VERSION ""

NS_ :

BS_:

BU_: ALARMS_RELAY RUR RUF LOGBOX HVAC CP6 CP10 RUC BC BMS1_SDB BMS2_SDB BMS0_SDB _TESTER NC_SENSOR IVS

BO_ 2558533943 CP10_2_BC_1: 8 CP10
 SG_ Btn_FuelPumpCP10 : 9|1@1+ (1,0) [0|0] "-"  LOGBOX,BC
 SG_ Btn_EngineHeater_CP10 : 10|1@1+ (1,0) [0|1] "-"  LOGBOX,BC
 SG_ Btn_ParkingBrake_CP10 : 38|1@1+ (1,0) [0|1] "-"  LOGBOX,BC
 SG_ Btn_Dust_Fan_CP10 : 8|1@1+ (1,0) [0|1] "-"  LOGBOX,BC
 SG_ Btn_Warlight_B2_CP10 : 6|1@1+ (1,0) [0|1] "-"  LOGBOX,BC
 SG_ Btn_Warlight_B1_CP10 : 5|1@1+ (1,0) [0|1] "-"  LOGBOX,BC
 SG_ Btn_TripReset_CP10 : 14|1@1+ (1,0) [0|1] "-"  LOGBOX,BC
 SG_ Btn_Retarder_Up_CP10 : 33|1@1+ (1,0) [0|1] "-"  LOGBOX,BC
 SG_ Btn_Retarder_Off_CP10 : 32|1@1+ (1,0) [0|1] "-"  LOGBOX,BC
 SG_ Btn_Retarder_Down_CP10 : 34|1@1+ (1,0) [0|1] "-"  LOGBOX,BC
 SG_ Btn_Marker_Light_CP10 : 2|1@1+ (1,0) [0|1] "-"  LOGBOX,BC
 SG_ Btn_Low_Beam_Light_CP10 : 3|1@1+ (1,0) [0|1] "-"  LOGBOX,BC
 SG_ Btn_Lock_Front_Diff_CP10 : 25|1@1+ (1,0) [0|1] "-"  LOGBOX,BC
 SG_ Btn_Ford_Mode_CP10 : 11|1@1+ (1,0) [0|1] "-"  LOGBOX,BC
 SG_ Btn_Emergency_Blinker_CP10 : 0|1@1+ (1,0) [0|1] "-"  LOGBOX,BC
 SG_ Btn_CTIS_Track_CP10 : 42|1@1+ (1,0) [0|1] "-"  LOGBOX,BC
 SG_ Btn_CTIS_Sand_CP10 : 43|1@1+ (1,0) [0|1] "-"  LOGBOX,BC
 SG_ Btn_CTIS_Road_CP10 : 41|1@1+ (1,0) [0|1] "-"  LOGBOX,BC
 SG_ Btn_CTIS_ON_CP10 : 40|1@1+ (1,0) [0|1] "-"  LOGBOX,BC
 SG_ Btn_CTIS_Load_CP10 : 45|1@1+ (1,0) [0|1] "-"  LOGBOX,BC
 SG_ Btn_CTIS_Emergency_CP10 : 44|1@1+ (1,0) [0|1] "-"  LOGBOX,BC
 SG_ Btn_CTIS_Check_CP10 : 46|1@1+ (1,0) [0|1] "-"  LOGBOX,BC
 SG_ Btn_Bilge_Pump_EngineBay_CP10 : 12|1@1+ (1,0) [0|1] "-"  LOGBOX,BC
 SG_ Btn_All_Wheel_Drive_CP10 : 24|1@1+ (1,0) [0|1] "-"  LOGBOX,BC
 SG_ Btn_4th_Steering_Axle_CP10 : 26|1@1+ (1,0) [0|1] "-"  LOGBOX,BC
 SG_ _nu_Btn_2_01_CP10 : 1|1@1+ (1,0) [0|1] "-"  LOGBOX
 SG_ _nu_Btn_2_04_CP10 : 4|1@1+ (1,0) [0|1] "-"  LOGBOX
 SG_ _nu_Btn_2_07_CP10 : 7|1@1+ (1,0) [0|1] "-"  LOGBOX
 SG_ Btn_Change_h_km_CP10 : 13|1@1+ (1,0) [0|1] "-"  LOGBOX,BC
 SG_ _nu_Btn_2_15_CP10 : 15|1@1+ (1,0) [0|1] "-"  LOGBOX
 SG_ _nu_Btn_2_16_CP10 : 16|1@1+ (1,0) [0|1] "-"  LOGBOX
 SG_ _nu_Btn_2_17_CP10 : 17|1@1+ (1,0) [0|1] "-"  LOGBOX
 SG_ _nu_Btn_2_18_CP10 : 18|1@1+ (1,0) [0|1] "-"  LOGBOX
 SG_ _nu_Btn_2_19_CP10 : 19|1@1+ (1,0) [0|1] "-"  LOGBOX
 SG_ _nu_Btn_2_20_CP10 : 20|1@1+ (1,0) [0|1] "-"  LOGBOX
 SG_ _nu_Btn_2_21_CP10 : 21|1@1+ (1,0) [0|1] "-"  LOGBOX
 SG_ _nu_Btn_2_22_CP10 : 22|1@1+ (1,0) [0|1] "-"  LOGBOX
 SG_ _nu_Btn_2_23_CP10 : 23|1@1+ (1,0) [0|1] "-"  LOGBOX
 SG_ _nu_Btn_2_27_CP10 : 27|1@1+ (1,0) [0|1] "-"  LOGBOX
 SG_ _nu_Btn_2_28_CP10 : 28|1@1+ (1,0) [0|1] "-"  LOGBOX
 SG_ _nu_Btn_2_29_CP10 : 29|1@1+ (1,0) [0|1] "-"  LOGBOX
 SG_ _nu_Btn_2_30_CP10 : 30|1@1+ (1,0) [0|1] "-"  LOGBOX
 SG_ _nu_Btn_2_31_CP10 : 31|1@1+ (1,0) [0|1] "-"  LOGBOX
 SG_ _nu_Btn_2_35_CP10 : 35|1@1+ (1,0) [0|1] "-"  LOGBOX
 SG_ _nu_Btn_2_36_CP10 : 36|1@1+ (1,0) [0|1] "-"  LOGBOX
 SG_ _nu_Btn_2_37_CP10 : 37|1@1+ (1,0) [0|1] "-"  LOGBOX
 SG_ _nu_Btn_2_39_CP10 : 39|1@1+ (1,0) [0|1] "-"  LOGBOX
 SG_ _nu_Btn_2_47_CP10 : 47|1@1+ (1,0) [0|1] "-"  LOGBOX
 SG_ _nu_Btn_2_48_CP10 : 48|1@1+ (1,0) [0|1] "-"  LOGBOX
 SG_ _nu_Btn_2_49_CP10 : 49|1@1+ (1,0) [0|1] "-"  LOGBOX
 SG_ _nu_Btn_2_50_CP10 : 50|1@1+ (1,0) [0|1] "-"  LOGBOX
 SG_ _nu_Btn_2_51_CP10 : 51|1@1+ (1,0) [0|1] "-"  LOGBOX
 SG_ _nu_Btn_2_52_CP10 : 52|1@1+ (1,0) [0|1] "-"  LOGBOX
 SG_ _nu_Btn_2_53_CP10 : 53|1@1+ (1,0) [0|1] "-"  LOGBOX
 SG_ _nu_Btn_2_54_CP10 : 54|1@1+ (1,0) [0|1] "-"  LOGBOX
 SG_ _nu_Btn_2_55_CP10 : 55|1@1+ (1,0) [0|1] "-"  LOGBOX
 SG_ _nu_Btn_2_56_CP10 : 56|1@1+ (1,0) [0|1] "-"  LOGBOX
 SG_ _nu_Btn_2_57_CP10 : 57|1@1+ (1,0) [0|1] "-"  LOGBOX
 SG_ _nu_Btn_2_58_CP10 : 58|1@1+ (1,0) [0|1] "-"  LOGBOX
 SG_ _nu_Btn_2_59_CP10 : 59|1@1+ (1,0) [0|1] "-"  LOGBOX
 SG_ _nu_Btn_2_60_CP10 : 60|1@1+ (1,0) [0|1] "-"  LOGBOX
 SG_ _nu_Btn_2_61_CP10 : 61|1@1+ (1,0) [0|1] "-"  LOGBOX
 SG_ _nu_Btn_2_62_CP10 : 62|1@1+ (1,0) [0|1] "-"  LOGBOX
 SG_ _nu_Btn_2_63_CP10 : 63|1@1+ (1,0) [0|1] "-"  LOGBOX

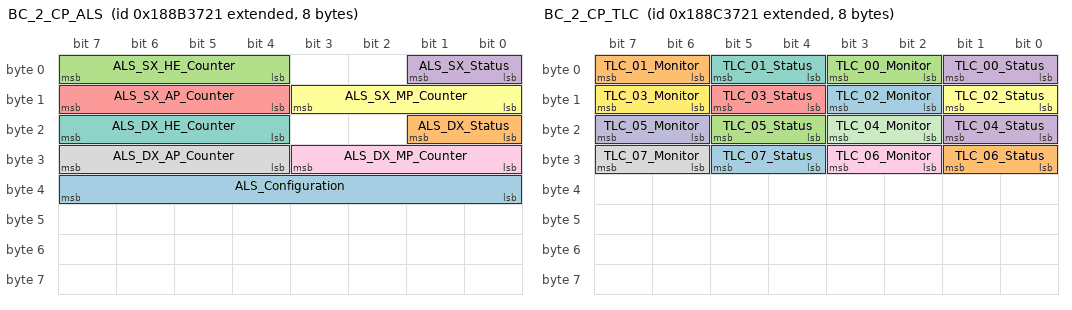
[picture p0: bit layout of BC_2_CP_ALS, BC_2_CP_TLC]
BO_ 2559260449 BC_2_CP_ALS: 8 BC
 SG_ ALS_Configuration : 32|8@1+ (1,0) [0|3] "-"  IVS
 SG_ ALS_DX_Status : 16|2@1+ (1,0) [0|3] "-"  IVS,CP6,CP10,LOGBOX
 SG_ ALS_SX_HE_Counter : 4|4@1+ (1,0) [0|15] "-"  IVS,CP6,CP10,LOGBOX
 SG_ ALS_SX_Status : 0|2@1+ (1,0) [0|3] "-"  IVS,CP6,CP10,LOGBOX
 SG_ ALS_SX_AP_Counter : 12|4@1+ (1,0) [0|15] "-"  IVS,CP6,CP10,LOGBOX
 SG_ ALS_SX_MP_Counter : 8|4@1+ (1,0) [0|15] "-"  IVS,CP6,CP10,LOGBOX
 SG_ ALS_DX_HE_Counter : 20|4@1+ (1,0) [0|15] "-"  IVS,CP6,CP10,LOGBOX
 SG_ ALS_DX_AP_Counter : 28|4@1+ (1,0) [0|15] "-"  IVS,CP6,CP10,LOGBOX
 SG_ ALS_DX_MP_Counter : 24|4@1+ (1,0) [0|15] "-"  IVS,CP6,CP10,LOGBOX

BO_ 2559325985 BC_2_CP_TLC: 8 BC
 SG_ TLC_07_Status : 28|2@1+ (1,0) [0|3] "-"  CP6,CP10,LOGBOX
 SG_ TLC_06_Status : 24|2@1+ (1,0) [0|3] "-"  CP6,CP10,LOGBOX
 SG_ TLC_05_Status : 20|2@1+ (1,0) [0|3] "-"  CP6,CP10,LOGBOX
 SG_ TLC_04_Status : 16|2@1+ (1,0) [0|3] "-"  CP6,CP10,LOGBOX
 SG_ TLC_03_Status : 12|2@1+ (1,0) [0|3] "-"  CP6,CP10,LOGBOX
 SG_ TLC_02_Status : 8|2@1+ (1,0) [0|3] "-"  CP6,CP10,LOGBOX
 SG_ TLC_01_Status : 4|2@1+ (1,0) [0|3] "-"  CP6,CP10,LOGBOX
 SG_ TLC_07_Monitor : 30|2@1+ (1,0) [0|3] "-"  CP6,CP10,LOGBOX
 SG_ TLC_06_Monitor : 26|2@1+ (1,0) [0|3] "-"  CP6,CP10,LOGBOX
 SG_ TLC_05_Monitor : 22|2@1+ (1,0) [0|3] "-"  CP6,CP10,LOGBOX
 SG_ TLC_04_Monitor : 18|2@1+ (1,0) [0|3] "-"  CP6,CP10,LOGBOX
 SG_ TLC_03_Monitor : 14|2@1+ (1,0) [0|3] "-"  CP6,CP10,LOGBOX
 SG_ TLC_02_Monitor : 10|2@1+ (1,0) [0|3] "-"  CP6,CP10,LOGBOX
 SG_ TLC_01_Monitor : 6|2@1+ (1,0) [0|3] "-"  CP6,CP10,LOGBOX
 SG_ TLC_00_Monitor : 2|2@1+ (1,0) [0|3] "-"  CP6,CP10,LOGBOX
 SG_ TLC_00_Status : 0|2@1+ (1,0) [0|3] "-"  CP6,CP10,LOGBOX

BO_ 2558590913 NC_Sensor_Status: 8 NC_SENSOR
 SG_ C_Sensor_Status : 0|4@1+ (1,0) [0|15] "-"  BC,LOGBOX
 SG_ Class5_Value : 44|4@1+ (1,0) [0|8] "bars"  BC,LOGBOX
 SG_ Class5_Type : 40|4@1+ (1,0) [0|4] "-"  BC,LOGBOX
 SG_ Class4_Value : 36|4@1+ (1,0) [0|8] "bars"  BC,LOGBOX
 SG_ Class4_Type : 32|4@1+ (1,0) [0|4] "-"  BC,LOGBOX
 SG_ Class3_Value : 28|4@1+ (1,0) [0|8] "bars"  BC,LOGBOX
 SG_ Class3_Type : 24|4@1+ (1,0) [0|4] "-"  BC,LOGBOX
 SG_ Class2_Value : 20|4@1+ (1,0) [0|8] "bars"  BC,LOGBOX
 SG_ Class2_Type : 16|4@1+ (1,0) [0|4] "-"  BC,LOGBOX
 SG_ Class1_Value : 12|4@1+ (1,0) [0|8] "bars"  BC,LOGBOX
 SG_ Class1_Type : 8|4@1+ (1,0) [0|4] "-"  BC,LOGBOX
 SG_ C_Alarm_Status : 4|4@1+ (1,0) [0|15] "-"  BC,LOGBOX
 SG_ N_Sensor_Alarm : 48|1@1+ (1,0) [0|1] "-"  BC,LOGBOX
 SG_ N_DoseRateAlarm : 49|1@1+ (1,0) [0|1] "-"  BC,LOGBOX
 SG_ N_DoseAlarm : 50|1@1+ (1,0) [0|1] "-"  BC,LOGBOX
 SG_ N_Current_Unit : 51|1@1+ (1,0) [0|1] "-"  BC,LOGBOX
 SG_ N_GPS_detected : 52|1@1+ (1,0) [0|1] "-"  BC,LOGBOX
 SG_ Reserved_01 : 53|1@1+ (1,0) [0|0] "-"  BC,LOGBOX
 SG_ Reserved_02 : 54|1@1+ (1,0) [0|0] "-"  BC,LOGBOX
 SG_ Reserved_03 : 55|1@1+ (1,0) [0|0] "-"  BC,LOGBOX
 SG_ N_Sensor_Error : 60|1@1+ (1,0) [0|1] "-"  BC,LOGBOX
 SG_ N_GDR_Module_Error : 61|1@1+ (1,0) [0|1] "-"  BC,LOGBOX
 SG_ N_Voltage_Module_Error : 62|1@1+ (1,0) [0|1] "-"  BC,LOGBOX
 SG_ Reserved_04 : 56|1@1+ (1,0) [0|0] "-"  BC,LOGBOX
 SG_ Reserved_05 : 57|1@1+ (1,0) [0|0] "-"  BC,LOGBOX
 SG_ Reserved_06 : 58|1@1+ (1,0) [0|0] "-"  BC,LOGBOX
 SG_ Reserved_07 : 59|1@1+ (1,0) [0|0] "-"  BC,LOGBOX
 SG_ Reserved_08 : 63|1@1+ (1,0) [0|0] "-"  BC,LOGBOX

BO_ 2558721985 N_Sensor_Counter: 8 NC_SENSOR
 SG_ Radiation : 32|32@1- (1,0) [-3.4E+038|3.4E+038] "cGy"  LOGBOX
 SG_ Radiation_Rate : 0|32@1- (1,0) [-3.4E+038|3.4E+038] "cGy/h"  LOGBOX

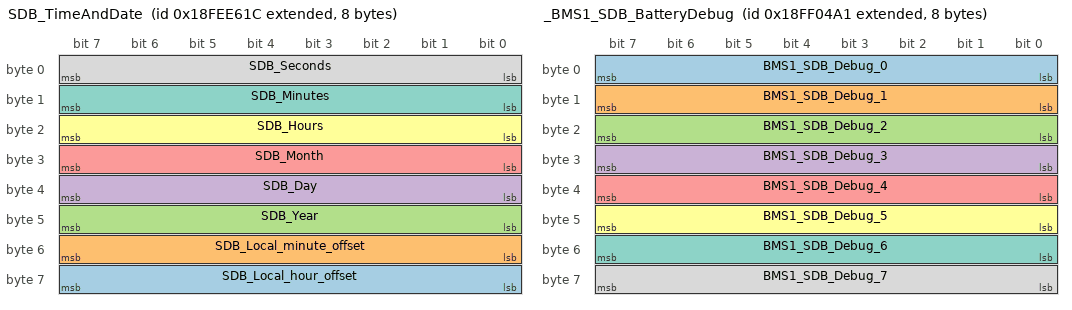
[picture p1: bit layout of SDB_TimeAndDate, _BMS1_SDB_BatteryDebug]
BO_ 2566841884 SDB_TimeAndDate: 8 LOGBOX
 SG_ SDB_Local_hour_offset : 56|8@1+ (1,-125) [-23|23] "hr"  LOGBOX
 SG_ SDB_Local_minute_offset : 48|8@1+ (1,-125) [-125|125] "min"  LOGBOX
 SG_ SDB_Year : 40|8@1+ (1,1985) [1985|2235] "-"  LOGBOX
 SG_ SDB_Day : 32|8@1+ (0.25,0.75) [0.25|31.75] "-"  LOGBOX
 SG_ SDB_Month : 24|8@1+ (1,0) [1|12] "-"  LOGBOX
 SG_ SDB_Hours : 16|8@1+ (1,0) [0|23] "hr"  LOGBOX
 SG_ SDB_Minutes : 8|8@1+ (1,0) [0|59] "min"  LOGBOX
 SG_ SDB_Seconds : 0|8@1+ (0.25,0) [0|59.75] "sec"  LOGBOX

BO_ 2566849953 BMS1_SDB_BatterySummaryStatus: 8 BMS1_SDB
 SG_ BMS1_SDB_BatSumS_serial_number : 0|24@1+ (1,0) [0|16777214] "-"  BC,LOGBOX
 SG_ BMS1_SDB_BatSumS_Reserved_01 : 24|8@1+ (1,0) [0|255] "-"  LOGBOX
 SG_ BMS1_SDB_BatSumS_State_of_Charge : 32|8@1+ (1,0) [0|100] "%"  LOGBOX,BC
 SG_ BMS1_SDB_BatSumS_State_of_Health : 40|8@1+ (1,0) [0|2] "-"  LOGBOX,BC
 SG_ BMS1_SDB_BatSumS_Temp_Alarm : 48|2@1+ (1,0) [0|3] "-"  LOGBOX,BC
 SG_ BMS1_SDB_BatSumS_DischargeDis : 50|1@1+ (1,0) [0|1] "-"  LOGBOX,BC
 SG_ BMS1_SDB_BatSumS_ChargingDisable : 51|1@1+ (1,0) [0|1] "-"  LOGBOX,BC
 SG_ BMS1_SDB_BatSumS_HeaterEnabled : 52|1@1+ (1,0) [0|1] "-"  LOGBOX,BC
 SG_ BMS1_SDB_BatSumS_BypassEnabled : 53|1@1+ (1,0) [0|1] "-"  LOGBOX,BC
 SG_ BMS1_SDB_BatSumS_Voltage_Alarm : 56|1@1+ (1,0) [0|1] "-"  LOGBOX,BC
 SG_ BMS1_SDB_BatSumS_Reserved_04 : 54|2@1+ (1,0) [0|3] "-"  LOGBOX
 SG_ BMS1_SDB_BatSumS_Reserved_05 : 57|1@1+ (1,0) [0|1] "-"  LOGBOX,BC
 SG_ BMS1_SDB_BatSumS_Reserved_06 : 58|1@1+ (1,0) [0|1] "-"  LOGBOX
 SG_ BMS1_SDB_BatSumS_Reserved_07 : 59|1@1+ (1,0) [0|1] "-"  LOGBOX
 SG_ BMS1_SDB_BatSumS_Reserved_08 : 60|1@1+ (1,0) [0|1] "-"  LOGBOX
 SG_ BMS1_SDB_BatSumS_Reserved_09 : 61|1@1+ (1,0) [0|1] "-"  LOGBOX
 SG_ BMS1_SDB_BatSumS_Reserved_10 : 62|1@1+ (1,0) [0|1] "-"  LOGBOX
 SG_ BMS1_SDB_BatSumS_Reserved_11 : 63|1@1+ (1,0) [0|1] "-"  LOGBOX

BO_ 2566849697 _BMS1_SDB_BatteryDebug: 8 BMS1_SDB
 SG_ BMS1_SDB_Debug_0 : 0|8@1+ (1,0) [0|255] "-"  LOGBOX
 SG_ BMS1_SDB_Debug_1 : 8|8@1+ (1,0) [0|255] "-"  LOGBOX
 SG_ BMS1_SDB_Debug_2 : 16|8@1+ (1,0) [0|255] "-"  LOGBOX
 SG_ BMS1_SDB_Debug_3 : 24|8@1+ (1,0) [0|255] "-"  LOGBOX
 SG_ BMS1_SDB_Debug_4 : 32|8@1+ (1,0) [0|255] "-"  LOGBOX
 SG_ BMS1_SDB_Debug_5 : 40|8@1+ (1,0) [0|255] "-"  LOGBOX
 SG_ BMS1_SDB_Debug_6 : 48|8@1+ (1,0) [0|255] "-"  LOGBOX
 SG_ BMS1_SDB_Debug_7 : 56|8@1+ (1,0) [0|255] "-"  LOGBOX

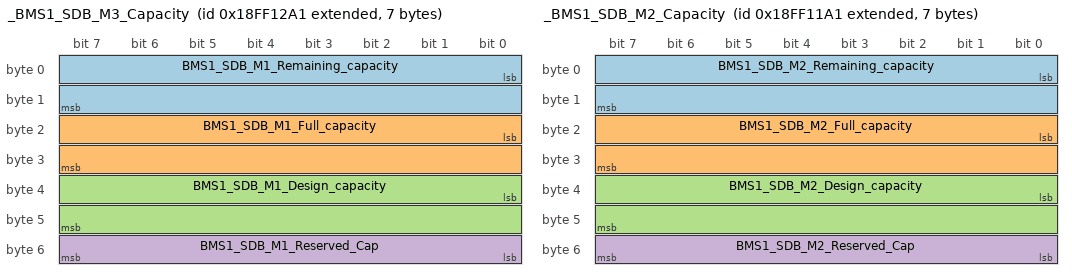
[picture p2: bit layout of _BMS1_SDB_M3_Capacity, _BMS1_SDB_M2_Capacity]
BO_ 2566853281 _BMS1_SDB_M3_Capacity: 7 BMS1_SDB
 SG_ BMS1_SDB_M1_Remaining_capacity : 0|16@1+ (0.01,0) [0|642.55] "Ah"  LOGBOX
 SG_ BMS1_SDB_M1_Full_capacity : 16|16@1+ (0.01,0) [0|642.55] "Ah"  LOGBOX
 SG_ BMS1_SDB_M1_Design_capacity : 32|16@1+ (0.01,0) [0|642.55] "Ah"  LOGBOX
 SG_ BMS1_SDB_M1_Reserved_Cap : 48|8@1+ (1,0) [255|255] "-"  LOGBOX

BO_ 2566853025 _BMS1_SDB_M2_Capacity: 7 BMS1_SDB
 SG_ BMS1_SDB_M2_Remaining_capacity : 0|16@1+ (0.01,0) [0|642.55] "Ah"  LOGBOX
 SG_ BMS1_SDB_M2_Full_capacity : 16|16@1+ (0.01,0) [0|642.55] "Ah"  LOGBOX
 SG_ BMS1_SDB_M2_Design_capacity : 32|16@1+ (0.01,0) [0|642.55] "Ah"  LOGBOX
 SG_ BMS1_SDB_M2_Reserved_Cap : 48|8@1+ (1,0) [255|255] "-"  LOGBOX

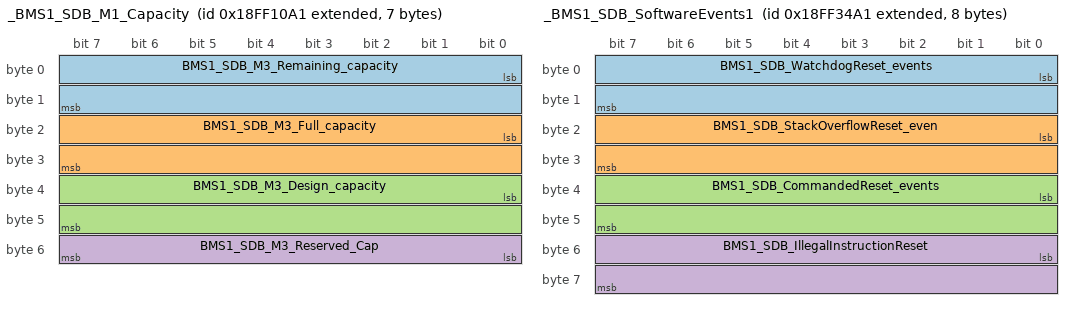
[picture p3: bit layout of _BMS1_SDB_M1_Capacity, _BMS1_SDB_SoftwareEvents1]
BO_ 2566852769 _BMS1_SDB_M1_Capacity: 7 BMS1_SDB
 SG_ BMS1_SDB_M3_Remaining_capacity : 0|16@1+ (0.01,0) [0|642.55] "Ah"  LOGBOX
 SG_ BMS1_SDB_M3_Full_capacity : 16|16@1+ (0.01,0) [0|642.55] "Ah"  LOGBOX
 SG_ BMS1_SDB_M3_Design_capacity : 32|16@1+ (0.01,0) [0|642.55] "Ah"  LOGBOX
 SG_ BMS1_SDB_M3_Reserved_Cap : 48|8@1+ (1,0) [255|255] "-"  LOGBOX

BO_ 2566861985 _BMS1_SDB_SoftwareEvents1: 8 BMS1_SDB
 SG_ BMS1_SDB_WatchdogReset_events : 0|16@1+ (1,0) [0|64255] "-"  LOGBOX
 SG_ BMS1_SDB_StackOverflowReset_even : 16|16@1+ (1,0) [0|64255] "-"  LOGBOX
 SG_ BMS1_SDB_CommandedReset_events : 32|16@1+ (1,0) [0|64255] "-"  LOGBOX
 SG_ BMS1_SDB_IllegalInstructionReset : 48|16@1+ (1,0) [0|64255] "-"  LOGBOX

BO_ 2566861729 _BMS1_SDB_VoltageEvents: 4 BMS1_SDB
 SG_ BMS1_SDB_OverVoltage_events : 0|16@1+ (1,0) [0|64255] "-"  LOGBOX
 SG_ BMS1_SDB_UnderVoltage_events : 16|16@1+ (1,0) [0|64255] "-"  LOGBOX

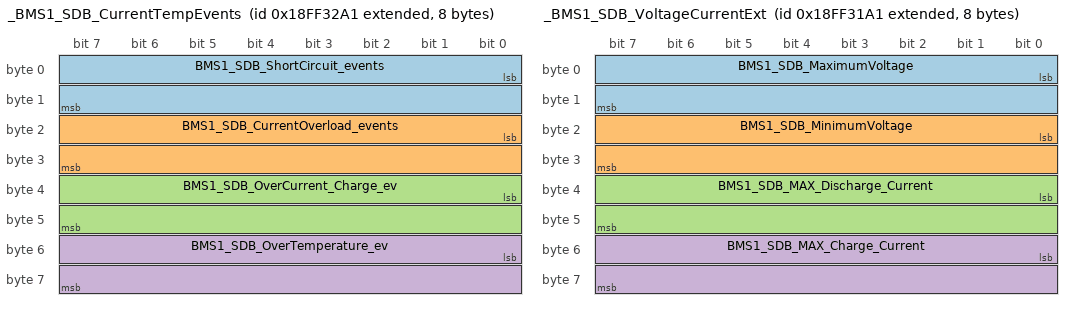
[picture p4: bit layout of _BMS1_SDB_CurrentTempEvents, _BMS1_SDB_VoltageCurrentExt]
BO_ 2566861473 _BMS1_SDB_CurrentTempEvents: 8 BMS1_SDB
 SG_ BMS1_SDB_ShortCircuit_events : 0|16@1+ (1,0) [0|64255] "-"  LOGBOX
 SG_ BMS1_SDB_CurrentOverload_events : 16|16@1+ (1,0) [0|64255] "-"  LOGBOX
 SG_ BMS1_SDB_OverCurrent_Charge_ev : 32|16@1+ (1,0) [0|64255] "-"  LOGBOX
 SG_ BMS1_SDB_OverTemperature_ev : 48|16@1+ (1,0) [0|64255] "-"  LOGBOX

BO_ 2566861217 _BMS1_SDB_VoltageCurrentExt: 8 BMS1_SDB
 SG_ BMS1_SDB_MaximumVoltage : 0|16@1+ (0.001,0) [0|64255] "V"  LOGBOX
 SG_ BMS1_SDB_MinimumVoltage : 16|16@1+ (0.001,0) [0|64255] "V"  LOGBOX
 SG_ BMS1_SDB_MAX_Discharge_Current : 32|16@1+ (0.1,0) [0|6425.5] "A"  LOGBOX
 SG_ BMS1_SDB_MAX_Charge_Current : 48|16@1+ (0.1,0) [0|6425.5] "A"  LOGBOX

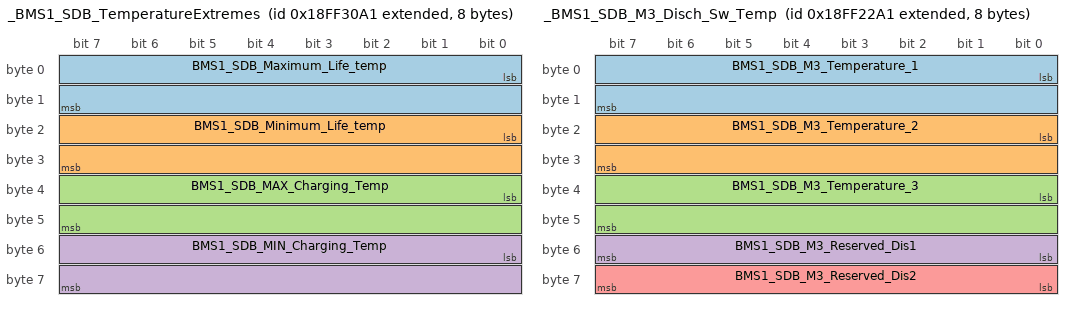
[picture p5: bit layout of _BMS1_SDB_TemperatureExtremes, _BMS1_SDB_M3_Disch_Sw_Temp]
BO_ 2566860961 _BMS1_SDB_TemperatureExtremes: 8 BMS1_SDB
 SG_ BMS1_SDB_Maximum_Life_temp : 0|16@1+ (0.1,-100) [-100|200] "°C"  LOGBOX
 SG_ BMS1_SDB_Minimum_Life_temp : 16|16@1+ (0.1,-100) [-100|200] "°C"  LOGBOX
 SG_ BMS1_SDB_MAX_Charging_Temp : 32|16@1+ (0.1,-100) [-100|200] "°C"  LOGBOX
 SG_ BMS1_SDB_MIN_Charging_Temp : 48|16@1+ (0.1,-100) [-100|200] "°C"  LOGBOX

BO_ 2566857377 _BMS1_SDB_M3_Disch_Sw_Temp: 8 BMS1_SDB
 SG_ BMS1_SDB_M3_Temperature_1 : 0|16@1+ (0.1,-100) [-100|200] "°C"  LOGBOX
 SG_ BMS1_SDB_M3_Temperature_2 : 16|16@1+ (0.1,-100) [-100|200] "°C"  LOGBOX
 SG_ BMS1_SDB_M3_Temperature_3 : 32|16@1+ (0.1,-100) [-100|200] "°C"  LOGBOX
 SG_ BMS1_SDB_M3_Reserved_Dis1 : 48|8@1+ (1,0) [255|255] "-"  LOGBOX
 SG_ BMS1_SDB_M3_Reserved_Dis2 : 56|8@1+ (1,0) [255|255] "-"  LOGBOX

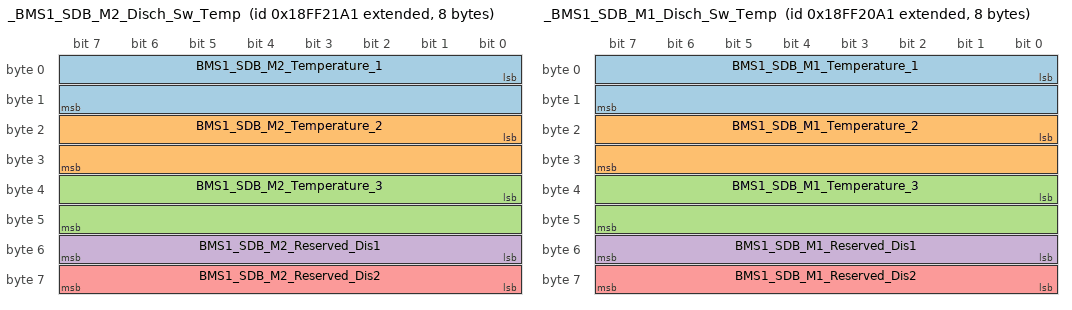
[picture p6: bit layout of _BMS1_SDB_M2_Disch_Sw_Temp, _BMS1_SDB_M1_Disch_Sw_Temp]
BO_ 2566857121 _BMS1_SDB_M2_Disch_Sw_Temp: 8 BMS1_SDB
 SG_ BMS1_SDB_M2_Temperature_1 : 0|16@1+ (0.1,-100) [-100|200] "°C"  LOGBOX
 SG_ BMS1_SDB_M2_Temperature_2 : 16|16@1+ (0.1,-100) [-100|200] "°C"  LOGBOX
 SG_ BMS1_SDB_M2_Temperature_3 : 32|16@1+ (0.1,-100) [-100|200] "°C"  LOGBOX
 SG_ BMS1_SDB_M2_Reserved_Dis1 : 48|8@1+ (1,0) [255|255] "-"  LOGBOX
 SG_ BMS1_SDB_M2_Reserved_Dis2 : 56|8@1+ (1,0) [255|255] "-"  LOGBOX

BO_ 2566856865 _BMS1_SDB_M1_Disch_Sw_Temp: 8 BMS1_SDB
 SG_ BMS1_SDB_M1_Temperature_1 : 0|16@1+ (0.1,-100) [-100|200] "°C"  LOGBOX
 SG_ BMS1_SDB_M1_Temperature_2 : 16|16@1+ (0.1,-100) [-100|200] "°C"  LOGBOX
 SG_ BMS1_SDB_M1_Temperature_3 : 32|16@1+ (0.1,-100) [-100|200] "°C"  LOGBOX
 SG_ BMS1_SDB_M1_Reserved_Dis1 : 48|8@1+ (1,0) [255|255] "-"  LOGBOX
 SG_ BMS1_SDB_M1_Reserved_Dis2 : 56|8@1+ (1,0) [255|255] "-"  LOGBOX

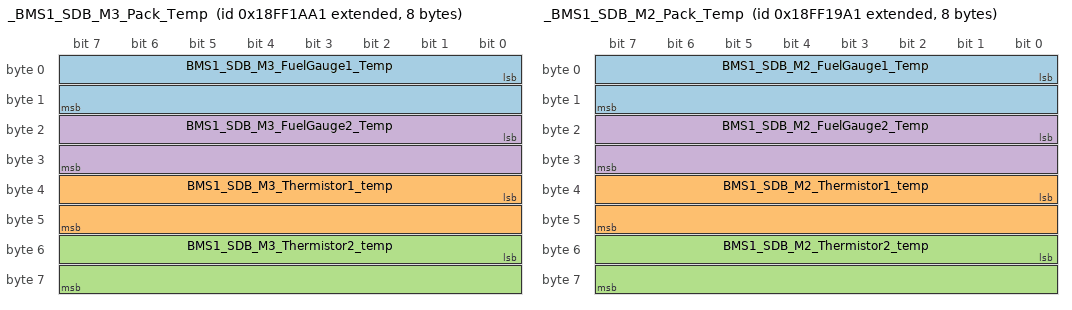
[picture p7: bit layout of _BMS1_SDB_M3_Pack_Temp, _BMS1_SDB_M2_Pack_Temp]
BO_ 2566855329 _BMS1_SDB_M3_Pack_Temp: 8 BMS1_SDB
 SG_ BMS1_SDB_M3_FuelGauge1_Temp : 0|16@1+ (0.1,-100) [-100|200] "°C"  LOGBOX
 SG_ BMS1_SDB_M3_Thermistor1_temp : 32|16@1+ (0.1,-100) [-100|200] "-"  LOGBOX
 SG_ BMS1_SDB_M3_Thermistor2_temp : 48|16@1+ (0.1,-100) [-100|200] "-"  LOGBOX
 SG_ BMS1_SDB_M3_FuelGauge2_Temp : 16|16@1+ (0.1,-100) [-100|200] "°C"  LOGBOX

BO_ 2566855073 _BMS1_SDB_M2_Pack_Temp: 8 BMS1_SDB
 SG_ BMS1_SDB_M2_FuelGauge1_Temp : 0|16@1+ (0.1,-100) [-100|200] "°C"  LOGBOX
 SG_ BMS1_SDB_M2_Thermistor1_temp : 32|16@1+ (0.1,-100) [-100|200] "-"  LOGBOX
 SG_ BMS1_SDB_M2_Thermistor2_temp : 48|16@1+ (0.1,-100) [-100|200] "-"  LOGBOX
 SG_ BMS1_SDB_M2_FuelGauge2_Temp : 16|16@1+ (0.1,-100) [-100|200] "°C"  LOGBOX

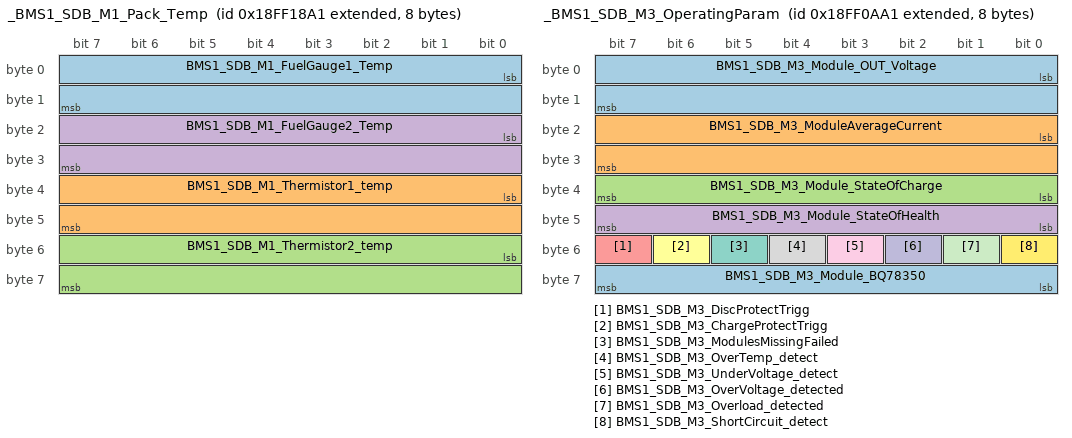
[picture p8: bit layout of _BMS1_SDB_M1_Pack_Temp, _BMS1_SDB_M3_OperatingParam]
BO_ 2566854817 _BMS1_SDB_M1_Pack_Temp: 8 BMS1_SDB
 SG_ BMS1_SDB_M1_FuelGauge1_Temp : 0|16@1+ (0.1,-100) [-100|200] "°C"  LOGBOX
 SG_ BMS1_SDB_M1_Thermistor1_temp : 32|16@1+ (0.1,-100) [-100|200] "-"  LOGBOX
 SG_ BMS1_SDB_M1_Thermistor2_temp : 48|16@1+ (0.1,-100) [-100|200] "-"  LOGBOX
 SG_ BMS1_SDB_M1_FuelGauge2_Temp : 16|16@1+ (0.1,-100) [-100|200] "°C"  LOGBOX

BO_ 2566851233 _BMS1_SDB_M3_OperatingParam: 8 BMS1_SDB
 SG_ BMS1_SDB_M3_Module_OUT_Voltage : 0|16@1+ (0.001,0) [0|64255] "V"  LOGBOX
 SG_ BMS1_SDB_M3_ModuleAverageCurrent : 16|16@1+ (0.1,-5500) [-5500|925.5] "A"  LOGBOX
 SG_ BMS1_SDB_M3_Module_StateOfCharge : 32|8@1+ (1,0) [0|100] "%"  LOGBOX
 SG_ BMS1_SDB_M3_Module_StateOfHealth : 40|8@1+ (1,0) [0|2] "-"  LOGBOX
 SG_ BMS1_SDB_M3_DiscProtectTrigg : 55|1@1+ (1,0) [0|1] "-"  LOGBOX
 SG_ BMS1_SDB_M3_ChargeProtectTrigg : 54|1@1+ (1,0) [0|1] "-"  LOGBOX
 SG_ BMS1_SDB_M3_ModulesMissingFailed : 53|1@1+ (1,0) [0|1] "-"  LOGBOX
 SG_ BMS1_SDB_M3_OverTemp_detect : 52|1@1+ (1,0) [0|1] "-"  LOGBOX
 SG_ BMS1_SDB_M3_UnderVoltage_detect : 51|1@1+ (1,0) [0|1] "-"  LOGBOX
 SG_ BMS1_SDB_M3_OverVoltage_detected : 50|1@1+ (1,0) [0|1] "-"  LOGBOX
 SG_ BMS1_SDB_M3_Overload_detected : 49|1@1+ (1,0) [0|1] "-"  LOGBOX
 SG_ BMS1_SDB_M3_ShortCircuit_detect : 48|1@1+ (1,0) [0|1] "-"  LOGBOX
 SG_ BMS1_SDB_M3_Module_BQ78350 : 56|8@1+ (1,0) [0|2] "-"  LOGBOX

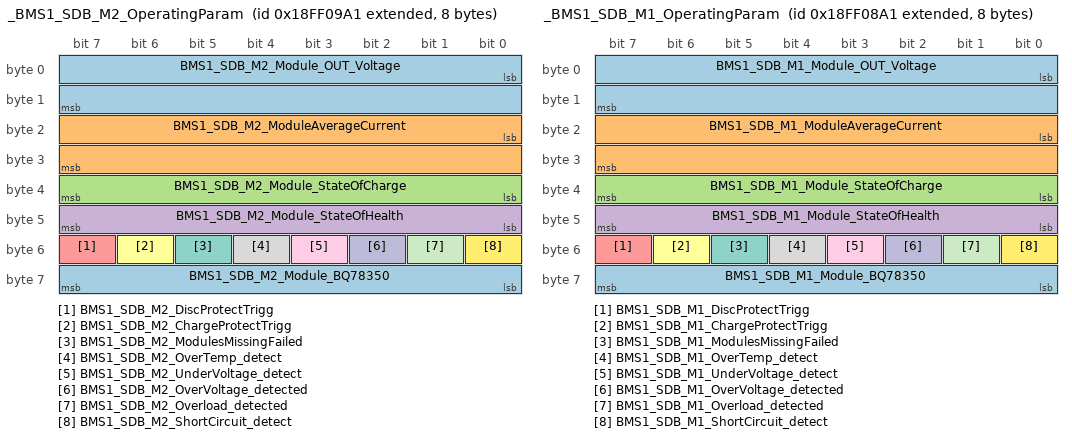
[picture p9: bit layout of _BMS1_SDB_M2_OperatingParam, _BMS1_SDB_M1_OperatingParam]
BO_ 2566850977 _BMS1_SDB_M2_OperatingParam: 8 BMS1_SDB
 SG_ BMS1_SDB_M2_Module_OUT_Voltage : 0|16@1+ (0.001,0) [0|64255] "V"  LOGBOX
 SG_ BMS1_SDB_M2_ModuleAverageCurrent : 16|16@1+ (0.1,-5500) [-5500|925.5] "A"  LOGBOX
 SG_ BMS1_SDB_M2_Module_StateOfCharge : 32|8@1+ (1,0) [0|100] "%"  LOGBOX
 SG_ BMS1_SDB_M2_Module_StateOfHealth : 40|8@1+ (1,0) [0|2] "-"  LOGBOX
 SG_ BMS1_SDB_M2_DiscProtectTrigg : 55|1@1+ (1,0) [0|1] "-"  LOGBOX
 SG_ BMS1_SDB_M2_ChargeProtectTrigg : 54|1@1+ (1,0) [0|1] "-"  LOGBOX
 SG_ BMS1_SDB_M2_ModulesMissingFailed : 53|1@1+ (1,0) [0|1] "-"  LOGBOX
 SG_ BMS1_SDB_M2_OverTemp_detect : 52|1@1+ (1,0) [0|1] "-"  LOGBOX
 SG_ BMS1_SDB_M2_UnderVoltage_detect : 51|1@1+ (1,0) [0|1] "-"  LOGBOX
 SG_ BMS1_SDB_M2_OverVoltage_detected : 50|1@1+ (1,0) [0|1] "-"  LOGBOX
 SG_ BMS1_SDB_M2_Overload_detected : 49|1@1+ (1,0) [0|1] "-"  LOGBOX
 SG_ BMS1_SDB_M2_ShortCircuit_detect : 48|1@1+ (1,0) [0|1] "-"  LOGBOX
 SG_ BMS1_SDB_M2_Module_BQ78350 : 56|8@1+ (1,0) [0|2] "-"  LOGBOX

BO_ 2566850721 _BMS1_SDB_M1_OperatingParam: 8 BMS1_SDB
 SG_ BMS1_SDB_M1_Module_OUT_Voltage : 0|16@1+ (0.001,0) [0|64255] "V"  LOGBOX
 SG_ BMS1_SDB_M1_ModuleAverageCurrent : 16|16@1+ (0.1,-5500) [-5500|925.5] "A"  LOGBOX
 SG_ BMS1_SDB_M1_Module_StateOfCharge : 32|8@1+ (1,0) [0|100] "%"  LOGBOX
 SG_ BMS1_SDB_M1_Module_StateOfHealth : 40|8@1+ (1,0) [0|2] "-"  LOGBOX
 SG_ BMS1_SDB_M1_DiscProtectTrigg : 55|1@1+ (1,0) [0|1] "-"  LOGBOX
 SG_ BMS1_SDB_M1_ChargeProtectTrigg : 54|1@1+ (1,0) [0|1] "-"  LOGBOX
 SG_ BMS1_SDB_M1_ModulesMissingFailed : 53|1@1+ (1,0) [0|1] "-"  LOGBOX
 SG_ BMS1_SDB_M1_OverTemp_detect : 52|1@1+ (1,0) [0|1] "-"  LOGBOX
 SG_ BMS1_SDB_M1_UnderVoltage_detect : 51|1@1+ (1,0) [0|1] "-"  LOGBOX
 SG_ BMS1_SDB_M1_OverVoltage_detected : 50|1@1+ (1,0) [0|1] "-"  LOGBOX
 SG_ BMS1_SDB_M1_Overload_detected : 49|1@1+ (1,0) [0|1] "-"  LOGBOX
 SG_ BMS1_SDB_M1_ShortCircuit_detect : 48|1@1+ (1,0) [0|1] "-"  LOGBOX
 SG_ BMS1_SDB_M1_Module_BQ78350 : 56|8@1+ (1,0) [0|2] "-"  LOGBOX

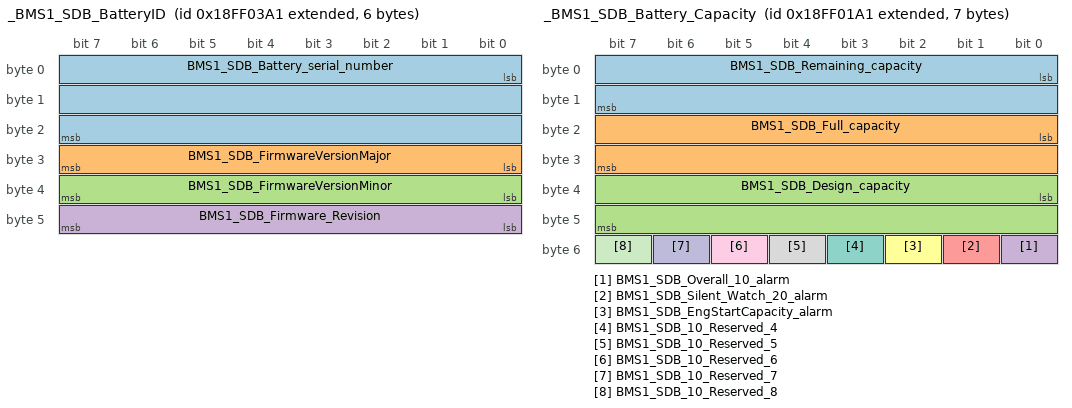
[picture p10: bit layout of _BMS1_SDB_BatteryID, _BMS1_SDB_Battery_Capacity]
BO_ 2566849441 _BMS1_SDB_BatteryID: 6 BMS1_SDB
 SG_ BMS1_SDB_Battery_serial_number : 0|24@1+ (1,0) [0|16777214] "-"  LOGBOX
 SG_ BMS1_SDB_FirmwareVersionMajor : 24|8@1+ (1,0) [0|255] "-"  LOGBOX
 SG_ BMS1_SDB_FirmwareVersionMinor : 32|8@1+ (1,0) [0|255] "-"  LOGBOX
 SG_ BMS1_SDB_Firmware_Revision : 40|8@1+ (1,0) [0|255] "-"  LOGBOX

BO_ 2566849185 _BMS1_SDB_BatteryTemperature: 6 BMS1_SDB
 SG_ BMS1_SDB_Maximum_Temperature : 0|16@1+ (0.1,-100) [-100|200] "°C"  LOGBOX
 SG_ BMS1_SDB_Minimum_Temperature : 16|16@1+ (0.1,-100) [-100|200] "°C"  LOGBOX
 SG_ BMS1_SDB_Average_Temperature : 32|16@1+ (0.1,-100) [-100|200] "°C"  LOGBOX

BO_ 2566848929 _BMS1_SDB_Battery_Capacity: 7 BMS1_SDB
 SG_ BMS1_SDB_Remaining_capacity : 0|16@1+ (0.01,0) [0|642.55] "Ah"  LOGBOX
 SG_ BMS1_SDB_Full_capacity : 16|16@1+ (0.01,0) [0|642.55] "Ah"  LOGBOX
 SG_ BMS1_SDB_Design_capacity : 32|16@1+ (0.01,0) [0|642.55] "Ah"  LOGBOX
 SG_ BMS1_SDB_Overall_10_alarm : 48|1@1+ (1,0) [0|1] "-"  LOGBOX
 SG_ BMS1_SDB_Silent_Watch_20_alarm : 49|1@1+ (1,0) [0|1] "-"  LOGBOX
 SG_ BMS1_SDB_EngStartCapacity_alarm : 50|1@1+ (1,0) [0|1] "-"  LOGBOX
 SG_ BMS1_SDB_10_Reserved_4 : 51|1@1+ (1,0) [0|0] "-"  LOGBOX
 SG_ BMS1_SDB_10_Reserved_5 : 52|1@1+ (1,0) [0|0] "-"  LOGBOX
 SG_ BMS1_SDB_10_Reserved_6 : 53|1@1+ (1,0) [0|0] "-"  LOGBOX
 SG_ BMS1_SDB_10_Reserved_7 : 54|1@1+ (1,0) [0|0] "-"  LOGBOX
 SG_ BMS1_SDB_10_Reserved_8 : 55|1@1+ (1,0) [0|0] "-"  LOGBOX

BO_ 2566848673 _BMS1_SDB_BatteryOperatingParam: 8 BMS1_SDB
 SG_ BMS1_SDB_Batt_OUT_Voltage : 0|16@1+ (0.001,0) [0|64255] "V"  LOGBOX
 SG_ BMS1_SDB_Batt_Average_Current : 16|16@1+ (0.1,-5500) [-5500|925.5] "A"  LOGBOX
 SG_ BMS1_SDB_Batt_StsOfCharge : 32|8@1+ (1,0) [0|100] "%"  LOGBOX
 SG_ BMS1_SDB_Batt_StsOfHealth : 40|8@1+ (1,0) [0|2] "-"  LOGBOX
 SG_ BMS1_SDB_Batt_PS8_discharge_prot : 55|1@1+ (1,0) [0|1] "-"  LOGBOX
 SG_ BMS1_SDB_Batt_PS7_charge_prot : 54|1@1+ (1,0) [0|1] "-"  LOGBOX
 SG_ BMS1_SDB_Batt_PS6_mod_failed : 53|1@1+ (1,0) [0|1] "-"  LOGBOX
 SG_ BMS1_SDB_Batt_PS5_over_temp : 52|1@1+ (1,0) [0|1] "-"  LOGBOX
 SG_ BMS1_SDB_Batt_PS4_under_voltage : 51|1@1+ (1,0) [0|1] "-"  LOGBOX
 SG_ BMS1_SDB_Batt_PS3_over_voltage : 50|1@1+ (1,0) [0|1] "-"  LOGBOX
 SG_ BMS1_SDB_Batt_PS2_overload : 49|1@1+ (1,0) [0|1] "-"  LOGBOX
 SG_ BMS1_SDB_Batt_PS1_short_circuit : 48|1@1+ (1,0) [0|1] "-"  LOGBOX
 SG_ BMS1_SDB_Batt_OS_8_sleep_mode : 63|1@1+ (1,0) [0|1] "-"  LOGBOX
 SG_ BMS1_SDB_Batt_OS_7_emerg_used : 62|1@1+ (1,0) [0|1] "-"  LOGBOX
 SG_ BMS1_SDB_Batt_OS_6_emergency : 61|1@1+ (1,0) [0|1] "-"  LOGBOX
 SG_ BMS1_SDB_Batt_OS_45_charge_level : 59|2@1+ (1,0) [0|3] "-"  LOGBOX
 SG_ BMS1_SDB_Batt_OS_3_charge_cont : 58|1@1+ (1,0) [0|1] "-"  LOGBOX
 SG_ BMS1_SDB_Batt_OS_2_heater_cont : 57|1@1+ (1,0) [0|1] "-"  LOGBOX
 SG_ BMS1_SDB_Batt_OS_1_master_prot : 56|1@1+ (1,0) [0|1] "-"  LOGBOX

BO_ 2566804129 _BMS1_SDB_VEP_3: 8 BMS1_SDB
 SG_ _nu_BMS1_SDB_AlternatorCurrent : 0|16@1+ (0.05,-1600) [-1600|1612.75] "A"  LOGBOX
 SG_ BMS1_SDB_NetBattery_Current : 16|16@1+ (0.05,-1600) [-1600|1612.75] "A"  LOGBOX

BO_ 2566803617 _BMS1_SDB_Battery_1_Temp: 8 BMS1_SDB
 SG_ BMS1_SDB_Battery1_Temperature : 0|8@1+ (1,-40) [-40|210] "°C"  LOGBOX
 SG_ _nu_BMS1_SDB_Battery2_Temp : 8|8@1+ (1,-40) [-40|210] "°C"  LOGBOX

BO_ 2566698657 _BMS1_SDB_VEP_5: 8 BMS1_SDB
 SG_ BMS1_SDB_SLI_BattPack_StOfCharge : 0|16@1+ (0.0025,0) [0|1606375] "%"  LOGBOX
 SG_ BMS1_SDB_SLI_BattPack_Capacity : 16|16@1+ (1,0) [0|64255] "Ah"  LOGBOX
 SG_ BMS1_SDB_SLI_BattPack_Health : 32|8@1+ (0.5,0) [0|100] "%"  LOGBOX

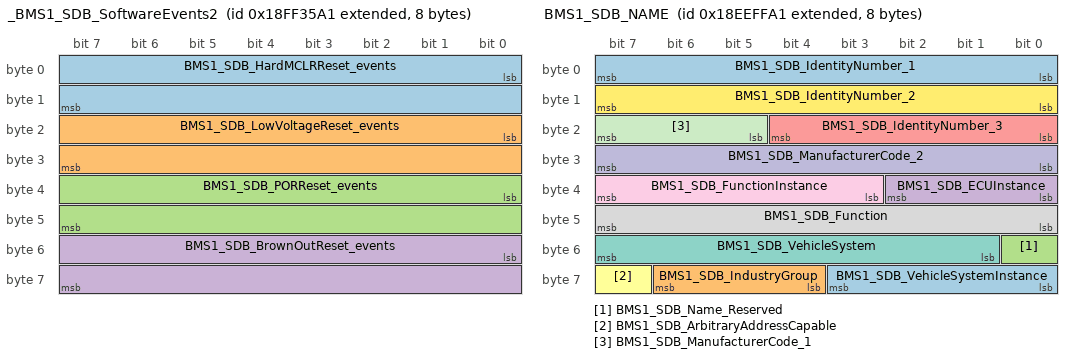
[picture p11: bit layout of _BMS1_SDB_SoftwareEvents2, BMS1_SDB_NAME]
BO_ 2566862241 _BMS1_SDB_SoftwareEvents2: 8 BMS1_SDB
 SG_ BMS1_SDB_HardMCLRReset_events : 0|16@1+ (1,0) [0|64255] "-"  LOGBOX
 SG_ BMS1_SDB_LowVoltageReset_events : 16|16@1+ (1,0) [0|64255] "-"  LOGBOX
 SG_ BMS1_SDB_PORReset_events : 32|16@1+ (1,0) [0|64255] "-"  LOGBOX
 SG_ BMS1_SDB_BrownOutReset_events : 48|16@1+ (1,0) [0|64255] "-"  LOGBOX

BO_ 2565799841 BMS1_SDB_NAME: 8 BMS1_SDB
 SG_ BMS1_SDB_VehicleSystemInstance : 56|4@1+ (1,0) [0|15] "-"  LOGBOX,BC
 SG_ BMS1_SDB_IndustryGroup : 60|3@1+ (1,0) [0|7] "-"  LOGBOX,BC
 SG_ BMS1_SDB_Name_Reserved : 48|1@1+ (1,0) [0|1] "-"  LOGBOX,BC
 SG_ BMS1_SDB_ECUInstance : 32|3@1+ (1,0) [0|7] "-"  LOGBOX,BC
 SG_ BMS1_SDB_IdentityNumber_3 : 16|5@1+ (1,0) [0|31] "-"  LOGBOX,BC
 SG_ BMS1_SDB_ArbitraryAddressCapable : 63|1@1+ (1,0) [0|1] "-"  LOGBOX,BC
 SG_ BMS1_SDB_VehicleSystem : 49|7@1+ (1,0) [0|127] "-"  LOGBOX,BC
 SG_ BMS1_SDB_Function : 40|8@1+ (1,0) [0|255] "-"  LOGBOX,BC
 SG_ BMS1_SDB_FunctionInstance : 35|5@1+ (1,0) [0|31] "-"  LOGBOX,BC
 SG_ BMS1_SDB_ManufacturerCode_2 : 24|8@1+ (1,0) [0|255] "-"  LOGBOX,BC
 SG_ BMS1_SDB_ManufacturerCode_1 : 21|3@1+ (1,0) [0|7] "-"  LOGBOX,BC
 SG_ BMS1_SDB_IdentityNumber_2 : 8|8@1+ (1,0) [0|255] "-"  LOGBOX,BC
 SG_ BMS1_SDB_IdentityNumber_1 : 0|8@1+ (1,0) [0|255] "-"  LOGBOX,BC

BO_ 2566849954 BMS2_SDB_BatterySummaryStatus: 8 BMS2_SDB
 SG_ BMS2_SDB_BatSumS_serial_number : 0|24@1+ (1,0) [0|16777214] "-"  BC,LOGBOX
 SG_ BMS2_SDB_BatSumS_Reserved_01 : 24|8@1+ (1,0) [0|255] "-"  LOGBOX
 SG_ BMS2_SDB_BatSumS_State_of_Charge : 32|8@1+ (1,0) [0|100] "%"  LOGBOX,BC
 SG_ BMS2_SDB_BatSumS_State_of_Health : 40|8@1+ (1,0) [0|2] "-"  LOGBOX,BC
 SG_ BMS2_SDB_BatSumS_Temp_Alarm : 48|2@1+ (1,0) [0|3] "-"  LOGBOX,BC
 SG_ BMS2_SDB_BatSumS_DischargeDis : 50|1@1+ (1,0) [0|1] "-"  LOGBOX,BC
 SG_ BMS2_SDB_BatSumS_ChargingDisable : 51|1@1+ (1,0) [0|1] "-"  LOGBOX,BC
 SG_ BMS2_SDB_BatSumS_HeaterEnabled : 52|1@1+ (1,0) [0|1] "-"  LOGBOX,BC
 SG_ BMS2_SDB_BatSumS_BypassEnabled : 53|1@1+ (1,0) [0|1] "-"  LOGBOX,BC
 SG_ BMS2_SDB_BatSumS_Voltage_Alarm : 56|1@1+ (1,0) [0|1] "-"  LOGBOX,BC
 SG_ BMS2_SDB_BatSumS_Reserved_04 : 54|2@1+ (1,0) [0|3] "-"  LOGBOX
 SG_ BMS2_SDB_BatSumS_Reserved_05 : 57|1@1+ (1,0) [0|1] "-"  LOGBOX,BC
 SG_ BMS2_SDB_BatSumS_Reserved_06 : 58|1@1+ (1,0) [0|1] "-"  LOGBOX
 SG_ BMS2_SDB_BatSumS_Reserved_07 : 59|1@1+ (1,0) [0|1] "-"  LOGBOX
 SG_ BMS2_SDB_BatSumS_Reserved_08 : 60|1@1+ (1,0) [0|1] "-"  LOGBOX
 SG_ BMS2_SDB_BatSumS_Reserved_09 : 61|1@1+ (1,0) [0|1] "-"  LOGBOX
 SG_ BMS2_SDB_BatSumS_Reserved_10 : 62|1@1+ (1,0) [0|1] "-"  LOGBOX
 SG_ BMS2_SDB_BatSumS_Reserved_11 : 63|1@1+ (1,0) [0|1] "-"  LOGBOX

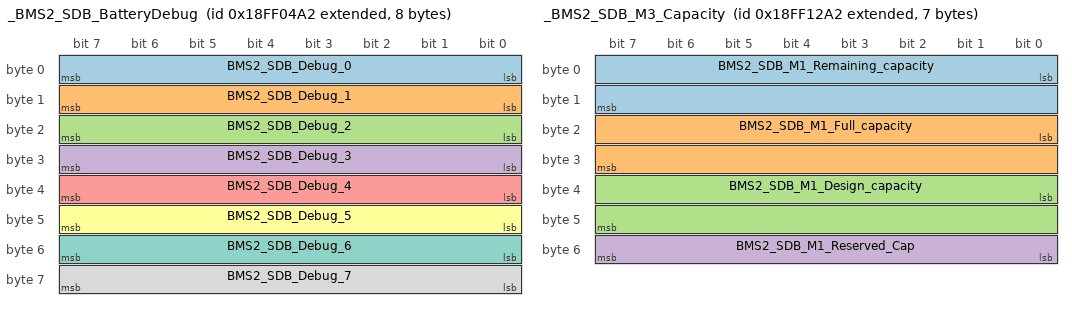
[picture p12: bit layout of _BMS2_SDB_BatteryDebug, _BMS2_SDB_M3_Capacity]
BO_ 2566849698 _BMS2_SDB_BatteryDebug: 8 BMS2_SDB
 SG_ BMS2_SDB_Debug_0 : 0|8@1+ (1,0) [0|255] "-"  LOGBOX
 SG_ BMS2_SDB_Debug_1 : 8|8@1+ (1,0) [0|255] "-"  LOGBOX
 SG_ BMS2_SDB_Debug_2 : 16|8@1+ (1,0) [0|255] "-"  LOGBOX
 SG_ BMS2_SDB_Debug_3 : 24|8@1+ (1,0) [0|255] "-"  LOGBOX
 SG_ BMS2_SDB_Debug_4 : 32|8@1+ (1,0) [0|255] "-"  LOGBOX
 SG_ BMS2_SDB_Debug_5 : 40|8@1+ (1,0) [0|255] "-"  LOGBOX
 SG_ BMS2_SDB_Debug_6 : 48|8@1+ (1,0) [0|255] "-"  LOGBOX
 SG_ BMS2_SDB_Debug_7 : 56|8@1+ (1,0) [0|255] "-"  LOGBOX

BO_ 2566853282 _BMS2_SDB_M3_Capacity: 7 BMS2_SDB
 SG_ BMS2_SDB_M1_Remaining_capacity : 0|16@1+ (0.01,0) [0|642.55] "Ah"  LOGBOX
 SG_ BMS2_SDB_M1_Full_capacity : 16|16@1+ (0.01,0) [0|642.55] "Ah"  LOGBOX
 SG_ BMS2_SDB_M1_Design_capacity : 32|16@1+ (0.01,0) [0|642.55] "Ah"  LOGBOX
 SG_ BMS2_SDB_M1_Reserved_Cap : 48|8@1+ (1,0) [255|255] "-"  LOGBOX

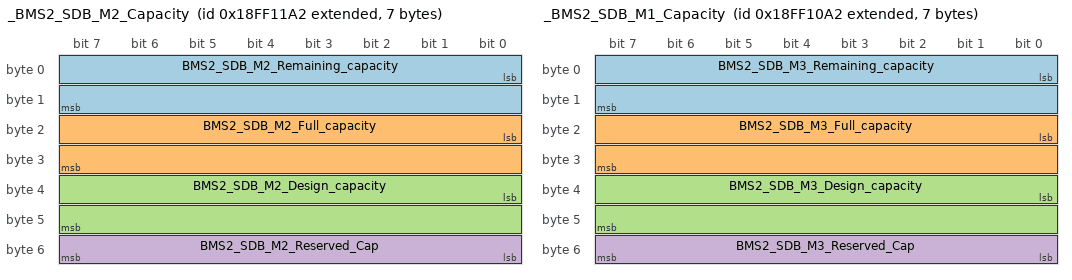
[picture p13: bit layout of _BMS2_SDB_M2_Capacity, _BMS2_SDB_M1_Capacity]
BO_ 2566853026 _BMS2_SDB_M2_Capacity: 7 BMS2_SDB
 SG_ BMS2_SDB_M2_Remaining_capacity : 0|16@1+ (0.01,0) [0|642.55] "Ah"  LOGBOX
 SG_ BMS2_SDB_M2_Full_capacity : 16|16@1+ (0.01,0) [0|642.55] "Ah"  LOGBOX
 SG_ BMS2_SDB_M2_Design_capacity : 32|16@1+ (0.01,0) [0|642.55] "Ah"  LOGBOX
 SG_ BMS2_SDB_M2_Reserved_Cap : 48|8@1+ (1,0) [255|255] "-"  LOGBOX

BO_ 2566852770 _BMS2_SDB_M1_Capacity: 7 BMS2_SDB
 SG_ BMS2_SDB_M3_Remaining_capacity : 0|16@1+ (0.01,0) [0|642.55] "Ah"  LOGBOX
 SG_ BMS2_SDB_M3_Full_capacity : 16|16@1+ (0.01,0) [0|642.55] "Ah"  LOGBOX
 SG_ BMS2_SDB_M3_Design_capacity : 32|16@1+ (0.01,0) [0|642.55] "Ah"  LOGBOX
 SG_ BMS2_SDB_M3_Reserved_Cap : 48|8@1+ (1,0) [255|255] "-"  LOGBOX

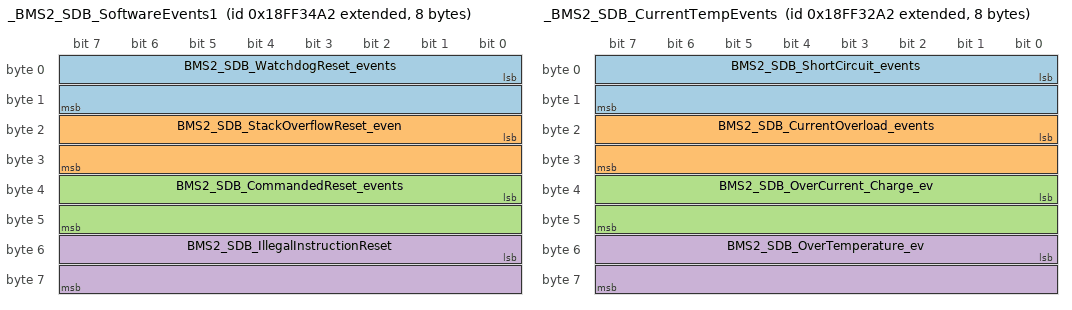
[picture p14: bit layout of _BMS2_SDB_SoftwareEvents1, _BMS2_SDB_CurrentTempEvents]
BO_ 2566861986 _BMS2_SDB_SoftwareEvents1: 8 BMS2_SDB
 SG_ BMS2_SDB_WatchdogReset_events : 0|16@1+ (1,0) [0|64255] "-"  LOGBOX
 SG_ BMS2_SDB_StackOverflowReset_even : 16|16@1+ (1,0) [0|64255] "-"  LOGBOX
 SG_ BMS2_SDB_CommandedReset_events : 32|16@1+ (1,0) [0|64255] "-"  LOGBOX
 SG_ BMS2_SDB_IllegalInstructionReset : 48|16@1+ (1,0) [0|64255] "-"  LOGBOX

BO_ 2566861730 _BMS2_SDB_VoltageEvents: 4 BMS2_SDB
 SG_ BMS2_SDB_OverVoltage_events : 0|16@1+ (1,0) [0|64255] "-"  LOGBOX
 SG_ BMS2_SDB_UnderVoltage_events : 16|16@1+ (1,0) [0|64255] "-"  LOGBOX

BO_ 2566861474 _BMS2_SDB_CurrentTempEvents: 8 BMS2_SDB
 SG_ BMS2_SDB_ShortCircuit_events : 0|16@1+ (1,0) [0|64255] "-"  LOGBOX
 SG_ BMS2_SDB_CurrentOverload_events : 16|16@1+ (1,0) [0|64255] "-"  LOGBOX
 SG_ BMS2_SDB_OverCurrent_Charge_ev : 32|16@1+ (1,0) [0|64255] "-"  LOGBOX
 SG_ BMS2_SDB_OverTemperature_ev : 48|16@1+ (1,0) [0|64255] "-"  LOGBOX

BO_ 2566861218 _BMS2_SDB_VoltageCurrentExt: 8 BMS2_SDB
 SG_ BMS2_SDB_MaximumVoltage : 0|16@1+ (0.001,0) [0|64255] "V"  LOGBOX
 SG_ BMS2_SDB_MinimumVoltage : 16|16@1+ (0.001,0) [0|64255] "V"  LOGBOX
 SG_ BMS2_SDB_MAX_Discharge_Current : 32|16@1+ (0.1,0) [0|6425.5] "A"  LOGBOX
 SG_ BMS2_SDB_MAX_Charge_Current : 48|16@1+ (0.1,0) [0|6425.5] "A"  LOGBOX

BO_ 2566860962 _BMS2_SDB_TemperatureExtremes: 8 BMS2_SDB
 SG_ BMS2_SDB_Maximum_Life_temp : 0|16@1+ (0.1,-100) [-100|200] "°C"  LOGBOX
 SG_ BMS2_SDB_Minimum_Life_temp : 16|16@1+ (0.1,-100) [-100|200] "°C"  LOGBOX
 SG_ BMS2_SDB_MAX_Charging_Temp : 32|16@1+ (0.1,-100) [-100|200] "°C"  LOGBOX
 SG_ BMS2_SDB_MIN_Charging_Temp : 48|16@1+ (0.1,-100) [-100|200] "°C"  LOGBOX

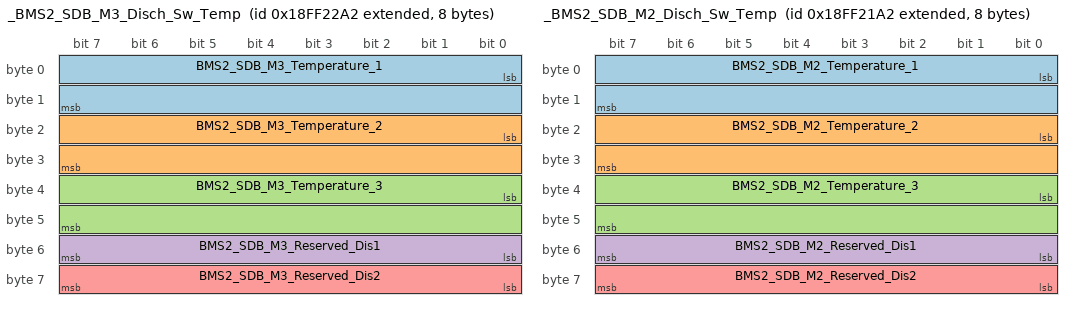
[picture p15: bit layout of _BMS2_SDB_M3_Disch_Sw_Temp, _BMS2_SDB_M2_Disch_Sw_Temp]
BO_ 2566857378 _BMS2_SDB_M3_Disch_Sw_Temp: 8 BMS2_SDB
 SG_ BMS2_SDB_M3_Temperature_1 : 0|16@1+ (0.1,-100) [-100|200] "°C"  LOGBOX
 SG_ BMS2_SDB_M3_Temperature_2 : 16|16@1+ (0.1,-100) [-100|200] "°C"  LOGBOX
 SG_ BMS2_SDB_M3_Temperature_3 : 32|16@1+ (0.1,-100) [-100|200] "°C"  LOGBOX
 SG_ BMS2_SDB_M3_Reserved_Dis1 : 48|8@1+ (1,0) [255|255] "-"  LOGBOX
 SG_ BMS2_SDB_M3_Reserved_Dis2 : 56|8@1+ (1,0) [255|255] "-"  LOGBOX

BO_ 2566857122 _BMS2_SDB_M2_Disch_Sw_Temp: 8 BMS2_SDB
 SG_ BMS2_SDB_M2_Temperature_1 : 0|16@1+ (0.1,-100) [-100|200] "°C"  LOGBOX
 SG_ BMS2_SDB_M2_Temperature_2 : 16|16@1+ (0.1,-100) [-100|200] "°C"  LOGBOX
 SG_ BMS2_SDB_M2_Temperature_3 : 32|16@1+ (0.1,-100) [-100|200] "°C"  LOGBOX
 SG_ BMS2_SDB_M2_Reserved_Dis1 : 48|8@1+ (1,0) [255|255] "-"  LOGBOX
 SG_ BMS2_SDB_M2_Reserved_Dis2 : 56|8@1+ (1,0) [255|255] "-"  LOGBOX

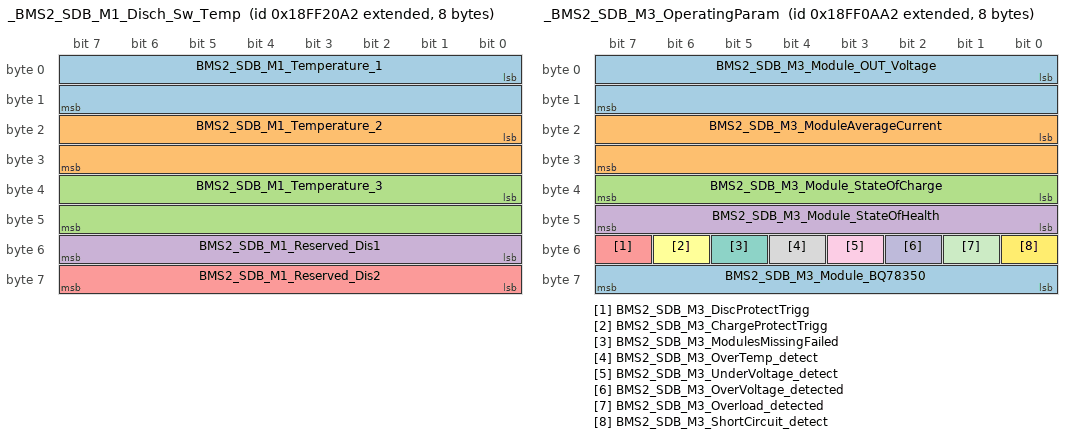
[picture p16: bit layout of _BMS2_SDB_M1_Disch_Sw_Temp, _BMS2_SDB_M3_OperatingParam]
BO_ 2566856866 _BMS2_SDB_M1_Disch_Sw_Temp: 8 BMS2_SDB
 SG_ BMS2_SDB_M1_Temperature_1 : 0|16@1+ (0.1,-100) [-100|200] "°C"  LOGBOX
 SG_ BMS2_SDB_M1_Temperature_2 : 16|16@1+ (0.1,-100) [-100|200] "°C"  LOGBOX
 SG_ BMS2_SDB_M1_Temperature_3 : 32|16@1+ (0.1,-100) [-100|200] "°C"  LOGBOX
 SG_ BMS2_SDB_M1_Reserved_Dis1 : 48|8@1+ (1,0) [255|255] "-"  LOGBOX
 SG_ BMS2_SDB_M1_Reserved_Dis2 : 56|8@1+ (1,0) [255|255] "-"  LOGBOX

BO_ 2566855330 _BMS2_SDB_M3_Pack_Temp: 8 BMS2_SDB
 SG_ BMS2_SDB_M3_FuelGauge1_Temp : 0|16@1+ (0.1,-100) [-100|200] "°C"  LOGBOX
 SG_ BMS2_SDB_M3_Thermistor1_temp : 32|16@1+ (0.1,-100) [-100|200] "-"  LOGBOX
 SG_ BMS2_SDB_M3_Thermistor2_temp : 48|16@1+ (0.1,-100) [-100|200] "-"  LOGBOX
 SG_ BMS2_SDB_M3_FuelGauge2_Temp : 16|16@1+ (0.1,-100) [-100|200] "°C"  LOGBOX

BO_ 2566855074 _BMS2_SDB_M2_Pack_Temp: 8 BMS2_SDB
 SG_ BMS2_SDB_M2_FuelGauge1_Temp : 0|16@1+ (0.1,-100) [-100|200] "°C"  LOGBOX
 SG_ BMS2_SDB_M2_Thermistor1_temp : 32|16@1+ (0.1,-100) [-100|200] "-"  LOGBOX
 SG_ BMS2_SDB_M2_Thermistor2_temp : 48|16@1+ (0.1,-100) [-100|200] "-"  LOGBOX
 SG_ BMS2_SDB_M2_FuelGauge2_Temp : 16|16@1+ (0.1,-100) [-100|200] "°C"  LOGBOX

BO_ 2566854818 _BMS2_SDB_M1_Pack_Temp: 8 BMS2_SDB
 SG_ BMS2_SDB_M1_FuelGauge1_Temp : 0|16@1+ (0.1,-100) [-100|200] "°C"  LOGBOX
 SG_ BMS2_SDB_M1_Thermistor1_temp : 32|16@1+ (0.1,-100) [-100|200] "-"  LOGBOX
 SG_ BMS2_SDB_M1_Thermistor2_temp : 48|16@1+ (0.1,-100) [-100|200] "-"  LOGBOX
 SG_ BMS2_SDB_M1_FuelGauge2_Temp : 16|16@1+ (0.1,-100) [-100|200] "°C"  LOGBOX

BO_ 2566851234 _BMS2_SDB_M3_OperatingParam: 8 BMS2_SDB
 SG_ BMS2_SDB_M3_Module_OUT_Voltage : 0|16@1+ (0.001,0) [0|64255] "V"  LOGBOX
 SG_ BMS2_SDB_M3_ModuleAverageCurrent : 16|16@1+ (0.1,-5500) [-5500|925.5] "A"  LOGBOX
 SG_ BMS2_SDB_M3_Module_StateOfCharge : 32|8@1+ (1,0) [0|100] "%"  LOGBOX
 SG_ BMS2_SDB_M3_Module_StateOfHealth : 40|8@1+ (1,0) [0|2] "-"  LOGBOX
 SG_ BMS2_SDB_M3_DiscProtectTrigg : 55|1@1+ (1,0) [0|1] "-"  LOGBOX
 SG_ BMS2_SDB_M3_ChargeProtectTrigg : 54|1@1+ (1,0) [0|1] "-"  LOGBOX
 SG_ BMS2_SDB_M3_ModulesMissingFailed : 53|1@1+ (1,0) [0|1] "-"  LOGBOX
 SG_ BMS2_SDB_M3_OverTemp_detect : 52|1@1+ (1,0) [0|1] "-"  LOGBOX
 SG_ BMS2_SDB_M3_UnderVoltage_detect : 51|1@1+ (1,0) [0|1] "-"  LOGBOX
 SG_ BMS2_SDB_M3_OverVoltage_detected : 50|1@1+ (1,0) [0|1] "-"  LOGBOX
 SG_ BMS2_SDB_M3_Overload_detected : 49|1@1+ (1,0) [0|1] "-"  LOGBOX
 SG_ BMS2_SDB_M3_ShortCircuit_detect : 48|1@1+ (1,0) [0|1] "-"  LOGBOX
 SG_ BMS2_SDB_M3_Module_BQ78350 : 56|8@1+ (1,0) [0|2] "-"  LOGBOX

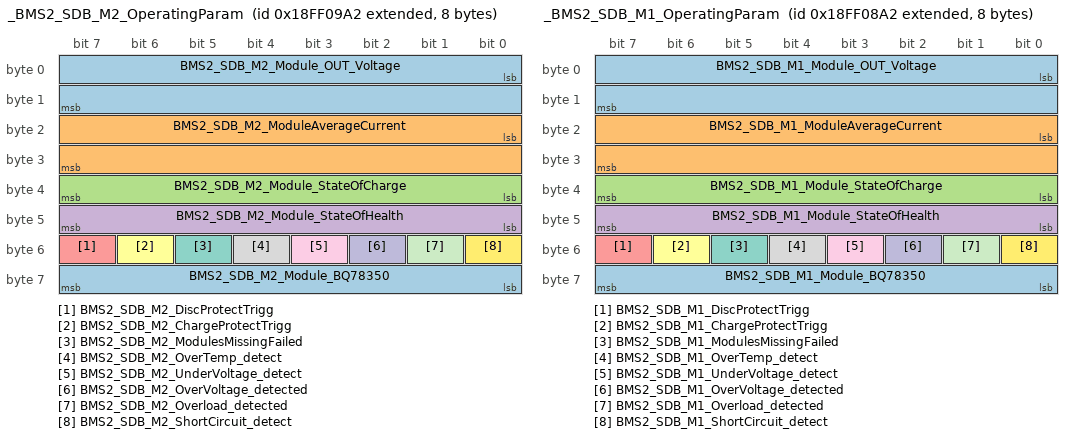
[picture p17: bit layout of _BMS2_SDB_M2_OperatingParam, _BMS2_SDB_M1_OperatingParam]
BO_ 2566850978 _BMS2_SDB_M2_OperatingParam: 8 BMS2_SDB
 SG_ BMS2_SDB_M2_Module_OUT_Voltage : 0|16@1+ (0.001,0) [0|64255] "V"  LOGBOX
 SG_ BMS2_SDB_M2_ModuleAverageCurrent : 16|16@1+ (0.1,-5500) [-5500|925.5] "A"  LOGBOX
 SG_ BMS2_SDB_M2_Module_StateOfCharge : 32|8@1+ (1,0) [0|100] "%"  LOGBOX
 SG_ BMS2_SDB_M2_Module_StateOfHealth : 40|8@1+ (1,0) [0|2] "-"  LOGBOX
 SG_ BMS2_SDB_M2_DiscProtectTrigg : 55|1@1+ (1,0) [0|1] "-"  LOGBOX
 SG_ BMS2_SDB_M2_ChargeProtectTrigg : 54|1@1+ (1,0) [0|1] "-"  LOGBOX
 SG_ BMS2_SDB_M2_ModulesMissingFailed : 53|1@1+ (1,0) [0|1] "-"  LOGBOX
 SG_ BMS2_SDB_M2_OverTemp_detect : 52|1@1+ (1,0) [0|1] "-"  LOGBOX
 SG_ BMS2_SDB_M2_UnderVoltage_detect : 51|1@1+ (1,0) [0|1] "-"  LOGBOX
 SG_ BMS2_SDB_M2_OverVoltage_detected : 50|1@1+ (1,0) [0|1] "-"  LOGBOX
 SG_ BMS2_SDB_M2_Overload_detected : 49|1@1+ (1,0) [0|1] "-"  LOGBOX
 SG_ BMS2_SDB_M2_ShortCircuit_detect : 48|1@1+ (1,0) [0|1] "-"  LOGBOX
 SG_ BMS2_SDB_M2_Module_BQ78350 : 56|8@1+ (1,0) [0|2] "-"  LOGBOX

BO_ 2566850722 _BMS2_SDB_M1_OperatingParam: 8 BMS2_SDB
 SG_ BMS2_SDB_M1_Module_OUT_Voltage : 0|16@1+ (0.001,0) [0|64255] "V"  LOGBOX
 SG_ BMS2_SDB_M1_ModuleAverageCurrent : 16|16@1+ (0.1,-5500) [-5500|925.5] "A"  LOGBOX
 SG_ BMS2_SDB_M1_Module_StateOfCharge : 32|8@1+ (1,0) [0|100] "%"  LOGBOX
 SG_ BMS2_SDB_M1_Module_StateOfHealth : 40|8@1+ (1,0) [0|2] "-"  LOGBOX
 SG_ BMS2_SDB_M1_DiscProtectTrigg : 55|1@1+ (1,0) [0|1] "-"  LOGBOX
 SG_ BMS2_SDB_M1_ChargeProtectTrigg : 54|1@1+ (1,0) [0|1] "-"  LOGBOX
 SG_ BMS2_SDB_M1_ModulesMissingFailed : 53|1@1+ (1,0) [0|1] "-"  LOGBOX
 SG_ BMS2_SDB_M1_OverTemp_detect : 52|1@1+ (1,0) [0|1] "-"  LOGBOX
 SG_ BMS2_SDB_M1_UnderVoltage_detect : 51|1@1+ (1,0) [0|1] "-"  LOGBOX
 SG_ BMS2_SDB_M1_OverVoltage_detected : 50|1@1+ (1,0) [0|1] "-"  LOGBOX
 SG_ BMS2_SDB_M1_Overload_detected : 49|1@1+ (1,0) [0|1] "-"  LOGBOX
 SG_ BMS2_SDB_M1_ShortCircuit_detect : 48|1@1+ (1,0) [0|1] "-"  LOGBOX
 SG_ BMS2_SDB_M1_Module_BQ78350 : 56|8@1+ (1,0) [0|2] "-"  LOGBOX

BO_ 2566849442 _BMS2_SDB_BatteryID: 6 BMS2_SDB
 SG_ BMS2_SDB_Battery_serial_number : 0|24@1+ (1,0) [0|16777214] "-"  LOGBOX
 SG_ BMS2_SDB_FirmwareVersionMajor : 24|8@1+ (1,0) [0|255] "-"  LOGBOX
 SG_ BMS2_SDB_FirmwareVersionMinor : 32|8@1+ (1,0) [0|255] "-"  LOGBOX
 SG_ BMS2_SDB_Firmware_Revision : 40|8@1+ (1,0) [0|255] "-"  LOGBOX

BO_ 2566849186 _BMS2_SDB_BatteryTemperature: 6 BMS2_SDB
 SG_ BMS2_SDB_Maximum_Temperature : 0|16@1+ (0.1,-100) [-100|200] "°C"  LOGBOX
 SG_ BMS2_SDB_Minimum_Temperature : 16|16@1+ (0.1,-100) [-100|200] "°C"  LOGBOX
 SG_ BMS2_SDB_Average_Temperature : 32|16@1+ (0.1,-100) [-100|200] "°C"  LOGBOX

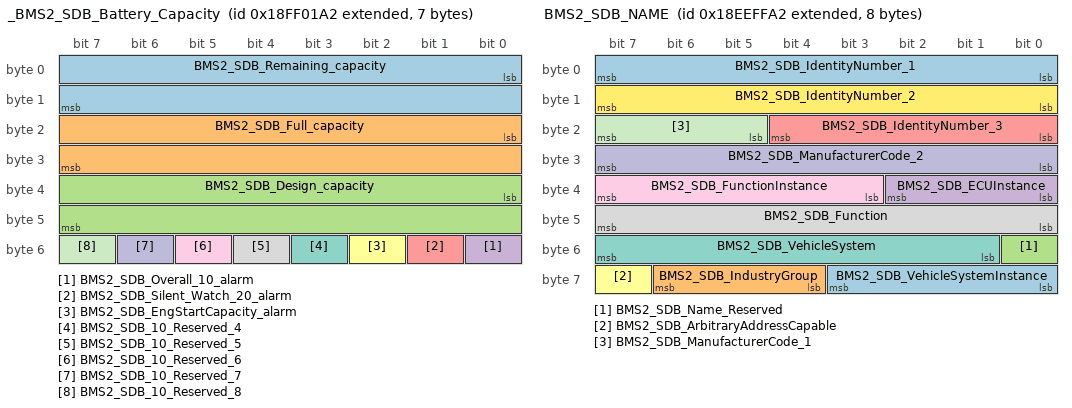
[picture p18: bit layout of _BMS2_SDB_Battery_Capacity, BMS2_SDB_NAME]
BO_ 2566848930 _BMS2_SDB_Battery_Capacity: 7 BMS2_SDB
 SG_ BMS2_SDB_Remaining_capacity : 0|16@1+ (0.01,0) [0|642.55] "Ah"  LOGBOX
 SG_ BMS2_SDB_Full_capacity : 16|16@1+ (0.01,0) [0|642.55] "Ah"  LOGBOX
 SG_ BMS2_SDB_Design_capacity : 32|16@1+ (0.01,0) [0|642.55] "Ah"  LOGBOX
 SG_ BMS2_SDB_Overall_10_alarm : 48|1@1+ (1,0) [0|1] "-"  LOGBOX
 SG_ BMS2_SDB_Silent_Watch_20_alarm : 49|1@1+ (1,0) [0|1] "-"  LOGBOX
 SG_ BMS2_SDB_EngStartCapacity_alarm : 50|1@1+ (1,0) [0|1] "-"  LOGBOX
 SG_ BMS2_SDB_10_Reserved_4 : 51|1@1+ (1,0) [0|0] "-"  LOGBOX
 SG_ BMS2_SDB_10_Reserved_5 : 52|1@1+ (1,0) [0|0] "-"  LOGBOX
 SG_ BMS2_SDB_10_Reserved_6 : 53|1@1+ (1,0) [0|0] "-"  LOGBOX
 SG_ BMS2_SDB_10_Reserved_7 : 54|1@1+ (1,0) [0|0] "-"  LOGBOX
 SG_ BMS2_SDB_10_Reserved_8 : 55|1@1+ (1,0) [0|0] "-"  LOGBOX

BO_ 2566848674 _BMS2_SDB_BatteryOperatingParam: 8 BMS2_SDB
 SG_ BMS2_SDB_Batt_OUT_Voltage : 0|16@1+ (0.001,0) [0|64255] "V"  LOGBOX
 SG_ BMS2_SDB_Batt_Average_Current : 16|16@1+ (0.1,-5500) [-5500|925.5] "A"  LOGBOX
 SG_ BMS2_SDB_Batt_StsOfCharge : 32|8@1+ (1,0) [0|100] "%"  LOGBOX
 SG_ BMS2_SDB_Batt_StsOfHealth : 40|8@1+ (1,0) [0|2] "-"  LOGBOX
 SG_ BMS2_SDB_Batt_PS8_discharge_prot : 55|1@1+ (1,0) [0|1] "-"  LOGBOX
 SG_ BMS2_SDB_Batt_PS7_charge_prot : 54|1@1+ (1,0) [0|1] "-"  LOGBOX
 SG_ BMS2_SDB_Batt_PS6_mod_failed : 53|1@1+ (1,0) [0|1] "-"  LOGBOX
 SG_ BMS2_SDB_Batt_PS5_over_temp : 52|1@1+ (1,0) [0|1] "-"  LOGBOX
 SG_ BMS2_SDB_Batt_PS4_under_voltage : 51|1@1+ (1,0) [0|1] "-"  LOGBOX
 SG_ BMS2_SDB_Batt_PS3_over_voltage : 50|1@1+ (1,0) [0|1] "-"  LOGBOX
 SG_ BMS2_SDB_Batt_PS2_overload : 49|1@1+ (1,0) [0|1] "-"  LOGBOX
 SG_ BMS2_SDB_Batt_PS1_short_circuit : 48|1@1+ (1,0) [0|1] "-"  LOGBOX
 SG_ BMS2_SDB_Batt_OS_8_sleep_mode : 63|1@1+ (1,0) [0|1] "-"  LOGBOX
 SG_ BMS2_SDB_Batt_OS_7_emerg_used : 62|1@1+ (1,0) [0|1] "-"  LOGBOX
 SG_ BMS2_SDB_Batt_OS_6_emergency : 61|1@1+ (1,0) [0|1] "-"  LOGBOX
 SG_ BMS2_SDB_Batt_OS_45_charge_level : 59|2@1+ (1,0) [0|3] "-"  LOGBOX
 SG_ BMS2_SDB_Batt_OS_3_charge_cont : 58|1@1+ (1,0) [0|1] "-"  LOGBOX
 SG_ BMS2_SDB_Batt_OS_2_heater_cont : 57|1@1+ (1,0) [0|1] "-"  LOGBOX
 SG_ BMS2_SDB_Batt_OS_1_master_prot : 56|1@1+ (1,0) [0|1] "-"  LOGBOX

BO_ 2566804130 _BMS2_SDB_VEP_3: 8 BMS2_SDB
 SG_ _nu_BMS2_SDB_AlternatorCurrent : 0|16@1+ (0.05,-1600) [-1600|1612.75] "A"  LOGBOX
 SG_ BMS2_SDB_NetBattery_Current : 16|16@1+ (0.05,-1600) [-1600|1612.75] "A"  LOGBOX

BO_ 2566803618 _BMS2_SDB_Battery_1_Temp: 8 BMS2_SDB
 SG_ BMS2_SDB_Battery1_Temperature : 0|8@1+ (1,-40) [-40|210] "°C"  LOGBOX
 SG_ _nu_BMS2_SDB_Battery2_Temp : 8|8@1+ (1,-40) [-40|210] "°C"  LOGBOX

BO_ 2566698658 _BMS2_SDB_VEP_5: 8 BMS2_SDB
 SG_ BMS2_SDB_SLI_BattPack_StOfCharge : 0|16@1+ (0.0025,0) [0|1606375] "%"  LOGBOX
 SG_ BMS2_SDB_SLI_BattPack_Capacity : 16|16@1+ (1,0) [0|64255] "Ah"  LOGBOX
 SG_ BMS2_SDB_SLI_BattPack_Health : 32|8@1+ (0.5,0) [0|100] "%"  LOGBOX

BO_ 2566862242 _BMS2_SDB_SoftwareEvents2: 8 BMS2_SDB
 SG_ BMS2_SDB_HardMCLRReset_events : 0|16@1+ (1,0) [0|64255] "-"  LOGBOX
 SG_ BMS2_SDB_LowVoltageReset_events : 16|16@1+ (1,0) [0|64255] "-"  LOGBOX
 SG_ BMS2_SDB_PORReset_events : 32|16@1+ (1,0) [0|64255] "-"  LOGBOX
 SG_ BMS2_SDB_BrownOutReset_events : 48|16@1+ (1,0) [0|64255] "-"  LOGBOX

BO_ 2565799842 BMS2_SDB_NAME: 8 BMS2_SDB
 SG_ BMS2_SDB_VehicleSystemInstance : 56|4@1+ (1,0) [0|15] "-"  LOGBOX,BC
 SG_ BMS2_SDB_IndustryGroup : 60|3@1+ (1,0) [0|7] "-"  LOGBOX,BC
 SG_ BMS2_SDB_Name_Reserved : 48|1@1+ (1,0) [0|1] "-"  LOGBOX,BC
 SG_ BMS2_SDB_ECUInstance : 32|3@1+ (1,0) [0|7] "-"  LOGBOX,BC
 SG_ BMS2_SDB_IdentityNumber_3 : 16|5@1+ (1,0) [0|31] "-"  LOGBOX,BC
 SG_ BMS2_SDB_ArbitraryAddressCapable : 63|1@1+ (1,0) [0|1] "-"  LOGBOX,BC
 SG_ BMS2_SDB_VehicleSystem : 49|7@1+ (1,0) [0|127] "-"  LOGBOX,BC
 SG_ BMS2_SDB_Function : 40|8@1+ (1,0) [0|255] "-"  LOGBOX,BC
 SG_ BMS2_SDB_FunctionInstance : 35|5@1+ (1,0) [0|31] "-"  LOGBOX,BC
 SG_ BMS2_SDB_ManufacturerCode_2 : 24|8@1+ (1,0) [0|255] "-"  LOGBOX,BC
 SG_ BMS2_SDB_ManufacturerCode_1 : 21|3@1+ (1,0) [0|7] "-"  LOGBOX,BC
 SG_ BMS2_SDB_IdentityNumber_2 : 8|8@1+ (1,0) [0|255] "-"  LOGBOX,BC
 SG_ BMS2_SDB_IdentityNumber_1 : 0|8@1+ (1,0) [0|255] "-"  LOGBOX,BC

BO_ 2566850046 BMS0_SDB_BatterySummaryStatus: 8 BMS0_SDB
 SG_ BMS0_SDB_BatSumS_serial_number : 0|24@1+ (1,0) [0|16777214] "-"  BC,LOGBOX
 SG_ BMS0_SDB_BatSumS_Reserved_01 : 24|8@1+ (1,0) [0|255] "-"  LOGBOX
 SG_ BMS0_SDB_BatSumS_State_of_Charge : 32|8@1+ (1,0) [0|100] "%"  LOGBOX,BC
 SG_ BMS0_SDB_BatSumS_State_of_Health : 40|8@1+ (1,0) [0|2] "-"  LOGBOX,BC
 SG_ BMS0_SDB_BatSumS_Temp_Alarm : 48|2@1+ (1,0) [0|3] "-"  LOGBOX,BC
 SG_ BMS0_SDB_BatSumS_DischargeDis : 50|1@1+ (1,0) [0|1] "-"  LOGBOX,BC
 SG_ BMS0_SDB_BatSumS_ChargingDisable : 51|1@1+ (1,0) [0|1] "-"  LOGBOX,BC
 SG_ BMS0_SDB_BatSumS_HeaterEnabled : 52|1@1+ (1,0) [0|1] "-"  LOGBOX,BC
 SG_ BMS0_SDB_BatSumS_BypassEnabled : 53|1@1+ (1,0) [0|1] "-"  LOGBOX,BC
 SG_ BMS0_SDB_BatSumS_Voltage_Alarm : 56|1@1+ (1,0) [0|1] "-"  LOGBOX,BC
 SG_ BMS0_SDB_BatSumS_Reserved_04 : 54|2@1+ (1,0) [0|3] "-"  LOGBOX
 SG_ BMS0_SDB_BatSumS_Reserved_05 : 57|1@1+ (1,0) [0|1] "-"  LOGBOX,BC
 SG_ BMS0_SDB_BatSumS_Reserved_06 : 58|1@1+ (1,0) [0|1] "-"  LOGBOX
 SG_ BMS0_SDB_BatSumS_Reserved_07 : 59|1@1+ (1,0) [0|1] "-"  LOGBOX
 SG_ BMS0_SDB_BatSumS_Reserved_08 : 60|1@1+ (1,0) [0|1] "-"  LOGBOX
 SG_ BMS0_SDB_BatSumS_Reserved_09 : 61|1@1+ (1,0) [0|1] "-"  LOGBOX
 SG_ BMS0_SDB_BatSumS_Reserved_10 : 62|1@1+ (1,0) [0|1] "-"  LOGBOX
 SG_ BMS0_SDB_BatSumS_Reserved_11 : 63|1@1+ (1,0) [0|1] "-"  LOGBOX

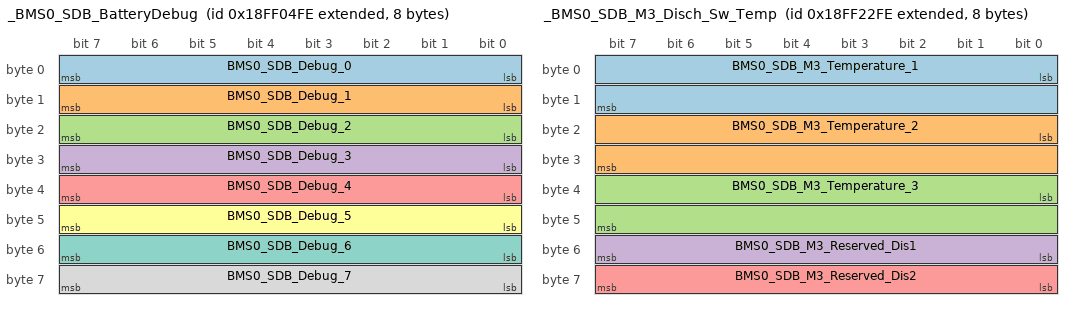
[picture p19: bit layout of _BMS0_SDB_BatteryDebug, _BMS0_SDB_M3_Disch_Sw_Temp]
BO_ 2566849790 _BMS0_SDB_BatteryDebug: 8 BMS0_SDB
 SG_ BMS0_SDB_Debug_0 : 0|8@1+ (1,0) [0|255] "-"  LOGBOX
 SG_ BMS0_SDB_Debug_1 : 8|8@1+ (1,0) [0|255] "-"  LOGBOX
 SG_ BMS0_SDB_Debug_2 : 16|8@1+ (1,0) [0|255] "-"  LOGBOX
 SG_ BMS0_SDB_Debug_3 : 24|8@1+ (1,0) [0|255] "-"  LOGBOX
 SG_ BMS0_SDB_Debug_4 : 32|8@1+ (1,0) [0|255] "-"  LOGBOX
 SG_ BMS0_SDB_Debug_5 : 40|8@1+ (1,0) [0|255] "-"  LOGBOX
 SG_ BMS0_SDB_Debug_6 : 48|8@1+ (1,0) [0|255] "-"  LOGBOX
 SG_ BMS0_SDB_Debug_7 : 56|8@1+ (1,0) [0|255] "-"  LOGBOX

BO_ 2566853374 _BMS0_SDB_M3_Capacity: 7 BMS0_SDB
 SG_ BMS0_SDB_M1_Remaining_capacity : 0|16@1+ (0.01,0) [0|642.55] "Ah"  LOGBOX
 SG_ BMS0_SDB_M1_Full_capacity : 16|16@1+ (0.01,0) [0|642.55] "Ah"  LOGBOX
 SG_ BMS0_SDB_M1_Design_capacity : 32|16@1+ (0.01,0) [0|642.55] "Ah"  LOGBOX
 SG_ BMS0_SDB_M1_Reserved_Cap : 48|8@1+ (1,0) [255|255] "-"  LOGBOX

BO_ 2566853118 _BMS0_SDB_M2_Capacity: 7 BMS0_SDB
 SG_ BMS0_SDB_M2_Remaining_capacity : 0|16@1+ (0.01,0) [0|642.55] "Ah"  LOGBOX
 SG_ BMS0_SDB_M2_Full_capacity : 16|16@1+ (0.01,0) [0|642.55] "Ah"  LOGBOX
 SG_ BMS0_SDB_M2_Design_capacity : 32|16@1+ (0.01,0) [0|642.55] "Ah"  LOGBOX
 SG_ BMS0_SDB_M2_Reserved_Cap : 48|8@1+ (1,0) [255|255] "-"  LOGBOX

BO_ 2566852862 _BMS0_SDB_M1_Capacity: 7 BMS0_SDB
 SG_ BMS0_SDB_M3_Remaining_capacity : 0|16@1+ (0.01,0) [0|642.55] "Ah"  LOGBOX
 SG_ BMS0_SDB_M3_Full_capacity : 16|16@1+ (0.01,0) [0|642.55] "Ah"  LOGBOX
 SG_ BMS0_SDB_M3_Design_capacity : 32|16@1+ (0.01,0) [0|642.55] "Ah"  LOGBOX
 SG_ BMS0_SDB_M3_Reserved_Cap : 48|8@1+ (1,0) [255|255] "-"  LOGBOX

BO_ 2566862078 _BMS0_SDB_SoftwareEvents1: 8 BMS0_SDB
 SG_ BMS0_SDB_WatchdogReset_events : 0|16@1+ (1,0) [0|64255] "-"  LOGBOX
 SG_ BMS0_SDB_StackOverflowReset_even : 16|16@1+ (1,0) [0|64255] "-"  LOGBOX
 SG_ BMS0_SDB_CommandedReset_events : 32|16@1+ (1,0) [0|64255] "-"  LOGBOX
 SG_ BMS0_SDB_IllegalInstructionReset : 48|16@1+ (1,0) [0|64255] "-"  LOGBOX

BO_ 2566861822 _BMS0_SDB_VoltageEvents: 4 BMS0_SDB
 SG_ BMS0_SDB_OverVoltage_events : 0|16@1+ (1,0) [0|64255] "-"  LOGBOX
 SG_ BMS0_SDB_UnderVoltage_events : 16|16@1+ (1,0) [0|64255] "-"  LOGBOX

BO_ 2566861566 _BMS0_SDB_CurrentTempEvents: 8 BMS0_SDB
 SG_ BMS0_SDB_ShortCircuit_events : 0|16@1+ (1,0) [0|64255] "-"  LOGBOX
 SG_ BMS0_SDB_CurrentOverload_events : 16|16@1+ (1,0) [0|64255] "-"  LOGBOX
 SG_ BMS0_SDB_OverCurrent_Charge_ev : 32|16@1+ (1,0) [0|64255] "-"  LOGBOX
 SG_ BMS0_SDB_OverTemperature_ev : 48|16@1+ (1,0) [0|64255] "-"  LOGBOX

BO_ 2566861310 _BMS0_SDB_VoltageCurrentExt: 8 BMS0_SDB
 SG_ BMS0_SDB_MaximumVoltage : 0|16@1+ (0.001,0) [0|64255] "V"  LOGBOX
 SG_ BMS0_SDB_MinimumVoltage : 16|16@1+ (0.001,0) [0|64255] "V"  LOGBOX
 SG_ BMS0_SDB_MAX_Discharge_Current : 32|16@1+ (0.1,0) [0|6425.5] "A"  LOGBOX
 SG_ BMS0_SDB_MAX_Charge_Current : 48|16@1+ (0.1,0) [0|6425.5] "A"  LOGBOX

BO_ 2566861054 _BMS0_SDB_TemperatureExtremes: 8 BMS0_SDB
 SG_ BMS0_SDB_Maximum_Life_temp : 0|16@1+ (0.1,-100) [-100|200] "°C"  LOGBOX
 SG_ BMS0_SDB_Minimum_Life_temp : 16|16@1+ (0.1,-100) [-100|200] "°C"  LOGBOX
 SG_ BMS0_SDB_MAX_Charging_Temp : 32|16@1+ (0.1,-100) [-100|200] "°C"  LOGBOX
 SG_ BMS0_SDB_MIN_Charging_Temp : 48|16@1+ (0.1,-100) [-100|200] "°C"  LOGBOX

BO_ 2566857470 _BMS0_SDB_M3_Disch_Sw_Temp: 8 BMS0_SDB
 SG_ BMS0_SDB_M3_Temperature_1 : 0|16@1+ (0.1,-100) [-100|200] "°C"  LOGBOX
 SG_ BMS0_SDB_M3_Temperature_2 : 16|16@1+ (0.1,-100) [-100|200] "°C"  LOGBOX
 SG_ BMS0_SDB_M3_Temperature_3 : 32|16@1+ (0.1,-100) [-100|200] "°C"  LOGBOX
 SG_ BMS0_SDB_M3_Reserved_Dis1 : 48|8@1+ (1,0) [255|255] "-"  LOGBOX
 SG_ BMS0_SDB_M3_Reserved_Dis2 : 56|8@1+ (1,0) [255|255] "-"  LOGBOX

CM_ BO_ 2558533943 "Message used for collecting the bushbutton status coming from the CP10 for the BC";
CM_ SG_ 2558533943 Btn_FuelPumpCP10 "The signal shall be used to know when the user's request of fuel pump activation/deactivation coming from CP10.";
CM_ SG_ 2558533943 Btn_EngineHeater_CP10 "The signal shall be used to know when the user's request of engine auxiliary heater activation/deactivation coming from CP10.";
CM_ SG_ 2558533943 Btn_ParkingBrake_CP10 "The signal shall be used by the BODY to know the user's request of Pneumatic ParkBrake activation/deactivation coming from CP10.";
CM_ SG_ 2558533943 Btn_Dust_Fan_CP10 "The signal shall be used to know when the user's request of Dust Extraction activation/deactivation coming from CP10.";
CM_ SG_ 2558533943 Btn_Warlight_B2_CP10 "The signal shall be used to know when the user's request of War 2 Light  activation/deactivation coming from CP10.";
CM_ SG_ 2558533943 Btn_Warlight_B1_CP10 "The signal shall be used to know when the user's request of War 1 Light   activation/deactivation coming from CP10.";
CM_ SG_ 2558533943 Btn_TripReset_CP10 "The signal shall be used by the BODY to know the user's request of resetting the Partial Mileage and Partial Hours counter coming from CP10.";
CM_ SG_ 2558533943 Btn_Retarder_Up_CP10 "The signal shall be used to know when the user's request of Retarder Up activation/deactivation coming from CP10.";
CM_ SG_ 2558533943 Btn_Retarder_Off_CP10 "The signal shall be used to know when the user's request of Retarder Off activation/deactivation coming from CP10.";
CM_ SG_ 2558533943 Btn_Retarder_Down_CP10 "The signal shall be used to know when the user's request of Retarder Down activation/deactivation coming from CP10.";
CM_ SG_ 2558533943 Btn_Marker_Light_CP10 "The signal shall be used to know when the user's request of Marker Light activation/deactivation coming from CP10.";
CM_ SG_ 2558533943 Btn_Low_Beam_Light_CP10 "The signal shall be used to know when the user's request of Beam Light  activation/deactivation coming from CP10.";
CM_ SG_ 2558533943 Btn_Lock_Front_Diff_CP10 "The signal shall be used to know when the user's request of Differential Lock activation/deactivation coming from CP10.";
CM_ SG_ 2558533943 Btn_Ford_Mode_CP10 "The signal shall be used to know when the user's request of Ford Mode activation/deactivation coming from CP10.";
CM_ SG_ 2558533943 Btn_Emergency_Blinker_CP10 "The signal shall be used to know when the user's request of Emergency Light activation/deactivation coming from CP10.";
CM_ SG_ 2558533943 Btn_CTIS_Track_CP10 "The signal shall be used to know when the user's request of CTIS Track Mode activation/deactivation coming from CP10.";
CM_ SG_ 2558533943 Btn_CTIS_Sand_CP10 "The signal shall be used to know when the user's request of CTIS Sand Mode activation/deactivation coming from CP10.";
CM_ SG_ 2558533943 Btn_CTIS_Road_CP10 "The signal shall be used to know when the user's request of CTIS Road Mode activation/deactivation coming from CP10.";
CM_ SG_ 2558533943 Btn_CTIS_ON_CP10 "The signal shall be used to know when the user's request of CTIS activation/deactivation coming from CP10.";
CM_ SG_ 2558533943 Btn_CTIS_Load_CP10 "The signal shall be used to know when the user's request of CTIS Load Mode selection coming from CP10.";
CM_ SG_ 2558533943 Btn_CTIS_Emergency_CP10 "The signal shall be used to know when the user's request of CTIS Emergency Mode activation/deactivation coming from CP10.";
CM_ SG_ 2558533943 Btn_CTIS_Check_CP10 "The signal shall be used to know when the user's request of CTIS Check Mode selection coming from CP10.";
CM_ SG_ 2558533943 Btn_Bilge_Pump_EngineBay_CP10 "The signal shall be used to know when the user's request of Engine Bay Bilge Pump activation/deactivation coming from CP10.";
CM_ SG_ 2558533943 Btn_All_Wheel_Drive_CP10 "The signal shall be used to know when the user's request of AWD activation/deactivation coming from CP10.";
CM_ SG_ 2558533943 Btn_4th_Steering_Axle_CP10 "The signal shall be used to know when the user's request of Fourth Steering Axle activation/deactivation coming from CP10.";
CM_ SG_ 2558533943 _nu_Btn_2_01_CP10 "Not used button";
CM_ SG_ 2558533943 _nu_Btn_2_04_CP10 "Not used button";
CM_ SG_ 2558533943 _nu_Btn_2_07_CP10 "Not used button";
CM_ SG_ 2558533943 Btn_Change_h_km_CP10 "The signal shall be used by the BODY to know the user's request of changing between hour and km visualization from CP10.";
CM_ SG_ 2558533943 _nu_Btn_2_15_CP10 "Not used button";
CM_ SG_ 2558533943 _nu_Btn_2_16_CP10 "Not used button";
CM_ SG_ 2558533943 _nu_Btn_2_17_CP10 "Not used button";
CM_ SG_ 2558533943 _nu_Btn_2_18_CP10 "Not used button";
CM_ SG_ 2558533943 _nu_Btn_2_19_CP10 "Not used button";
CM_ SG_ 2558533943 _nu_Btn_2_20_CP10 "Not used button";
CM_ SG_ 2558533943 _nu_Btn_2_21_CP10 "Not used button";
CM_ SG_ 2558533943 _nu_Btn_2_22_CP10 "Not used button";
CM_ SG_ 2558533943 _nu_Btn_2_23_CP10 "Not used button";
CM_ SG_ 2558533943 _nu_Btn_2_27_CP10 "Not used button";
CM_ SG_ 2558533943 _nu_Btn_2_28_CP10 "Not used button";
CM_ SG_ 2558533943 _nu_Btn_2_29_CP10 "Not used button";
CM_ SG_ 2558533943 _nu_Btn_2_30_CP10 "Not used button";
CM_ SG_ 2558533943 _nu_Btn_2_31_CP10 "Not used button";
CM_ SG_ 2558533943 _nu_Btn_2_35_CP10 "Not used button";
CM_ SG_ 2558533943 _nu_Btn_2_36_CP10 "Not used button";
CM_ SG_ 2558533943 _nu_Btn_2_37_CP10 "Not used button";
CM_ SG_ 2558533943 _nu_Btn_2_39_CP10 "Not used button";
CM_ SG_ 2558533943 _nu_Btn_2_47_CP10 "Not used button";
CM_ SG_ 2558533943 _nu_Btn_2_48_CP10 "Not used button";
CM_ SG_ 2558533943 _nu_Btn_2_49_CP10 "Not used button";
CM_ SG_ 2558533943 _nu_Btn_2_50_CP10 "Not used button";
CM_ SG_ 2558533943 _nu_Btn_2_51_CP10 "Not used button";
CM_ SG_ 2558533943 _nu_Btn_2_52_CP10 "Not used button";
CM_ SG_ 2558533943 _nu_Btn_2_53_CP10 "Not used button";
CM_ SG_ 2558533943 _nu_Btn_2_54_CP10 "Not used button";
CM_ SG_ 2558533943 _nu_Btn_2_55_CP10 "Not used button";
CM_ SG_ 2558533943 _nu_Btn_2_56_CP10 "Not used button";
CM_ SG_ 2558533943 _nu_Btn_2_57_CP10 "Not used button";
CM_ SG_ 2558533943 _nu_Btn_2_58_CP10 "Not used button";
CM_ SG_ 2558533943 _nu_Btn_2_59_CP10 "Not used button";
CM_ SG_ 2558533943 _nu_Btn_2_60_CP10 "Not used button";
CM_ SG_ 2558533943 _nu_Btn_2_61_CP10 "Not used button";
CM_ SG_ 2558533943 _nu_Btn_2_62_CP10 "Not used button";
CM_ SG_ 2558533943 _nu_Btn_2_63_CP10 "Not used button";
CM_ BO_ 2559260449 "Message used for collecting all the ALS information";
CM_ SG_ 2559260449 ALS_Configuration "This signal indicates the ALS configuration installed on the vehicle";
CM_ SG_ 2559260449 ALS_DX_Status "This signal indicates the ammunition loading right status.
The allowed values are:

0x00: ALS installed and present;
0x01: ALS installed and not present;
0x02: ALS not installed;
0x03: Information not available";
CM_ SG_ 2559260449 ALS_SX_HE_Counter "This signal indicates the number of HE ammunition in the ammunition loading left.";
CM_ SG_ 2559260449 ALS_SX_Status "This signal indicates the ammunition loading left status.
The allowed values are:

0x00: ALS installed and present;
0x01: ALS installed and not present;
0x02: ALS not installed;
0x03: Information not available";
CM_ SG_ 2559260449 ALS_SX_AP_Counter "This signal indicates the number of AP ammunition in the ammunition loading left.";
CM_ SG_ 2559260449 ALS_SX_MP_Counter "This signal indicates the number of MP ammunition in the ammunition loading left.";
CM_ SG_ 2559260449 ALS_DX_HE_Counter "This signal indicates the number of HE ammunition in the ammunition loading right.";
CM_ SG_ 2559260449 ALS_DX_AP_Counter "This signal indicates the number of AP ammunition in the ammunition loading right.";
CM_ SG_ 2559260449 ALS_DX_MP_Counter "This signal indicates the number of MP ammunition in the ammunition loading right.";
CM_ BO_ 2559325985 "Message used for collecting all the ALS information";
CM_ SG_ 2559325985 TLC_07_Status "This signal indicates the status of the TLC #07 by using the following values:

0x00: OK
0x01: KO or NOT CONNECTED
0x02: NOT USED
0x03: UNKNOWN";
CM_ SG_ 2559325985 TLC_06_Status "This signal indicates the status of the TLC #06 by using the following values:

0x00: OK
0x01: KO or NOT CONNECTED
0x02: NOT USED
0x03: UNKNOWN";
CM_ SG_ 2559325985 TLC_05_Status "This signal indicates the status of the TLC #05 by using the following values:

0x00: OK
0x01: KO or NOT CONNECTED
0x02: NOT USED
0x03: UNKNOWN";
CM_ SG_ 2559325985 TLC_04_Status "This signal indicates the status of the TLC #04 by using the following values:

0x00: OK
0x01: KO or NOT CONNECTED
0x02: NOT USED
0x03: UNKNOWN";
CM_ SG_ 2559325985 TLC_03_Status "This signal indicates the status of the TLC #03 by using the following values:

0x00: OK
0x01: KO or NOT CONNECTED
0x02: NOT USED
0x03: UNKNOWN";
CM_ SG_ 2559325985 TLC_02_Status "This signal indicates the status of the TLC #02 by using the following values:

0x00: OK
0x01: KO or NOT CONNECTED
0x02: NOT USED
0x03: UNKNOWN";
CM_ SG_ 2559325985 TLC_01_Status "This signal indicates the status of the TLC #01 by using the following values:

0x00: OK
0x01: KO or NOT CONNECTED
0x02: NOT USED
0x03: UNKNOWN";
CM_ SG_ 2559325985 TLC_07_Monitor "This signal indicates the monitor where the TLC #07 is connected:

0x00: SX (left)
0x01: C (central)
0x02: DX (right)
0x03: UNKNOWN";
CM_ SG_ 2559325985 TLC_06_Monitor "This signal indicates the monitor where the TLC #06 is connected:

0x00: SX (left)
0x01: C (central)
0x02: DX (right)
0x03: UNKNOWN";
CM_ SG_ 2559325985 TLC_05_Monitor "This signal indicates the monitor where the TLC #05 is connected:

0x00: SX (left)
0x01: C (central)
0x02: DX (right)
0x03: UNKNOWN";
CM_ SG_ 2559325985 TLC_04_Monitor "This signal indicates the monitor where the TLC #04 is connected:

0x00: SX (left)
0x01: C (central)
0x02: DX (right)
0x03: UNKNOWN";
CM_ SG_ 2559325985 TLC_03_Monitor "This signal indicates the monitor where the TLC #03 is connected:

0x00: SX (left)
0x01: C (central)
0x02: DX (right)
0x03: UNKNOWN";
CM_ SG_ 2559325985 TLC_02_Monitor "This signal indicates the monitor where the TLC #02 is connected:

0x00: SX (left)
0x01: C (central)
0x02: DX (right)
0x03: UNKNOWN";
CM_ SG_ 2559325985 TLC_01_Monitor "This signal indicates the monitor where the TLC #01 is connected:

0x00: SX (left)
0x01: C (central)
0x02: DX (right)
0x03: UNKNOWN";
CM_ SG_ 2559325985 TLC_00_Monitor "This signal indicates the monitor where the TLC #00 is connected:

0x00: SX (left)
0x01: C (central)
0x02: DX (right)
0x03: UNKNOWN";
CM_ SG_ 2559325985 TLC_00_Status "This signal indicates the status of the TLC #00 by using the following values:

0x00: OK
0x01: KO or NOT CONNECTED
0x02: NOT USED
0x03: UNKNOWN";
CM_ BO_ 2558590913 "NC sensor status

La periodicità del messaggio è, normalmente, pari a 1 secondo ma, in qualche caso, può arrivare fino a 30 secondi.
";
CM_ SG_ 2558590913 C_Sensor_Status "Working status of chemical sensor";
CM_ SG_ 2558590913 Class5_Value "Number of concentration bars of substance 5";
CM_ SG_ 2558590913 Class5_Type "Substance class of substance 5";
CM_ SG_ 2558590913 Class4_Value "Number of concentration bars of substance 4";
CM_ SG_ 2558590913 Class4_Type "Substance class of substance 4";
CM_ SG_ 2558590913 Class3_Value "Number of concentration bars of substance 3";
CM_ SG_ 2558590913 Class3_Type "Substance class of substance 3";
CM_ SG_ 2558590913 Class2_Value "Number of concentration bars of substance 2";
CM_ SG_ 2558590913 Class2_Type "Substance class of substance 2";
CM_ SG_ 2558590913 Class1_Value "Number of concentration bars of substance 1";
CM_ SG_ 2558590913 Class1_Type "Substance class of substance 1";
CM_ SG_ 2558590913 C_Alarm_Status "Alarm status of chemical sensor";
CM_ SG_ 2558590913 N_Sensor_Alarm "N-sensor Alarm (combined alarm: Dose Rate or Dose)";
CM_ SG_ 2558590913 N_DoseRateAlarm "Dose Rate Alarm";
CM_ SG_ 2558590913 N_DoseAlarm "Dose Alarm";
CM_ SG_ 2558590913 N_Current_Unit "Current Unit is Sv (0..Gy)";
CM_ SG_ 2558590913 N_GPS_detected "GPS detected";
CM_ SG_ 2558590913 Reserved_01 "Reserved";
CM_ SG_ 2558590913 Reserved_02 "Reserved";
CM_ SG_ 2558590913 Reserved_03 "Reserved";
CM_ SG_ 2558590913 N_Sensor_Error "N-sensor Error (combined alarm: GDR or Voltage module)";
CM_ SG_ 2558590913 N_GDR_Module_Error "N-sensor Error (GDR module error)";
CM_ SG_ 2558590913 N_Voltage_Module_Error "N-sensor Error (Voltage module error)";
CM_ SG_ 2558590913 Reserved_04 "Reserved";
CM_ SG_ 2558590913 Reserved_05 "Reserved";
CM_ SG_ 2558590913 Reserved_06 "Reserved";
CM_ SG_ 2558590913 Reserved_07 "Reserved";
CM_ SG_ 2558590913 Reserved_08 "Reserved";
CM_ BO_ 2558721985 "N Sensor rate values

La periodicità del messaggio è, normalmente, pari a 1 secondo ma, in qualche caso, può arrivare fino a 30 secondi.
";
CM_ SG_ 2558721985 Radiation "NC sensor answer to the current dose.
The signal format is compliant to IEEE 754.";
CM_ SG_ 2558721985 Radiation_Rate "NC sensor answer to the current dose rate.
The signal format is compliant to IEEE 754.";
CM_ SG_ 2566841884 SDB_Local_hour_offset "SPN 1602 Local hour offset
The hour component of the offset between the UTC (Universal Time Coordinate) time and date and a local time zone time
and date. This is the number of hours to add to UTC, a.k.a. GMT, time and date to convert to the time and date in the
local time zone. This parameter indicates the time reference of the data reported in the Time and Date SPNs 959, 960.
961, 962, 963, and 964. The Local Offset is a positive value for time zones East of the Prime Meridian to the International
Date Line. The Local Offset is a negative value for time zones West of the Prime Meridian to the International Date Line.
The Local Hour Offset is only applicable when the Time and Date parameters are reported as UTC time and date.
Recommended Settings:
Applications should not use the $FF 'Not Available' if using the Time and Date parameters due to some ambiguity of the
time standard for the reported time and date values. The recommended settings for the Local Hour Offset settings are:
If reporting the ";
CM_ SG_ 2566841884 SDB_Local_minute_offset "The minute component of the offset between the UTC time and date and a local time zone time and date. This is the
number of minutes to add to UTC (Universal Time Coordinate) time and date to convert to the time and date in the local
time zone . The Local Offset is a positive value for time zones East of the Prime Meridian to the International Date Line.
The Local Offset is a negative value for time zones West of the Prime Meridian to the International Date Line.
The Local Minute Offset is only applicable when the Time and Date parameters are reported as UTC time and date.
Refer to SPN 1602 for details.";
CM_ SG_ 2566841884 SDB_Year "The year component of the current calendar date. This should be reported as the year component of the current date at
UTC (Universal Time Coordinate), a.k.a. GMT; however, it may be reported as the year component of the current date at
a local time zone. The Local Hour Offset parameter (SPN 1602) is used to indicate if the calendar date (SPNs 962, 963,
and 964) is the current UTC date or a local time zone date. Refer to SPN 1602 for details.
NOTE - A value of 0 for the year identifies the year 1985; a value of 1 identifies 1986; etc.";
CM_ SG_ 2566841884 SDB_Month "The month component of the current calendar date. This should be reported as the month component of the current date
at UTC (Universal Time Coordinate), a.k.a. GMT; however, it may be reported as the month component of the current
date at a local time zone. The Local Hour Offset parameter (SPN 1602) is used to indicate if the calendar date (SPNs
962, 963, and 964) is the current UTC date or a local time zone date. Refer to SPN 1602 for details.
NOTE - A value of 0 for the month is null. The value 1 identifies January; 2 identifies February; etc.";
CM_ SG_ 2566841884 SDB_Hours "The hour component of the current time of day. This should be reported as the hour component of the current time at
UTC (Universal Time Coordinate), a.k.a. GMT; however, it may be reported as the hour component of the current time at
a local time zone. The Local Hour Offset parameter (SPN 1602) is used to indicate if time of day (SPNs 959, 960, and
961) is the current UTC time or a local time zone time. Refer to SPN 1602 for details.";
CM_ SG_ 2566841884 SDB_Minutes "The minutes component of the current time of day. This should be reported as the minutes component of the current time
at UTC (Universal Time Coordinate), a.k.a. GMT; however, it may be reported as the minutes component of the current
time at a local time zone. The Local Hour Offset parameter (SPN 1602) is used to indicate if the time of day (SPNs 959,
960, and 961) is the current UTC time or a local time zone time. Refer to SPN 1602 for details.";
CM_ SG_ 2566841884 SDB_Seconds "The seconds component of the current time of day. This should be reported as the seconds component of the current
time at UTC (Universal Time Coordinate), a.k.a. GMT; however, it may be reported as the seconds component of the
current time at a local time zone. The Local Hour Offset parameter (SPN 1602) is used to indicate if the time of day
(SPNs 959, 960, and 961) is the current UTC time or a local time zone time. Refer to SPN 1602 for details.";
CM_ BO_ 2566849953 "This PGN reports a summary of the the operating parameters of the full battery: serial number, state of charge, state of health, temperature alarm, voltage alarm for the battery.";
CM_ SG_ 2566849953 BMS1_SDB_BatSumS_serial_number "This parameter contains the manufactured serial number of the battery. The lowest 21 bits of this 24 bit serial number are also used in the J1939 NAME – see 2.1.";
CM_ SG_ 2566849953 BMS1_SDB_BatSumS_Reserved_01 "Reserved";
CM_ SG_ 2566849953 BMS1_SDB_BatSumS_State_of_Charge "This parameter contains the ratio of the remaining capacity of the battery to the full capacity expressed as a percentage.";
CM_ SG_ 2566849953 BMS1_SDB_BatSumS_State_of_Health "This parameter contains a value relating to the state of health of the battery based on defined thresholds of the ratio of full capacity to design capacity.";
CM_ SG_ 2566849953 BMS1_SDB_BatSumS_Temp_Alarm "This parameter contains the temperature alarm, based on the maximum battery temperature.
0x00: No fault;
0x01: Low Temperature Alarm
0x02: High Temperature Alarm
0x03: Wrong Temperature Alarm";
CM_ SG_ 2566849953 BMS1_SDB_BatSumS_DischargeDis "This parameter indicates when the battery is not able to be discharged.
0x00: Discharge Enable;
0x01: Discharge Disable";
CM_ SG_ 2566849953 BMS1_SDB_BatSumS_ChargingDisable "This parameter indicates when the battery is not able to be discharged.
0x00: Charging Enable;
0x01: Charging Disable";
CM_ SG_ 2566849953 BMS1_SDB_BatSumS_HeaterEnabled "This parameter indicates when the heater is enabled.
0x00: Heater Disabled;
0x01: Heater Enabled";
CM_ SG_ 2566849953 BMS1_SDB_BatSumS_BypassEnabled "This parameter indicates when the bypass is enabled.
0x00: Bypass Disabled;
0x01: Bypass Enabled";
CM_ SG_ 2566849953 BMS1_SDB_BatSumS_Voltage_Alarm "This parameter indicates an over voltage condition in one or more modules.
0x00: No fault;
0x01:Over Voltage Alarm";
CM_ SG_ 2566849953 BMS1_SDB_BatSumS_Reserved_04 "Reserved";
CM_ SG_ 2566849953 BMS1_SDB_BatSumS_Reserved_05 "Reserved";
CM_ SG_ 2566849953 BMS1_SDB_BatSumS_Reserved_06 "Reserved";
CM_ SG_ 2566849953 BMS1_SDB_BatSumS_Reserved_07 "Reserved";
CM_ SG_ 2566849953 BMS1_SDB_BatSumS_Reserved_08 "Reserved";
CM_ SG_ 2566849953 BMS1_SDB_BatSumS_Reserved_09 "Reserved";
CM_ SG_ 2566849953 BMS1_SDB_BatSumS_Reserved_10 "Reserved";
CM_ SG_ 2566849953 BMS1_SDB_BatSumS_Reserved_11 "Reserved";
CM_ BO_ 2566849697 "Used for debugging purposes.";
CM_ SG_ 2566849697 BMS1_SDB_Debug_0 "Used for debugging purpose - byte 0";
CM_ SG_ 2566849697 BMS1_SDB_Debug_1 "Used for debugging purpose - byte 1";
CM_ SG_ 2566849697 BMS1_SDB_Debug_2 "Used for debugging purpose - byte 2";
CM_ SG_ 2566849697 BMS1_SDB_Debug_3 "Used for debugging purpose - byte 3";
CM_ SG_ 2566849697 BMS1_SDB_Debug_4 "Used for debugging purpose - byte 4";
CM_ SG_ 2566849697 BMS1_SDB_Debug_5 "Used for debugging purpose - byte 5";
CM_ SG_ 2566849697 BMS1_SDB_Debug_6 "Used for debugging purpose - byte 6";
CM_ SG_ 2566849697 BMS1_SDB_Debug_7 "Used for debugging purpose - byte 7";
CM_ BO_ 2566853281 "This PGN reports the remaining module capacity, the expected full module capacity and the designed module capacity for module 3.";
CM_ SG_ 2566853281 BMS1_SDB_M1_Remaining_capacity "This parameter contains the remaining capacity of the battery.";
CM_ SG_ 2566853281 BMS1_SDB_M1_Full_capacity "This parameter contains the full capacity of the battery.";
CM_ SG_ 2566853281 BMS1_SDB_M1_Design_capacity "This parameter contains the design capacity of the battery.";
CM_ SG_ 2566853281 BMS1_SDB_M1_Reserved_Cap "Reserved";
CM_ BO_ 2566853025 "This PGN reports the remaining module capacity, the expected full module capacity and the designed module capacity for module 2.";
CM_ SG_ 2566853025 BMS1_SDB_M2_Remaining_capacity "This parameter contains the remaining capacity of the battery.";
CM_ SG_ 2566853025 BMS1_SDB_M2_Full_capacity "This parameter contains the full capacity of the battery.";
CM_ SG_ 2566853025 BMS1_SDB_M2_Design_capacity "This parameter contains the design capacity of the battery.";
CM_ SG_ 2566853025 BMS1_SDB_M2_Reserved_Cap "Reserved";
CM_ BO_ 2566852769 "This PGN reports the remaining module capacity, the expected full module capacity and the designed module capacity for module 1.";
CM_ SG_ 2566852769 BMS1_SDB_M3_Remaining_capacity "This parameter contains the remaining capacity of the battery.";
CM_ SG_ 2566852769 BMS1_SDB_M3_Full_capacity "This parameter contains the full capacity of the battery.";
CM_ SG_ 2566852769 BMS1_SDB_M3_Design_capacity "This parameter contains the design capacity of the battery.";
CM_ SG_ 2566852769 BMS1_SDB_M3_Reserved_Cap "Reserved";
CM_ BO_ 2566861985 "This PGN reports the total number of software-related events that have occurred during the life of the battery.";
CM_ SG_ 2566861985 BMS1_SDB_WatchdogReset_events "This parameter contains a count of the number times the watchdog has reset the firmware due to an internal lock-up.
Data Range: 0 – 64255. A value of 64255 indicates 64255 events or more.";
CM_ SG_ 2566861985 BMS1_SDB_StackOverflowReset_even "This parameter contains a count of the number times the firmware has been reset due to a stack-overflow.
Data Range: 0 – 64255. A value of 64255 indicates 64255 events or more.";
CM_ SG_ 2566861985 BMS1_SDB_CommandedReset_events "This parameter contains a count of the number times the firmware has been reset by a CAN, USB or status button command.
Data Range: 0 – 64255. A value of 64255 indicates 64255 events or more.";
CM_ SG_ 2566861985 BMS1_SDB_IllegalInstructionReset "This parameter contains a count of the number times the firmware has been hard-reset using the status button.
Data Range: 0 – 64255. A value of 64255 indicates 64255 events or more.";
CM_ BO_ 2566861729 "This PGN reports the total number of voltage-related events that have occurred during the life of the battery.";
CM_ SG_ 2566861729 BMS1_SDB_OverVoltage_events "This parameter contains a count of the number of times an over-voltage event has occurred.";
CM_ SG_ 2566861729 BMS1_SDB_UnderVoltage_events "This parameter contains a count of the number of times an under-voltage event has occurred.";
CM_ BO_ 2566861473 "This PGN reports the total number of current and temperature-related events that have occurred during the life of the battery.";
CM_ SG_ 2566861473 BMS1_SDB_ShortCircuit_events "This parameter contains a count of the number of times the battery has been short-circuited.";
CM_ SG_ 2566861473 BMS1_SDB_CurrentOverload_events "This parameter contains a count of the number of times the battery has been overloaded.";
CM_ SG_ 2566861473 BMS1_SDB_OverCurrent_Charge_ev "This parameter contains a count of the number of times the battery’s maximum charge current has been exceeded.";
CM_ SG_ 2566861473 BMS1_SDB_OverTemperature_ev "This parameter contains a count of the number of times the battery’s maximum temperature has been exceeded.";
CM_ BO_ 2566861217 "This PGN reports on the maximum and minimum battery voltages and currents measured during the life of the battery.";
CM_ SG_ 2566861217 BMS1_SDB_MaximumVoltage "This parameter contains the maximum voltage ever measured across the battery cells.";
CM_ SG_ 2566861217 BMS1_SDB_MinimumVoltage "This parameter contains the minimum voltage ever measured across the battery cells.";
CM_ SG_ 2566861217 BMS1_SDB_MAX_Discharge_Current "This parameter contains the maximum discharge current ever measured on the battery.";
CM_ SG_ 2566861217 BMS1_SDB_MAX_Charge_Current "This parameter contains the maximum charge current ever measured on the battery.";
CM_ BO_ 2566860961 "This PGN reports on the maximum and minimum temperatures experienced during the life of the battery.";
CM_ SG_ 2566860961 BMS1_SDB_Maximum_Life_temp "This parameter contains the maximum temperature ever measured in the battery.";
CM_ SG_ 2566860961 BMS1_SDB_Minimum_Life_temp "This parameter contains the minimum temperature ever measured in the battery.";
CM_ SG_ 2566860961 BMS1_SDB_MAX_Charging_Temp "This parameter contains the maximum temperature ever measured while charging the battery.";
CM_ SG_ 2566860961 BMS1_SDB_MIN_Charging_Temp "This parameter contains the minimum temperature ever measured while charging the battery.";
CM_ BO_ 2566857377 "This PGN reports on the individual discharge switch temperatures within module 3 of the battery. The values are only valid when the discharge current exceeds 10A for the entire battery, at other times the values returned will be the J1939 unavailable value.";
CM_ SG_ 2566857377 BMS1_SDB_M3_Temperature_1 "This parameter contains the temperature of a discharge switch sensor.";
CM_ SG_ 2566857377 BMS1_SDB_M3_Temperature_2 "This parameter contains the temperature of a discharge switch sensor.";
CM_ SG_ 2566857377 BMS1_SDB_M3_Temperature_3 "This parameter contains the temperature of a discharge switch sensor.";
CM_ SG_ 2566857377 BMS1_SDB_M3_Reserved_Dis1 "Reserved";
CM_ SG_ 2566857377 BMS1_SDB_M3_Reserved_Dis2 "Reserved";
CM_ BO_ 2566857121 "This PGN reports on the individual discharge switch temperatures within module 2 of the battery. The values are only valid when the discharge current exceeds 10A for the entire battery, at other times the values returned will be the J1939 unavailable value.";
CM_ SG_ 2566857121 BMS1_SDB_M2_Temperature_1 "This parameter contains the temperature of a discharge switch sensor.";
CM_ SG_ 2566857121 BMS1_SDB_M2_Temperature_2 "This parameter contains the temperature of a discharge switch sensor.";
CM_ SG_ 2566857121 BMS1_SDB_M2_Temperature_3 "This parameter contains the temperature of a discharge switch sensor.";
CM_ SG_ 2566857121 BMS1_SDB_M2_Reserved_Dis1 "Reserved";
CM_ SG_ 2566857121 BMS1_SDB_M2_Reserved_Dis2 "Reserved";
CM_ BO_ 2566856865 "This PGN reports on the individual discharge switch temperatures within module 1 of the battery. The values are only valid when the discharge current exceeds 10A for the entire battery, at other times the values returned will be the J1939 unavailable value.";
CM_ SG_ 2566856865 BMS1_SDB_M1_Temperature_1 "This parameter contains the temperature of a discharge switch sensor.";
CM_ SG_ 2566856865 BMS1_SDB_M1_Temperature_2 "This parameter contains the temperature of a discharge switch sensor.";
CM_ SG_ 2566856865 BMS1_SDB_M1_Temperature_3 "This parameter contains the temperature of a discharge switch sensor.";
CM_ SG_ 2566856865 BMS1_SDB_M1_Reserved_Dis1 "Reserved";
CM_ SG_ 2566856865 BMS1_SDB_M1_Reserved_Dis2 "Reserved";
CM_ BO_ 2566855329 "This PGN reports on the individual temperatures measured within module 3 of the battery.";
CM_ SG_ 2566855329 BMS1_SDB_M3_FuelGauge1_Temp "This parameter contains the temperature measured by the module’s fuel gauge IC.";
CM_ SG_ 2566855329 BMS1_SDB_M3_Thermistor1_temp "This parameter contains the temperature measured by one of the module’s Thermistors.";
CM_ SG_ 2566855329 BMS1_SDB_M3_Thermistor2_temp "This parameter contains the temperature measured by one of the module’s Thermistors.";
CM_ SG_ 2566855329 BMS1_SDB_M3_FuelGauge2_Temp "This parameter contains the temperature measured by the module’s fuel gauge IC.";
CM_ BO_ 2566855073 "This PGN reports on the individual temperatures measured within module 2 of the battery.";
CM_ SG_ 2566855073 BMS1_SDB_M2_FuelGauge1_Temp "This parameter contains the temperature measured by the module’s fuel gauge IC.";
CM_ SG_ 2566855073 BMS1_SDB_M2_Thermistor1_temp "This parameter contains the temperature measured by one of the module’s Thermistors.";
CM_ SG_ 2566855073 BMS1_SDB_M2_Thermistor2_temp "This parameter contains the temperature measured by one of the module’s Thermistors.";
CM_ SG_ 2566855073 BMS1_SDB_M2_FuelGauge2_Temp "This parameter contains the temperature measured by the module’s fuel gauge IC.";
CM_ BO_ 2566854817 "This PGN reports on the individual temperatures measured within module 1 of the battery.";
CM_ SG_ 2566854817 BMS1_SDB_M1_FuelGauge1_Temp "This parameter contains the temperature measured by the module’s fuel gauge IC.";
CM_ SG_ 2566854817 BMS1_SDB_M1_Thermistor1_temp "This parameter contains the temperature measured by one of the module’s Thermistors.";
CM_ SG_ 2566854817 BMS1_SDB_M1_Thermistor2_temp "This parameter contains the temperature measured by one of the module’s Thermistors.";
CM_ SG_ 2566854817 BMS1_SDB_M1_FuelGauge2_Temp "This parameter contains the temperature measured by the module’s fuel gauge IC.";
CM_ BO_ 2566851233 "This PGN reports the operating parameters of module 3 within the battery: output voltage, average current (charge or discharge), the percentage state of charge, a state of health indication and the protection status of the module.";
CM_ SG_ 2566851233 BMS1_SDB_M3_Module_OUT_Voltage "This parameter contains the output voltage of the module.";
CM_ SG_ 2566851233 BMS1_SDB_M3_ModuleAverageCurrent "This parameter contains the charge (positive) or discharge (negative) current of the module averaged over 1 second.";
CM_ SG_ 2566851233 BMS1_SDB_M3_Module_StateOfCharge "This parameter contains the ratio of the remaining capacity of the module to the full capacity of the module expressed as a percentage.";
CM_ SG_ 2566851233 BMS1_SDB_M3_Module_StateOfHealth "This parameter contains a value relating to the state of health of the module based on defined thresholds of the ratio of full capacity to design capacity.";
CM_ SG_ 2566851233 BMS1_SDB_M3_DiscProtectTrigg "This parameter contains the current protection status of the module.
Discharge protection triggered";
CM_ SG_ 2566851233 BMS1_SDB_M3_ChargeProtectTrigg "This parameter contains the current protection status of the module.
Charge protection triggered";
CM_ SG_ 2566851233 BMS1_SDB_M3_ModulesMissingFailed "This parameter contains the current protection status of the module.
Modules missing/failed";
CM_ SG_ 2566851233 BMS1_SDB_M3_OverTemp_detect "This parameter contains the current protection status of the module.
Over-temperature detected";
CM_ SG_ 2566851233 BMS1_SDB_M3_UnderVoltage_detect "This parameter contains the current protection status of the module.
Under-voltage detected";
CM_ SG_ 2566851233 BMS1_SDB_M3_OverVoltage_detected "This parameter contains the current protection status of the module.
Over-voltage detected";
CM_ SG_ 2566851233 BMS1_SDB_M3_Overload_detected "This parameter contains the current protection status of the module.
Overload detected";
CM_ SG_ 2566851233 BMS1_SDB_M3_ShortCircuit_detect "This parameter contains the current protection status of the module.
Short circuit detected";
CM_ SG_ 2566851233 BMS1_SDB_M3_Module_BQ78350 "This parameter contains selected data from the BQ78350 status.
Each bit indicates a different alarm (bit 1 indicates extra 1, bit 2 indicates extra 2 …) where 0 indicates no fault and 1 indicates missing, failed or protection triggered";
CM_ BO_ 2566850977 "This PGN reports the operating parameters of module 2 within the battery: output voltage, average current (charge or discharge), the percentage state of charge, a state of health indication and the protection status of the module.";
CM_ SG_ 2566850977 BMS1_SDB_M2_Module_OUT_Voltage "This parameter contains the output voltage of the module.";
CM_ SG_ 2566850977 BMS1_SDB_M2_ModuleAverageCurrent "This parameter contains the charge (positive) or discharge (negative) current of the module averaged over 1 second.";
CM_ SG_ 2566850977 BMS1_SDB_M2_Module_StateOfCharge "This parameter contains the ratio of the remaining capacity of the module to the full capacity of the module expressed as a percentage.";
CM_ SG_ 2566850977 BMS1_SDB_M2_Module_StateOfHealth "This parameter contains a value relating to the state of health of the module based on defined thresholds of the ratio of full capacity to design capacity.";
CM_ SG_ 2566850977 BMS1_SDB_M2_DiscProtectTrigg "This parameter contains the current protection status of the module.
Discharge protection triggered";
CM_ SG_ 2566850977 BMS1_SDB_M2_ChargeProtectTrigg "This parameter contains the current protection status of the module.
Charge protection triggered";
CM_ SG_ 2566850977 BMS1_SDB_M2_ModulesMissingFailed "This parameter contains the current protection status of the module.
Modules missing/failed";
CM_ SG_ 2566850977 BMS1_SDB_M2_OverTemp_detect "This parameter contains the current protection status of the module.
Over-temperature detected";
CM_ SG_ 2566850977 BMS1_SDB_M2_UnderVoltage_detect "This parameter contains the current protection status of the module.
Under-voltage detected";
CM_ SG_ 2566850977 BMS1_SDB_M2_OverVoltage_detected "This parameter contains the current protection status of the module.
Over-voltage detected";
CM_ SG_ 2566850977 BMS1_SDB_M2_Overload_detected "This parameter contains the current protection status of the module.
Overload detected";
CM_ SG_ 2566850977 BMS1_SDB_M2_ShortCircuit_detect "This parameter contains the current protection status of the module.
Short circuit detected";
CM_ SG_ 2566850977 BMS1_SDB_M2_Module_BQ78350 "This parameter contains selected data from the BQ78350 status.
Each bit indicates a different alarm (bit 1 indicates extra 1, bit 2 indicates extra 2 …) where 0 indicates no fault and 1 indicates missing, failed or protection triggered";
CM_ BO_ 2566850721 "This PGN reports the operating parameters of module 1 within the battery: output voltage, average current (charge or discharge), the percentage state of charge, a state of health indication and the protection status of the module.";
CM_ SG_ 2566850721 BMS1_SDB_M1_Module_OUT_Voltage "This parameter contains the output voltage of the module.";
CM_ SG_ 2566850721 BMS1_SDB_M1_ModuleAverageCurrent "This parameter contains the charge (positive) or discharge (negative) current of the module averaged over 1 second.";
CM_ SG_ 2566850721 BMS1_SDB_M1_Module_StateOfCharge "This parameter contains the ratio of the remaining capacity of the module to the full capacity of the module expressed as a percentage.";
CM_ SG_ 2566850721 BMS1_SDB_M1_Module_StateOfHealth "This parameter contains a value relating to the state of health of the module based on defined thresholds of the ratio of full capacity to design capacity.";
CM_ SG_ 2566850721 BMS1_SDB_M1_DiscProtectTrigg "This parameter contains the current protection status of the module.
Discharge protection triggered";
CM_ SG_ 2566850721 BMS1_SDB_M1_ChargeProtectTrigg "This parameter contains the current protection status of the module.
Charge protection triggered";
CM_ SG_ 2566850721 BMS1_SDB_M1_ModulesMissingFailed "This parameter contains the current protection status of the module.
Modules missing/failed";
CM_ SG_ 2566850721 BMS1_SDB_M1_OverTemp_detect "This parameter contains the current protection status of the module.
Over-temperature detected";
CM_ SG_ 2566850721 BMS1_SDB_M1_UnderVoltage_detect "This parameter contains the current protection status of the module.
Under-voltage detected";
CM_ SG_ 2566850721 BMS1_SDB_M1_OverVoltage_detected "This parameter contains the current protection status of the module.
Over-voltage detected";
CM_ SG_ 2566850721 BMS1_SDB_M1_Overload_detected "This parameter contains the current protection status of the module.
Overload detected";
CM_ SG_ 2566850721 BMS1_SDB_M1_ShortCircuit_detect "This parameter contains the current protection status of the module.
Short circuit detected";
CM_ SG_ 2566850721 BMS1_SDB_M1_Module_BQ78350 "This parameter contains selected data from the BQ78350 status.
Each bit indicates a different alarm (bit 1 indicates extra 1, bit 2 indicates extra 2 …) where 0 indicates no fault and 1 indicates missing, failed or protection triggered";
CM_ BO_ 2566849441 "This PGN reports the battery’s serial and firmware version numbers.";
CM_ SG_ 2566849441 BMS1_SDB_Battery_serial_number "This parameter contains the manufactured serial number of the battery. The lowest 21 bits of this 24 bit serial number are also used in the J1939 NAME – see 2.1.";
CM_ SG_ 2566849441 BMS1_SDB_FirmwareVersionMajor "This parameter contains the major number of the firmware version, i.e. where the firmware has a version XX.YY.ZZZ it represents XX.";
CM_ SG_ 2566849441 BMS1_SDB_FirmwareVersionMinor "This parameter contains the major number of the firmware version, i.e. where the firmware has a version XX.YY.ZZZ it represents YY.";
CM_ SG_ 2566849441 BMS1_SDB_Firmware_Revision "This parameter contains the major number of the firmware version, i.e. where the firmware has a version XX.YY.ZZZ it represents ZZZ.";
CM_ BO_ 2566849185 "This PGN reports the battery temperature. The battery contains a number of temperature sensors which are summarised in this PGN by reporting the maximum, the minimum and the average of all the sensors.";
CM_ SG_ 2566849185 BMS1_SDB_Maximum_Temperature "This parameter contains the highest temperature currently measured within the battery.";
CM_ SG_ 2566849185 BMS1_SDB_Minimum_Temperature "This parameter contains the lowest temperature currently measured within the battery.";
CM_ SG_ 2566849185 BMS1_SDB_Average_Temperature "This parameter contains the average of all the temperatures currently measured within the battery.";
CM_ BO_ 2566848929 "This PGN reports the remaining battery capacity, the expected full battery capacity and the designed battery capacity. If the capacity falls below a defined percentage of the design capacity, the battery enters an alarm state and broadcasts this PGN within 100ms of the event and then repeatedly at 1000ms intervals until the capacity moves above the alarm threshold.";
CM_ SG_ 2566848929 BMS1_SDB_Remaining_capacity "This parameter contains the remaining capacity of the battery.";
CM_ SG_ 2566848929 BMS1_SDB_Full_capacity "This parameter contains the full capacity of the battery.";
CM_ SG_ 2566848929 BMS1_SDB_Design_capacity "This parameter contains the design capacity of the battery.";
CM_ SG_ 2566848929 BMS1_SDB_Overall_10_alarm "This parameter contains fields indicating which, if any, capacity alarm thresholds have been triggered.
Overall – less than 10% of design capacity remaining";
CM_ SG_ 2566848929 BMS1_SDB_Silent_Watch_20_alarm "This parameter contains fields indicating which, if any, capacity alarm thresholds have been triggered.
Silent watch – less than 20% silent watch threshold";
CM_ SG_ 2566848929 BMS1_SDB_EngStartCapacity_alarm "This parameter contains fields indicating which, if any, capacity alarm thresholds have been triggered.
Engine start – capacity below engine start threshold";
CM_ SG_ 2566848929 BMS1_SDB_10_Reserved_4 "Not used";
CM_ SG_ 2566848929 BMS1_SDB_10_Reserved_5 "Not used";
CM_ SG_ 2566848929 BMS1_SDB_10_Reserved_6 "Not used";
CM_ SG_ 2566848929 BMS1_SDB_10_Reserved_7 "Not used";
CM_ SG_ 2566848929 BMS1_SDB_10_Reserved_8 "Not used";
CM_ BO_ 2566848673 "This PGN reports the normal operating parameters of the battery: output voltage, average current (charge or discharge), the percentage state of charge and a state of health indication.
The PGN is broadcast at 1000ms intervals or can be requested.";
CM_ SG_ 2566848673 BMS1_SDB_Batt_OUT_Voltage "This parameter contains the output voltage of the battery.
It only specifies the voltage of the internal modules that are available for discharge: any module which is in over-temperature or under-voltage protection is not included in this figure because it has been internally disconnected.";
CM_ SG_ 2566848673 BMS1_SDB_Batt_Average_Current "This parameter contains the charge (positive) or discharge (negative) current of the battery averaged over 1 second.";
CM_ SG_ 2566848673 BMS1_SDB_Batt_StsOfCharge "This parameter contains the ratio of the remaining capacity of the battery to the full capacity expressed as a percentage.";
CM_ SG_ 2566848673 BMS1_SDB_Batt_StsOfHealth "This parameter contains a value relating to the state of health of the battery based on defined thresholds of the ratio of full capacity to design capacity.";
CM_ SG_ 2566848673 BMS1_SDB_Batt_PS8_discharge_prot "This parameter contains the current protection status of the battery.
Discharge protection triggered.";
CM_ SG_ 2566848673 BMS1_SDB_Batt_PS7_charge_prot "This parameter contains the current protection status of the battery.
Charge protection triggered.";
CM_ SG_ 2566848673 BMS1_SDB_Batt_PS6_mod_failed "This parameter contains the current protection status of the battery.
1 or more modules missing/failed.";
CM_ SG_ 2566848673 BMS1_SDB_Batt_PS5_over_temp "This parameter contains the current protection status of the battery.
Over-temperature detected.";
CM_ SG_ 2566848673 BMS1_SDB_Batt_PS4_under_voltage "This parameter contains the current protection status of the battery.
Under-voltage detected.";
CM_ SG_ 2566848673 BMS1_SDB_Batt_PS3_over_voltage "This parameter contains the current protection status of the battery.
Over-voltage detected.";
CM_ SG_ 2566848673 BMS1_SDB_Batt_PS2_overload "This parameter contains the current protection status of the battery.
Overload detected.";
CM_ SG_ 2566848673 BMS1_SDB_Batt_PS1_short_circuit "This parameter contains the current protection status of the battery.
Short circuit detected.";
CM_ SG_ 2566848673 BMS1_SDB_Batt_OS_8_sleep_mode "This parameter contains the status bits indicating the current state of the emergency load-dump, emergency override, heater and charger controls along with the master protection status bit.
Sleep mode pending (1 = sleep pending, 0 = awake)";
CM_ SG_ 2566848673 BMS1_SDB_Batt_OS_7_emerg_used "This parameter contains the status bits indicating the current state of the emergency load-dump, emergency override, heater and charger controls along with the master protection status bit.
Emergency override used (1= used, 0 = never used)";
CM_ SG_ 2566848673 BMS1_SDB_Batt_OS_6_emergency "This parameter contains the status bits indicating the current state of the emergency load-dump, emergency override, heater and charger controls along with the master protection status bit.
Emergency override (1 = active, 0 = inactive)";
CM_ SG_ 2566848673 BMS1_SDB_Batt_OS_45_charge_level "This parameter contains the status bits indicating the current state of the emergency load-dump, emergency override, heater and charger controls along with the master protection status bit.
Charge level (0 = off, 1 = 25%, 2 = 50%, 3 = full)";
CM_ SG_ 2566848673 BMS1_SDB_Batt_OS_3_charge_cont "This parameter contains the status bits indicating the current state of the emergency load-dump, emergency override, heater and charger controls along with the master protection status bit.
Charge control (1 = on, 0 = off)";
CM_ SG_ 2566848673 BMS1_SDB_Batt_OS_2_heater_cont "This parameter contains the status bits indicating the current state of the emergency load-dump, emergency override, heater and charger controls along with the master protection status bit.
Heater control (1 = on, 0 = off)";
CM_ SG_ 2566848673 BMS1_SDB_Batt_OS_1_master_prot "This parameter contains the status bits indicating the current state of the emergency load-dump, emergency override, heater and charger controls along with the master protection status bit.
Master protect (1 = protect, 0 = off)";
CM_ BO_ 2566804129 "This contains high resolution/range parameters reported from the alternator or power generation components.";
CM_ SG_ 2566804129 _nu_BMS1_SDB_AlternatorCurrent "SPN 1795 Alternator Current (High Range/Resolution)
This parameter indicates the amount of electrical current output from the alternator of the main vehicle. Alternator Current
(SPN 115) has a lower range and resolution.";
CM_ SG_ 2566804129 BMS1_SDB_NetBattery_Current "SPN 2579 Net Battery Current (High Range/Resolution)
Net flow of electrical current into/out-of the battery or batteries. This parameter is the high range and resolution of SPN
114 - Net Battery Current.";
CM_ BO_ 2566803617 "Contains battery temperature information.";
CM_ SG_ 2566803617 BMS1_SDB_Battery1_Temperature "Temperature of the battery 1. The relation to physical location is determined by the equipment manufacturer.";
CM_ SG_ 2566803617 _nu_BMS1_SDB_Battery2_Temp "Temperature of the battery 2. The relation to physical location is determined by the equipment manufacturer.";
CM_ BO_ 2566698657 "PGN containing vehicle electrical power information for the battery pack used for starting, lighting, and ignition.";
CM_ SG_ 2566698657 BMS1_SDB_SLI_BattPack_StOfCharge "5981
SLI Battery Pack State of Charge
Indicates the remaining charge of the battery pack used for starting the engine, for lighting, and for ignition (SLI). 0% means no charge remaining, 100% means full capacity at the battery pack's current state of health.   See SPN 5464 for hybrid battery pack.";
CM_ SG_ 2566698657 BMS1_SDB_SLI_BattPack_Capacity "5982
SLI Battery Pack Capacity
Original or rated total reserve capacity of the battery pack used for starting the engine, for lighting, and for ignition (SLI).";
CM_ SG_ 2566698657 BMS1_SDB_SLI_BattPack_Health "5983
SLI Battery Pack Health
Capacity of the battery pack relative to its original specification for the battery pack used for starting the engine, for lighting, and for ignition (SLI). 0% means battery pack is not capable of holding any charge, 100% means battery pack is capable of holding its original full capacity.";
CM_ BO_ 2566862241 "This PGN reports the total number of software-related events that have occurred during the life of the battery.";
CM_ SG_ 2566862241 BMS1_SDB_HardMCLRReset_events "This parameter contains a count of the number times the MCLR has reset the firmware due to a hardware reset pulse, this may be due to the external watchdog.
Data Range: 0 – 64255. A value of 64255 indicates 64255 events or more.";
CM_ SG_ 2566862241 BMS1_SDB_LowVoltageReset_events "TThis parameter contains a count of the number times the firmware has been reset due to the processor detecting a low supply voltage.
Data Range: 0 – 64255. A value of 64255 indicates 64255 events or more.";
CM_ SG_ 2566862241 BMS1_SDB_PORReset_events "This parameter contains a count of the number times the firmware has been started from a power up condition.
Data Range: 0 – 64255. A value of 64255 indicates 64255 events or more.";
CM_ SG_ 2566862241 BMS1_SDB_BrownOutReset_events "This parameter contains a count of the number times the firmware has been restarted due to a brown-out (below 2.7V).
Data Range: 0 – 64255. A value of 64255 indicates 64255 events or more.";
CM_ BO_ 2565799841 "Generic message for send the NAME
Used only for the BMS1";
CM_ SG_ 2565799841 BMS1_SDB_VehicleSystemInstance "Vehicle System Instance";
CM_ SG_ 2565799841 BMS1_SDB_IndustryGroup "Industry Group";
CM_ SG_ 2565799841 BMS1_SDB_Name_Reserved "Reserved";
CM_ SG_ 2565799841 BMS1_SDB_ECUInstance "ECU Instance";
CM_ SG_ 2565799841 BMS1_SDB_IdentityNumber_3 "Most significant 5 bits of Identity Number";
CM_ SG_ 2565799841 BMS1_SDB_ArbitraryAddressCapable "Arbitrary Address Capable";
CM_ SG_ 2565799841 BMS1_SDB_VehicleSystem "Vehicle System";
CM_ SG_ 2565799841 BMS1_SDB_Function "Function";
CM_ SG_ 2565799841 BMS1_SDB_FunctionInstance "Function Instance";
CM_ SG_ 2565799841 BMS1_SDB_ManufacturerCode_2 "Most significant 8 bits of Manufacturer Code";
CM_ SG_ 2565799841 BMS1_SDB_ManufacturerCode_1 "Least significant 3 bits of Manufacturer Code";
CM_ SG_ 2565799841 BMS1_SDB_IdentityNumber_2 "Second byte of Identity Number";
CM_ SG_ 2565799841 BMS1_SDB_IdentityNumber_1 "Least significant byte of Identity Number";
CM_ BO_ 2566849954 "This PGN reports a summary of the the operating parameters of the full battery: serial number, state of charge, state of health, temperature alarm, voltage alarm for the battery.";
CM_ SG_ 2566849954 BMS2_SDB_BatSumS_serial_number "This parameter contains the manufactured serial number of the battery. The lowest 21 bits of this 24 bit serial number are also used in the J1939 NAME – see 2.1.";
CM_ SG_ 2566849954 BMS2_SDB_BatSumS_Reserved_01 "Reserved";
CM_ SG_ 2566849954 BMS2_SDB_BatSumS_State_of_Charge "This parameter contains the ratio of the remaining capacity of the battery to the full capacity expressed as a percentage.";
CM_ SG_ 2566849954 BMS2_SDB_BatSumS_State_of_Health "This parameter contains a value relating to the state of health of the battery based on defined thresholds of the ratio of full capacity to design capacity.";
CM_ SG_ 2566849954 BMS2_SDB_BatSumS_Temp_Alarm "This parameter contains the temperature alarm, based on the maximum battery temperature.
0x00: No fault;
0x01: Low Temperature Alarm
0x02: High Temperature Alarm
0x03: Wrong Temperature Alarm";
CM_ SG_ 2566849954 BMS2_SDB_BatSumS_DischargeDis "This parameter indicates when the battery is not able to be discharged.
0x00: Discharge Enable;
0x01: Discharge Disable";
CM_ SG_ 2566849954 BMS2_SDB_BatSumS_ChargingDisable "This parameter indicates when the battery is not able to be discharged.
0x00: Charging Enable;
0x01: Charging Disable";
CM_ SG_ 2566849954 BMS2_SDB_BatSumS_HeaterEnabled "This parameter indicates when the heater is enabled.
0x00: Heater Disabled;
0x01: Heater Enabled";
CM_ SG_ 2566849954 BMS2_SDB_BatSumS_BypassEnabled "This parameter indicates when the bypass is enabled.
0x00: Bypass Disabled;
0x01: Bypass Enabled";
CM_ SG_ 2566849954 BMS2_SDB_BatSumS_Voltage_Alarm "This parameter indicates an over voltage condition in one or more modules.
0x00: No fault;
0x01:Over Voltage Alarm";
CM_ SG_ 2566849954 BMS2_SDB_BatSumS_Reserved_04 "Reserved";
CM_ SG_ 2566849954 BMS2_SDB_BatSumS_Reserved_05 "Reserved";
CM_ SG_ 2566849954 BMS2_SDB_BatSumS_Reserved_06 "Reserved";
CM_ SG_ 2566849954 BMS2_SDB_BatSumS_Reserved_07 "Reserved";
CM_ SG_ 2566849954 BMS2_SDB_BatSumS_Reserved_08 "Reserved";
CM_ SG_ 2566849954 BMS2_SDB_BatSumS_Reserved_09 "Reserved";
CM_ SG_ 2566849954 BMS2_SDB_BatSumS_Reserved_10 "Reserved";
CM_ SG_ 2566849954 BMS2_SDB_BatSumS_Reserved_11 "Reserved";
CM_ BO_ 2566849698 "Used for debugging purposes.";
CM_ SG_ 2566849698 BMS2_SDB_Debug_0 "Used for debugging purpose - byte 0";
CM_ SG_ 2566849698 BMS2_SDB_Debug_1 "Used for debugging purpose - byte 1";
CM_ SG_ 2566849698 BMS2_SDB_Debug_2 "Used for debugging purpose - byte 2";
CM_ SG_ 2566849698 BMS2_SDB_Debug_3 "Used for debugging purpose - byte 3";
CM_ SG_ 2566849698 BMS2_SDB_Debug_4 "Used for debugging purpose - byte 4";
CM_ SG_ 2566849698 BMS2_SDB_Debug_5 "Used for debugging purpose - byte 5";
CM_ SG_ 2566849698 BMS2_SDB_Debug_6 "Used for debugging purpose - byte 6";
CM_ SG_ 2566849698 BMS2_SDB_Debug_7 "Used for debugging purpose - byte 7";
CM_ BO_ 2566853282 "This PGN reports the remaining module capacity, the expected full module capacity and the designed module capacity for module 3.";
CM_ SG_ 2566853282 BMS2_SDB_M1_Remaining_capacity "This parameter contains the remaining capacity of the battery.";
CM_ SG_ 2566853282 BMS2_SDB_M1_Full_capacity "This parameter contains the full capacity of the battery.";
CM_ SG_ 2566853282 BMS2_SDB_M1_Design_capacity "This parameter contains the design capacity of the battery.";
CM_ SG_ 2566853282 BMS2_SDB_M1_Reserved_Cap "Reserved";
CM_ BO_ 2566853026 "This PGN reports the remaining module capacity, the expected full module capacity and the designed module capacity for module 2.";
CM_ SG_ 2566853026 BMS2_SDB_M2_Remaining_capacity "This parameter contains the remaining capacity of the battery.";
CM_ SG_ 2566853026 BMS2_SDB_M2_Full_capacity "This parameter contains the full capacity of the battery.";
CM_ SG_ 2566853026 BMS2_SDB_M2_Design_capacity "This parameter contains the design capacity of the battery.";
CM_ SG_ 2566853026 BMS2_SDB_M2_Reserved_Cap "Reserved";
CM_ BO_ 2566852770 "This PGN reports the remaining module capacity, the expected full module capacity and the designed module capacity for module 1.";
CM_ SG_ 2566852770 BMS2_SDB_M3_Remaining_capacity "This parameter contains the remaining capacity of the battery.";
CM_ SG_ 2566852770 BMS2_SDB_M3_Full_capacity "This parameter contains the full capacity of the battery.";
CM_ SG_ 2566852770 BMS2_SDB_M3_Design_capacity "This parameter contains the design capacity of the battery.";
CM_ SG_ 2566852770 BMS2_SDB_M3_Reserved_Cap "Reserved";
CM_ BO_ 2566861986 "This PGN reports the total number of software-related events that have occurred during the life of the battery.";
CM_ SG_ 2566861986 BMS2_SDB_WatchdogReset_events "This parameter contains a count of the number times the watchdog has reset the firmware due to an internal lock-up.
Data Range: 0 – 64255. A value of 64255 indicates 64255 events or more.";
CM_ SG_ 2566861986 BMS2_SDB_StackOverflowReset_even "This parameter contains a count of the number times the firmware has been reset due to a stack-overflow.
Data Range: 0 – 64255. A value of 64255 indicates 64255 events or more.";
CM_ SG_ 2566861986 BMS2_SDB_CommandedReset_events "This parameter contains a count of the number times the firmware has been reset by a CAN, USB or status button command.
Data Range: 0 – 64255. A value of 64255 indicates 64255 events or more.";
CM_ SG_ 2566861986 BMS2_SDB_IllegalInstructionReset "This parameter contains a count of the number times the firmware has been hard-reset using the status button.
Data Range: 0 – 64255. A value of 64255 indicates 64255 events or more.";
CM_ BO_ 2566861730 "This PGN reports the total number of voltage-related events that have occurred during the life of the battery.";
CM_ SG_ 2566861730 BMS2_SDB_OverVoltage_events "This parameter contains a count of the number of times an over-voltage event has occurred.";
CM_ SG_ 2566861730 BMS2_SDB_UnderVoltage_events "This parameter contains a count of the number of times an under-voltage event has occurred.";
CM_ BO_ 2566861474 "This PGN reports the total number of current and temperature-related events that have occurred during the life of the battery.";
CM_ SG_ 2566861474 BMS2_SDB_ShortCircuit_events "This parameter contains a count of the number of times the battery has been short-circuited.";
CM_ SG_ 2566861474 BMS2_SDB_CurrentOverload_events "This parameter contains a count of the number of times the battery has been overloaded.";
CM_ SG_ 2566861474 BMS2_SDB_OverCurrent_Charge_ev "This parameter contains a count of the number of times the battery’s maximum charge current has been exceeded.";
CM_ SG_ 2566861474 BMS2_SDB_OverTemperature_ev "This parameter contains a count of the number of times the battery’s maximum temperature has been exceeded.";
CM_ BO_ 2566861218 "This PGN reports on the maximum and minimum battery voltages and currents measured during the life of the battery.";
CM_ SG_ 2566861218 BMS2_SDB_MaximumVoltage "This parameter contains the maximum voltage ever measured across the battery cells.";
CM_ SG_ 2566861218 BMS2_SDB_MinimumVoltage "This parameter contains the minimum voltage ever measured across the battery cells.";
CM_ SG_ 2566861218 BMS2_SDB_MAX_Discharge_Current "This parameter contains the maximum discharge current ever measured on the battery.";
CM_ SG_ 2566861218 BMS2_SDB_MAX_Charge_Current "This parameter contains the maximum charge current ever measured on the battery.";
CM_ BO_ 2566860962 "This PGN reports on the maximum and minimum temperatures experienced during the life of the battery.";
CM_ SG_ 2566860962 BMS2_SDB_Maximum_Life_temp "This parameter contains the maximum temperature ever measured in the battery.";
CM_ SG_ 2566860962 BMS2_SDB_Minimum_Life_temp "This parameter contains the minimum temperature ever measured in the battery.";
CM_ SG_ 2566860962 BMS2_SDB_MAX_Charging_Temp "This parameter contains the maximum temperature ever measured while charging the battery.";
CM_ SG_ 2566860962 BMS2_SDB_MIN_Charging_Temp "This parameter contains the minimum temperature ever measured while charging the battery.";
CM_ BO_ 2566857378 "This PGN reports on the individual discharge switch temperatures within module 3 of the battery. The values are only valid when the discharge current exceeds 10A for the entire battery, at other times the values returned will be the J1939 unavailable value.";
CM_ SG_ 2566857378 BMS2_SDB_M3_Temperature_1 "This parameter contains the temperature of a discharge switch sensor.";
CM_ SG_ 2566857378 BMS2_SDB_M3_Temperature_2 "This parameter contains the temperature of a discharge switch sensor.";
CM_ SG_ 2566857378 BMS2_SDB_M3_Temperature_3 "This parameter contains the temperature of a discharge switch sensor.";
CM_ SG_ 2566857378 BMS2_SDB_M3_Reserved_Dis1 "Reserved";
CM_ SG_ 2566857378 BMS2_SDB_M3_Reserved_Dis2 "Reserved";
CM_ BO_ 2566857122 "This PGN reports on the individual discharge switch temperatures within module 2 of the battery. The values are only valid when the discharge current exceeds 10A for the entire battery, at other times the values returned will be the J1939 unavailable value.";
CM_ SG_ 2566857122 BMS2_SDB_M2_Temperature_1 "This parameter contains the temperature of a discharge switch sensor.";
CM_ SG_ 2566857122 BMS2_SDB_M2_Temperature_2 "This parameter contains the temperature of a discharge switch sensor.";
CM_ SG_ 2566857122 BMS2_SDB_M2_Temperature_3 "This parameter contains the temperature of a discharge switch sensor.";
CM_ SG_ 2566857122 BMS2_SDB_M2_Reserved_Dis1 "Reserved";
CM_ SG_ 2566857122 BMS2_SDB_M2_Reserved_Dis2 "Reserved";
CM_ BO_ 2566856866 "This PGN reports on the individual discharge switch temperatures within module 1 of the battery. The values are only valid when the discharge current exceeds 10A for the entire battery, at other times the values returned will be the J1939 unavailable value.";
CM_ SG_ 2566856866 BMS2_SDB_M1_Temperature_1 "This parameter contains the temperature of a discharge switch sensor.";
CM_ SG_ 2566856866 BMS2_SDB_M1_Temperature_2 "This parameter contains the temperature of a discharge switch sensor.";
CM_ SG_ 2566856866 BMS2_SDB_M1_Temperature_3 "This parameter contains the temperature of a discharge switch sensor.";
CM_ SG_ 2566856866 BMS2_SDB_M1_Reserved_Dis1 "Reserved";
CM_ SG_ 2566856866 BMS2_SDB_M1_Reserved_Dis2 "Reserved";
CM_ BO_ 2566855330 "This PGN reports on the individual temperatures measured within module 3 of the battery.";
CM_ SG_ 2566855330 BMS2_SDB_M3_FuelGauge1_Temp "This parameter contains the temperature measured by the module’s fuel gauge IC.";
CM_ SG_ 2566855330 BMS2_SDB_M3_Thermistor1_temp "This parameter contains the temperature measured by one of the module’s Thermistors.";
CM_ SG_ 2566855330 BMS2_SDB_M3_Thermistor2_temp "This parameter contains the temperature measured by one of the module’s Thermistors.";
CM_ SG_ 2566855330 BMS2_SDB_M3_FuelGauge2_Temp "This parameter contains the temperature measured by the module’s fuel gauge IC.";
CM_ BO_ 2566855074 "This PGN reports on the individual temperatures measured within module 2 of the battery.";
CM_ SG_ 2566855074 BMS2_SDB_M2_FuelGauge1_Temp "This parameter contains the temperature measured by the module’s fuel gauge IC.";
CM_ SG_ 2566855074 BMS2_SDB_M2_Thermistor1_temp "This parameter contains the temperature measured by one of the module’s Thermistors.";
CM_ SG_ 2566855074 BMS2_SDB_M2_Thermistor2_temp "This parameter contains the temperature measured by one of the module’s Thermistors.";
CM_ SG_ 2566855074 BMS2_SDB_M2_FuelGauge2_Temp "This parameter contains the temperature measured by the module’s fuel gauge IC.";
CM_ BO_ 2566854818 "This PGN reports on the individual temperatures measured within module 1 of the battery.";
CM_ SG_ 2566854818 BMS2_SDB_M1_FuelGauge1_Temp "This parameter contains the temperature measured by the module’s fuel gauge IC.";
CM_ SG_ 2566854818 BMS2_SDB_M1_Thermistor1_temp "This parameter contains the temperature measured by one of the module’s Thermistors.";
CM_ SG_ 2566854818 BMS2_SDB_M1_Thermistor2_temp "This parameter contains the temperature measured by one of the module’s Thermistors.";
CM_ SG_ 2566854818 BMS2_SDB_M1_FuelGauge2_Temp "This parameter contains the temperature measured by the module’s fuel gauge IC.";
CM_ BO_ 2566851234 "This PGN reports the operating parameters of module 3 within the battery: output voltage, average current (charge or discharge), the percentage state of charge, a state of health indication and the protection status of the module.";
CM_ SG_ 2566851234 BMS2_SDB_M3_Module_OUT_Voltage "This parameter contains the output voltage of the module.";
CM_ SG_ 2566851234 BMS2_SDB_M3_ModuleAverageCurrent "This parameter contains the charge (positive) or discharge (negative) current of the module averaged over 1 second.";
CM_ SG_ 2566851234 BMS2_SDB_M3_Module_StateOfCharge "This parameter contains the ratio of the remaining capacity of the module to the full capacity of the module expressed as a percentage.";
CM_ SG_ 2566851234 BMS2_SDB_M3_Module_StateOfHealth "This parameter contains a value relating to the state of health of the module based on defined thresholds of the ratio of full capacity to design capacity.";
CM_ SG_ 2566851234 BMS2_SDB_M3_DiscProtectTrigg "This parameter contains the current protection status of the module.
Discharge protection triggered";
CM_ SG_ 2566851234 BMS2_SDB_M3_ChargeProtectTrigg "This parameter contains the current protection status of the module.
Charge protection triggered";
CM_ SG_ 2566851234 BMS2_SDB_M3_ModulesMissingFailed "This parameter contains the current protection status of the module.
Modules missing/failed";
CM_ SG_ 2566851234 BMS2_SDB_M3_OverTemp_detect "This parameter contains the current protection status of the module.
Over-temperature detected";
CM_ SG_ 2566851234 BMS2_SDB_M3_UnderVoltage_detect "This parameter contains the current protection status of the module.
Under-voltage detected";
CM_ SG_ 2566851234 BMS2_SDB_M3_OverVoltage_detected "This parameter contains the current protection status of the module.
Over-voltage detected";
CM_ SG_ 2566851234 BMS2_SDB_M3_Overload_detected "This parameter contains the current protection status of the module.
Overload detected";
CM_ SG_ 2566851234 BMS2_SDB_M3_ShortCircuit_detect "This parameter contains the current protection status of the module.
Short circuit detected";
CM_ SG_ 2566851234 BMS2_SDB_M3_Module_BQ78350 "This parameter contains selected data from the BQ78350 status.
Each bit indicates a different alarm (bit 1 indicates extra 1, bit 2 indicates extra 2 …) where 0 indicates no fault and 1 indicates missing, failed or protection triggered";
CM_ BO_ 2566850978 "This PGN reports the operating parameters of module 2 within the battery: output voltage, average current (charge or discharge), the percentage state of charge, a state of health indication and the protection status of the module.";
CM_ SG_ 2566850978 BMS2_SDB_M2_Module_OUT_Voltage "This parameter contains the output voltage of the module.";
CM_ SG_ 2566850978 BMS2_SDB_M2_ModuleAverageCurrent "This parameter contains the charge (positive) or discharge (negative) current of the module averaged over 1 second.";
CM_ SG_ 2566850978 BMS2_SDB_M2_Module_StateOfCharge "This parameter contains the ratio of the remaining capacity of the module to the full capacity of the module expressed as a percentage.";
CM_ SG_ 2566850978 BMS2_SDB_M2_Module_StateOfHealth "This parameter contains a value relating to the state of health of the module based on defined thresholds of the ratio of full capacity to design capacity.";
CM_ SG_ 2566850978 BMS2_SDB_M2_DiscProtectTrigg "This parameter contains the current protection status of the module.
Discharge protection triggered";
CM_ SG_ 2566850978 BMS2_SDB_M2_ChargeProtectTrigg "This parameter contains the current protection status of the module.
Charge protection triggered";
CM_ SG_ 2566850978 BMS2_SDB_M2_ModulesMissingFailed "This parameter contains the current protection status of the module.
Modules missing/failed";
CM_ SG_ 2566850978 BMS2_SDB_M2_OverTemp_detect "This parameter contains the current protection status of the module.
Over-temperature detected";
CM_ SG_ 2566850978 BMS2_SDB_M2_UnderVoltage_detect "This parameter contains the current protection status of the module.
Under-voltage detected";
CM_ SG_ 2566850978 BMS2_SDB_M2_OverVoltage_detected "This parameter contains the current protection status of the module.
Over-voltage detected";
CM_ SG_ 2566850978 BMS2_SDB_M2_Overload_detected "This parameter contains the current protection status of the module.
Overload detected";
CM_ SG_ 2566850978 BMS2_SDB_M2_ShortCircuit_detect "This parameter contains the current protection status of the module.
Short circuit detected";
CM_ SG_ 2566850978 BMS2_SDB_M2_Module_BQ78350 "This parameter contains selected data from the BQ78350 status.
Each bit indicates a different alarm (bit 1 indicates extra 1, bit 2 indicates extra 2 …) where 0 indicates no fault and 1 indicates missing, failed or protection triggered";
CM_ BO_ 2566850722 "This PGN reports the operating parameters of module 1 within the battery: output voltage, average current (charge or discharge), the percentage state of charge, a state of health indication and the protection status of the module.";
CM_ SG_ 2566850722 BMS2_SDB_M1_Module_OUT_Voltage "This parameter contains the output voltage of the module.";
CM_ SG_ 2566850722 BMS2_SDB_M1_ModuleAverageCurrent "This parameter contains the charge (positive) or discharge (negative) current of the module averaged over 1 second.";
CM_ SG_ 2566850722 BMS2_SDB_M1_Module_StateOfCharge "This parameter contains the ratio of the remaining capacity of the module to the full capacity of the module expressed as a percentage.";
CM_ SG_ 2566850722 BMS2_SDB_M1_Module_StateOfHealth "This parameter contains a value relating to the state of health of the module based on defined thresholds of the ratio of full capacity to design capacity.";
CM_ SG_ 2566850722 BMS2_SDB_M1_DiscProtectTrigg "This parameter contains the current protection status of the module.
Discharge protection triggered";
CM_ SG_ 2566850722 BMS2_SDB_M1_ChargeProtectTrigg "This parameter contains the current protection status of the module.
Charge protection triggered";
CM_ SG_ 2566850722 BMS2_SDB_M1_ModulesMissingFailed "This parameter contains the current protection status of the module.
Modules missing/failed";
CM_ SG_ 2566850722 BMS2_SDB_M1_OverTemp_detect "This parameter contains the current protection status of the module.
Over-temperature detected";
CM_ SG_ 2566850722 BMS2_SDB_M1_UnderVoltage_detect "This parameter contains the current protection status of the module.
Under-voltage detected";
CM_ SG_ 2566850722 BMS2_SDB_M1_OverVoltage_detected "This parameter contains the current protection status of the module.
Over-voltage detected";
CM_ SG_ 2566850722 BMS2_SDB_M1_Overload_detected "This parameter contains the current protection status of the module.
Overload detected";
CM_ SG_ 2566850722 BMS2_SDB_M1_ShortCircuit_detect "This parameter contains the current protection status of the module.
Short circuit detected";
CM_ SG_ 2566850722 BMS2_SDB_M1_Module_BQ78350 "This parameter contains selected data from the BQ78350 status.
Each bit indicates a different alarm (bit 1 indicates extra 1, bit 2 indicates extra 2 …) where 0 indicates no fault and 1 indicates missing, failed or protection triggered";
CM_ BO_ 2566849442 "This PGN reports the battery’s serial and firmware version numbers.";
CM_ SG_ 2566849442 BMS2_SDB_Battery_serial_number "This parameter contains the manufactured serial number of the battery. The lowest 21 bits of this 24 bit serial number are also used in the J1939 NAME – see 2.1.";
CM_ SG_ 2566849442 BMS2_SDB_FirmwareVersionMajor "This parameter contains the major number of the firmware version, i.e. where the firmware has a version XX.YY.ZZZ it represents XX.";
CM_ SG_ 2566849442 BMS2_SDB_FirmwareVersionMinor "This parameter contains the major number of the firmware version, i.e. where the firmware has a version XX.YY.ZZZ it represents YY.";
CM_ SG_ 2566849442 BMS2_SDB_Firmware_Revision "This parameter contains the major number of the firmware version, i.e. where the firmware has a version XX.YY.ZZZ it represents ZZZ.";
CM_ BO_ 2566849186 "This PGN reports the battery temperature. The battery contains a number of temperature sensors which are summarised in this PGN by reporting the maximum, the minimum and the average of all the sensors.";
CM_ SG_ 2566849186 BMS2_SDB_Maximum_Temperature "This parameter contains the highest temperature currently measured within the battery.";
CM_ SG_ 2566849186 BMS2_SDB_Minimum_Temperature "This parameter contains the lowest temperature currently measured within the battery.";
CM_ SG_ 2566849186 BMS2_SDB_Average_Temperature "This parameter contains the average of all the temperatures currently measured within the battery.";
CM_ BO_ 2566848930 "This PGN reports the remaining battery capacity, the expected full battery capacity and the designed battery capacity. If the capacity falls below a defined percentage of the design capacity, the battery enters an alarm state and broadcasts this PGN within 100ms of the event and then repeatedly at 1000ms intervals until the capacity moves above the alarm threshold.";
CM_ SG_ 2566848930 BMS2_SDB_Remaining_capacity "This parameter contains the remaining capacity of the battery.";
CM_ SG_ 2566848930 BMS2_SDB_Full_capacity "This parameter contains the full capacity of the battery.";
CM_ SG_ 2566848930 BMS2_SDB_Design_capacity "This parameter contains the design capacity of the battery.";
CM_ SG_ 2566848930 BMS2_SDB_Overall_10_alarm "This parameter contains fields indicating which, if any, capacity alarm thresholds have been triggered.
Overall – less than 10% of design capacity remaining";
CM_ SG_ 2566848930 BMS2_SDB_Silent_Watch_20_alarm "This parameter contains fields indicating which, if any, capacity alarm thresholds have been triggered.
Silent watch – less than 20% silent watch threshold";
CM_ SG_ 2566848930 BMS2_SDB_EngStartCapacity_alarm "This parameter contains fields indicating which, if any, capacity alarm thresholds have been triggered.
Engine start – capacity below engine start threshold";
CM_ SG_ 2566848930 BMS2_SDB_10_Reserved_4 "Not used";
CM_ SG_ 2566848930 BMS2_SDB_10_Reserved_5 "Not used";
CM_ SG_ 2566848930 BMS2_SDB_10_Reserved_6 "Not used";
CM_ SG_ 2566848930 BMS2_SDB_10_Reserved_7 "Not used";
CM_ SG_ 2566848930 BMS2_SDB_10_Reserved_8 "Not used";
CM_ BO_ 2566848674 "This PGN reports the normal operating parameters of the battery: output voltage, average current (charge or discharge), the percentage state of charge and a state of health indication.
The PGN is broadcast at 1000ms intervals or can be requested.";
CM_ SG_ 2566848674 BMS2_SDB_Batt_OUT_Voltage "This parameter contains the output voltage of the battery.
It only specifies the voltage of the internal modules that are available for discharge: any module which is in over-temperature or under-voltage protection is not included in this figure because it has been internally disconnected.";
CM_ SG_ 2566848674 BMS2_SDB_Batt_Average_Current "This parameter contains the charge (positive) or discharge (negative) current of the battery averaged over 1 second.";
CM_ SG_ 2566848674 BMS2_SDB_Batt_StsOfCharge "This parameter contains the ratio of the remaining capacity of the battery to the full capacity expressed as a percentage.";
CM_ SG_ 2566848674 BMS2_SDB_Batt_StsOfHealth "This parameter contains a value relating to the state of health of the battery based on defined thresholds of the ratio of full capacity to design capacity.";
CM_ SG_ 2566848674 BMS2_SDB_Batt_PS8_discharge_prot "This parameter contains the current protection status of the battery.
Discharge protection triggered.";
CM_ SG_ 2566848674 BMS2_SDB_Batt_PS7_charge_prot "This parameter contains the current protection status of the battery.
Charge protection triggered.";
CM_ SG_ 2566848674 BMS2_SDB_Batt_PS6_mod_failed "This parameter contains the current protection status of the battery.
1 or more modules missing/failed.";
CM_ SG_ 2566848674 BMS2_SDB_Batt_PS5_over_temp "This parameter contains the current protection status of the battery.
Over-temperature detected.";
CM_ SG_ 2566848674 BMS2_SDB_Batt_PS4_under_voltage "This parameter contains the current protection status of the battery.
Under-voltage detected.";
CM_ SG_ 2566848674 BMS2_SDB_Batt_PS3_over_voltage "This parameter contains the current protection status of the battery.
Over-voltage detected.";
CM_ SG_ 2566848674 BMS2_SDB_Batt_PS2_overload "This parameter contains the current protection status of the battery.
Overload detected.";
CM_ SG_ 2566848674 BMS2_SDB_Batt_PS1_short_circuit "This parameter contains the current protection status of the battery.
Short circuit detected.";
CM_ SG_ 2566848674 BMS2_SDB_Batt_OS_8_sleep_mode "This parameter contains the status bits indicating the current state of the emergency load-dump, emergency override, heater and charger controls along with the master protection status bit.
Sleep mode pending (1 = sleep pending, 0 = awake)";
CM_ SG_ 2566848674 BMS2_SDB_Batt_OS_7_emerg_used "This parameter contains the status bits indicating the current state of the emergency load-dump, emergency override, heater and charger controls along with the master protection status bit.
Emergency override used (1= used, 0 = never used)";
CM_ SG_ 2566848674 BMS2_SDB_Batt_OS_6_emergency "This parameter contains the status bits indicating the current state of the emergency load-dump, emergency override, heater and charger controls along with the master protection status bit.
Emergency override (1 = active, 0 = inactive)";
CM_ SG_ 2566848674 BMS2_SDB_Batt_OS_45_charge_level "This parameter contains the status bits indicating the current state of the emergency load-dump, emergency override, heater and charger controls along with the master protection status bit.
Charge level (0 = off, 1 = 25%, 2 = 50%, 3 = full)";
CM_ SG_ 2566848674 BMS2_SDB_Batt_OS_3_charge_cont "This parameter contains the status bits indicating the current state of the emergency load-dump, emergency override, heater and charger controls along with the master protection status bit.
Charge control (1 = on, 0 = off)";
CM_ SG_ 2566848674 BMS2_SDB_Batt_OS_2_heater_cont "This parameter contains the status bits indicating the current state of the emergency load-dump, emergency override, heater and charger controls along with the master protection status bit.
Heater control (1 = on, 0 = off)";
CM_ SG_ 2566848674 BMS2_SDB_Batt_OS_1_master_prot "This parameter contains the status bits indicating the current state of the emergency load-dump, emergency override, heater and charger controls along with the master protection status bit.
Master protect (1 = protect, 0 = off)";
CM_ BO_ 2566804130 "This contains high resolution/range parameters reported from the alternator or power generation components.";
CM_ SG_ 2566804130 _nu_BMS2_SDB_AlternatorCurrent "SPN 1795 Alternator Current (High Range/Resolution)
This parameter indicates the amount of electrical current output from the alternator of the main vehicle. Alternator Current
(SPN 115) has a lower range and resolution.";
CM_ SG_ 2566804130 BMS2_SDB_NetBattery_Current "SPN 2579 Net Battery Current (High Range/Resolution)
Net flow of electrical current into/out-of the battery or batteries. This parameter is the high range and resolution of SPN
114 - Net Battery Current.";
CM_ BO_ 2566803618 "Contains battery temperature information.";
CM_ SG_ 2566803618 BMS2_SDB_Battery1_Temperature "Temperature of the battery 1. The relation to physical location is determined by the equipment manufacturer.";
CM_ SG_ 2566803618 _nu_BMS2_SDB_Battery2_Temp "Temperature of the battery 2. The relation to physical location is determined by the equipment manufacturer.";
CM_ BO_ 2566698658 "PGN containing vehicle electrical power information for the battery pack used for starting, lighting, and ignition.";
CM_ SG_ 2566698658 BMS2_SDB_SLI_BattPack_StOfCharge "5981
SLI Battery Pack State of Charge
Indicates the remaining charge of the battery pack used for starting the engine, for lighting, and for ignition (SLI). 0% means no charge remaining, 100% means full capacity at the battery pack's current state of health.   See SPN 5464 for hybrid battery pack.";
CM_ SG_ 2566698658 BMS2_SDB_SLI_BattPack_Capacity "5982
SLI Battery Pack Capacity
Original or rated total reserve capacity of the battery pack used for starting the engine, for lighting, and for ignition (SLI).";
CM_ SG_ 2566698658 BMS2_SDB_SLI_BattPack_Health "5983
SLI Battery Pack Health
Capacity of the battery pack relative to its original specification for the battery pack used for starting the engine, for lighting, and for ignition (SLI). 0% means battery pack is not capable of holding any charge, 100% means battery pack is capable of holding its original full capacity.";
CM_ BO_ 2566862242 "This PGN reports the total number of software-related events that have occurred during the life of the battery.";
CM_ SG_ 2566862242 BMS2_SDB_HardMCLRReset_events "This parameter contains a count of the number times the MCLR has reset the firmware due to a hardware reset pulse, this may be due to the external watchdog.
Data Range: 0 – 64255. A value of 64255 indicates 64255 events or more.";
CM_ SG_ 2566862242 BMS2_SDB_LowVoltageReset_events "TThis parameter contains a count of the number times the firmware has been reset due to the processor detecting a low supply voltage.
Data Range: 0 – 64255. A value of 64255 indicates 64255 events or more.";
CM_ SG_ 2566862242 BMS2_SDB_PORReset_events "This parameter contains a count of the number times the firmware has been started from a power up condition.
Data Range: 0 – 64255. A value of 64255 indicates 64255 events or more.";
CM_ SG_ 2566862242 BMS2_SDB_BrownOutReset_events "This parameter contains a count of the number times the firmware has been restarted due to a brown-out (below 2.7V).
Data Range: 0 – 64255. A value of 64255 indicates 64255 events or more.";
CM_ BO_ 2565799842 "Generic message for send the NAME
Used only for the BMS2";
CM_ SG_ 2565799842 BMS2_SDB_VehicleSystemInstance "Vehicle System Instance";
CM_ SG_ 2565799842 BMS2_SDB_IndustryGroup "Industry Group";
CM_ SG_ 2565799842 BMS2_SDB_Name_Reserved "Reserved";
CM_ SG_ 2565799842 BMS2_SDB_ECUInstance "ECU Instance";
CM_ SG_ 2565799842 BMS2_SDB_IdentityNumber_3 "Most significant 5 bits of Identity Number";
CM_ SG_ 2565799842 BMS2_SDB_ArbitraryAddressCapable "Arbitrary Address Capable";
CM_ SG_ 2565799842 BMS2_SDB_VehicleSystem "Vehicle System";
CM_ SG_ 2565799842 BMS2_SDB_Function "Function";
CM_ SG_ 2565799842 BMS2_SDB_FunctionInstance "Function Instance";
CM_ SG_ 2565799842 BMS2_SDB_ManufacturerCode_2 "Most significant 8 bits of Manufacturer Code";
CM_ SG_ 2565799842 BMS2_SDB_ManufacturerCode_1 "Least significant 3 bits of Manufacturer Code";
CM_ SG_ 2565799842 BMS2_SDB_IdentityNumber_2 "Second byte of Identity Number";
CM_ SG_ 2565799842 BMS2_SDB_IdentityNumber_1 "Least significant byte of Identity Number";
CM_ BO_ 2566850046 "This PGN reports a summary of the the operating parameters of the full battery: serial number, state of charge, state of health, temperature alarm, voltage alarm for the battery.";
CM_ SG_ 2566850046 BMS0_SDB_BatSumS_serial_number "This parameter contains the manufactured serial number of the battery. The lowest 21 bits of this 24 bit serial number are also used in the J1939 NAME – see 2.1.";
CM_ SG_ 2566850046 BMS0_SDB_BatSumS_Reserved_01 "Reserved";
CM_ SG_ 2566850046 BMS0_SDB_BatSumS_State_of_Charge "This parameter contains the ratio of the remaining capacity of the battery to the full capacity expressed as a percentage.";
CM_ SG_ 2566850046 BMS0_SDB_BatSumS_State_of_Health "This parameter contains a value relating to the state of health of the battery based on defined thresholds of the ratio of full capacity to design capacity.";
CM_ SG_ 2566850046 BMS0_SDB_BatSumS_Temp_Alarm "This parameter contains the temperature alarm, based on the maximum battery temperature.
0x00: No fault;
0x01: Low Temperature Alarm
0x02: High Temperature Alarm
0x03: Wrong Temperature Alarm";
CM_ SG_ 2566850046 BMS0_SDB_BatSumS_DischargeDis "This parameter indicates when the battery is not able to be discharged.
0x00: Discharge Enable;
0x01: Discharge Disable";
CM_ SG_ 2566850046 BMS0_SDB_BatSumS_ChargingDisable "This parameter indicates when the battery is not able to be discharged.
0x00: Charging Enable;
0x01: Charging Disable";
CM_ SG_ 2566850046 BMS0_SDB_BatSumS_HeaterEnabled "This parameter indicates when the heater is enabled.
0x00: Heater Disabled;
0x01: Heater Enabled";
CM_ SG_ 2566850046 BMS0_SDB_BatSumS_BypassEnabled "This parameter indicates when the bypass is enabled.
0x00: Bypass Disabled;
0x01: Bypass Enabled";
CM_ SG_ 2566850046 BMS0_SDB_BatSumS_Voltage_Alarm "This parameter indicates an over voltage condition in one or more modules.
0x00: No fault;
0x01:Over Voltage Alarm";
CM_ SG_ 2566850046 BMS0_SDB_BatSumS_Reserved_04 "Reserved";
CM_ SG_ 2566850046 BMS0_SDB_BatSumS_Reserved_05 "Reserved";
CM_ SG_ 2566850046 BMS0_SDB_BatSumS_Reserved_06 "Reserved";
CM_ SG_ 2566850046 BMS0_SDB_BatSumS_Reserved_07 "Reserved";
CM_ SG_ 2566850046 BMS0_SDB_BatSumS_Reserved_08 "Reserved";
CM_ SG_ 2566850046 BMS0_SDB_BatSumS_Reserved_09 "Reserved";
CM_ SG_ 2566850046 BMS0_SDB_BatSumS_Reserved_10 "Reserved";
CM_ SG_ 2566850046 BMS0_SDB_BatSumS_Reserved_11 "Reserved";
CM_ BO_ 2566849790 "Used for debugging purposes.";
CM_ SG_ 2566849790 BMS0_SDB_Debug_0 "Used for debugging purpose - byte 0";
CM_ SG_ 2566849790 BMS0_SDB_Debug_1 "Used for debugging purpose - byte 1";
CM_ SG_ 2566849790 BMS0_SDB_Debug_2 "Used for debugging purpose - byte 2";
CM_ SG_ 2566849790 BMS0_SDB_Debug_3 "Used for debugging purpose - byte 3";
CM_ SG_ 2566849790 BMS0_SDB_Debug_4 "Used for debugging purpose - byte 4";
CM_ SG_ 2566849790 BMS0_SDB_Debug_5 "Used for debugging purpose - byte 5";
CM_ SG_ 2566849790 BMS0_SDB_Debug_6 "Used for debugging purpose - byte 6";
CM_ SG_ 2566849790 BMS0_SDB_Debug_7 "Used for debugging purpose - byte 7";
CM_ BO_ 2566853374 "This PGN reports the remaining module capacity, the expected full module capacity and the designed module capacity for module 3.";
CM_ SG_ 2566853374 BMS0_SDB_M1_Remaining_capacity "This parameter contains the remaining capacity of the battery.";
CM_ SG_ 2566853374 BMS0_SDB_M1_Full_capacity "This parameter contains the full capacity of the battery.";
CM_ SG_ 2566853374 BMS0_SDB_M1_Design_capacity "This parameter contains the design capacity of the battery.";
CM_ SG_ 2566853374 BMS0_SDB_M1_Reserved_Cap "Reserved";
CM_ BO_ 2566853118 "This PGN reports the remaining module capacity, the expected full module capacity and the designed module capacity for module 2.";
CM_ SG_ 2566853118 BMS0_SDB_M2_Remaining_capacity "This parameter contains the remaining capacity of the battery.";
CM_ SG_ 2566853118 BMS0_SDB_M2_Full_capacity "This parameter contains the full capacity of the battery.";
CM_ SG_ 2566853118 BMS0_SDB_M2_Design_capacity "This parameter contains the design capacity of the battery.";
CM_ SG_ 2566853118 BMS0_SDB_M2_Reserved_Cap "Reserved";
CM_ BO_ 2566852862 "This PGN reports the remaining module capacity, the expected full module capacity and the designed module capacity for module 1.";
CM_ SG_ 2566852862 BMS0_SDB_M3_Remaining_capacity "This parameter contains the remaining capacity of the battery.";
CM_ SG_ 2566852862 BMS0_SDB_M3_Full_capacity "This parameter contains the full capacity of the battery.";
CM_ SG_ 2566852862 BMS0_SDB_M3_Design_capacity "This parameter contains the design capacity of the battery.";
CM_ SG_ 2566852862 BMS0_SDB_M3_Reserved_Cap "Reserved";
CM_ BO_ 2566862078 "This PGN reports the total number of software-related events that have occurred during the life of the battery.";
CM_ SG_ 2566862078 BMS0_SDB_WatchdogReset_events "This parameter contains a count of the number times the watchdog has reset the firmware due to an internal lock-up.
Data Range: 0 – 64255. A value of 64255 indicates 64255 events or more.";
CM_ SG_ 2566862078 BMS0_SDB_StackOverflowReset_even "This parameter contains a count of the number times the firmware has been reset due to a stack-overflow.
Data Range: 0 – 64255. A value of 64255 indicates 64255 events or more.";
CM_ SG_ 2566862078 BMS0_SDB_CommandedReset_events "This parameter contains a count of the number times the firmware has been reset by a CAN, USB or status button command.
Data Range: 0 – 64255. A value of 64255 indicates 64255 events or more.";
CM_ SG_ 2566862078 BMS0_SDB_IllegalInstructionReset "This parameter contains a count of the number times the firmware has been hard-reset using the status button.
Data Range: 0 – 64255. A value of 64255 indicates 64255 events or more.";
CM_ BO_ 2566861822 "This PGN reports the total number of voltage-related events that have occurred during the life of the battery.";
CM_ SG_ 2566861822 BMS0_SDB_OverVoltage_events "This parameter contains a count of the number of times an over-voltage event has occurred.";
CM_ SG_ 2566861822 BMS0_SDB_UnderVoltage_events "This parameter contains a count of the number of times an under-voltage event has occurred.";
CM_ BO_ 2566861566 "This PGN reports the total number of current and temperature-related events that have occurred during the life of the battery.";
CM_ SG_ 2566861566 BMS0_SDB_ShortCircuit_events "This parameter contains a count of the number of times the battery has been short-circuited.";
CM_ SG_ 2566861566 BMS0_SDB_CurrentOverload_events "This parameter contains a count of the number of times the battery has been overloaded.";
CM_ SG_ 2566861566 BMS0_SDB_OverCurrent_Charge_ev "This parameter contains a count of the number of times the battery’s maximum charge current has been exceeded.";
CM_ SG_ 2566861566 BMS0_SDB_OverTemperature_ev "This parameter contains a count of the number of times the battery’s maximum temperature has been exceeded.";
CM_ BO_ 2566861310 "This PGN reports on the maximum and minimum battery voltages and currents measured during the life of the battery.";
CM_ SG_ 2566861310 BMS0_SDB_MaximumVoltage "This parameter contains the maximum voltage ever measured across the battery cells.";
CM_ SG_ 2566861310 BMS0_SDB_MinimumVoltage "This parameter contains the minimum voltage ever measured across the battery cells.";
CM_ SG_ 2566861310 BMS0_SDB_MAX_Discharge_Current "This parameter contains the maximum discharge current ever measured on the battery.";
CM_ SG_ 2566861310 BMS0_SDB_MAX_Charge_Current "This parameter contains the maximum charge current ever measured on the battery.";
CM_ BO_ 2566861054 "This PGN reports on the maximum and minimum temperatures experienced during the life of the battery.";
CM_ SG_ 2566861054 BMS0_SDB_Maximum_Life_temp "This parameter contains the maximum temperature ever measured in the battery.";
CM_ SG_ 2566861054 BMS0_SDB_Minimum_Life_temp "This parameter contains the minimum temperature ever measured in the battery.";
CM_ SG_ 2566861054 BMS0_SDB_MAX_Charging_Temp "This parameter contains the maximum temperature ever measured while charging the battery.";
CM_ SG_ 2566861054 BMS0_SDB_MIN_Charging_Temp "This parameter contains the minimum temperature ever measured while charging the battery.";
CM_ BO_ 2566857470 "This PGN reports on the individual discharge switch temperatures within module 3 of the battery. The values are only valid when the discharge current exceeds 10A for the entire battery, at other times the values returned will be the J1939 unavailable value.";
CM_ SG_ 2566857470 BMS0_SDB_M3_Temperature_1 "This parameter contains the temperature of a discharge switch sensor.";
CM_ SG_ 2566857470 BMS0_SDB_M3_Temperature_2 "This parameter contains the temperature of a discharge switch sensor.";
CM_ SG_ 2566857470 BMS0_SDB_M3_Temperature_3 "This parameter contains the temperature of a discharge switch sensor.";
CM_ SG_ 2566857470 BMS0_SDB_M3_Reserved_Dis1 "Reserved";
CM_ SG_ 2566857470 BMS0_SDB_M3_Reserved_Dis2 "Reserved";
BA_DEF_ BO_  "GenMsgCycleTimeFast" INT 0 3600000;
BA_DEF_ BO_  "GenMsgDelayTime" INT 0 3600000;
BA_DEF_ BO_  "GenMsgStartDelayTime" INT 0 10000;
BA_DEF_ BO_  "GenMsgSendType" ENUM  "cyclic","reserved","cyclicIfActive","reserved","reserved","reserved","reserved","reserved","noMsgSendType";
BA_DEF_ BO_  "GenMsgCycleTime" INT 0 3600000;
BA_DEF_ BO_  "GenMsgILSupport" ENUM  "No","Yes";
BA_DEF_ BO_  "VFrameFormat" ENUM  "StandardCAN","ExtendedCAN","reserved","J1939PG";
BA_DEF_ BO_  "GenMsgSendTypex" ENUM  "cyclic","reserved","cyclicIfActive","reserved","reserved","reserved","reserved","reserved","noMsgSendType";
BA_DEF_ BO_  "GenMsgRequestable" INT 0 1;
BA_DEF_ BO_  "GenMsgSencmype" ENUM  "cyclic","reserved","cyclicIfActive","reserved","reserved","reserved","reserved","reserved","noMsgSencmype";
BA_DEF_ BO_  "GenMsgSencmypex" ENUM  "cyclic","reserved","cyclicIfActive","reserved","reserved","reserved","reserved","reserved","noMsgSencmype";
BA_DEF_ SG_  "GenSigSendType" ENUM  "Cyclic","OnWrite","reserved","OnChange","reserved","reserved","reserved","NoSigSendType";
BA_DEF_ SG_  "GenSigStartValue" INT 0 10000;
BA_DEF_ SG_  "GenSigEVName" STRING ;
BA_DEF_ SG_  "GenSigILSupport" ENUM  "Yes","No";
BA_DEF_ SG_  "GenSigSendTypex" ENUM  "Cyclic","OnWrite","reserved","OnChange","reserved","reserved","reserved","NoSigSendType";
BA_DEF_ SG_  "SigType" ENUM  "Default","Range","RangeSigned","ASCII","Discrete","Control","ReferencePGN","DTC","StringDelimiter","StringLength","StringLengthControl";
BA_DEF_ SG_  "GenSigSencmype" ENUM  "Cyclic","OnWrite","reserved","OnChange","reserved","reserved","reserved","NoSigSencmype";
BA_DEF_ SG_  "GenSigSencmypex" ENUM  "Cyclic","OnWrite","reserved","OnChange","reserved","reserved","reserved","NoSigSencmype";
BA_DEF_DEF_  "GenMsgCycleTimeFast" 0;
BA_DEF_DEF_  "GenMsgDelayTime" 0;
BA_DEF_DEF_  "GenMsgStartDelayTime" 0;
BA_DEF_DEF_  "GenMsgSendType" "noMsgSendType";
BA_DEF_DEF_  "GenMsgCycleTime" 0;
BA_DEF_DEF_  "GenMsgILSupport" "Yes";
BA_DEF_DEF_  "VFrameFormat" "J1939PG";
BA_DEF_DEF_  "GenMsgSendTypex" "noMsgSendType";
BA_DEF_DEF_  "GenMsgRequestable" 1;
BA_DEF_DEF_  "GenMsgSencmype" "noMsgSencmype";
BA_DEF_DEF_  "GenMsgSencmypex" "noMsgSencmype";
BA_DEF_DEF_  "GenSigSendType" "NoSigSendType";
BA_DEF_DEF_  "GenSigStartValue" 0;
BA_DEF_DEF_  "GenSigEVName" "Env@Nodename_@Signame";
BA_DEF_DEF_  "GenSigILSupport" "Yes";
BA_DEF_DEF_  "GenSigSendTypex" "NoSigSendType";
BA_DEF_DEF_  "SigType" "Default";
BA_DEF_DEF_  "GenSigSencmype" "NoSigSencmype";
BA_DEF_DEF_  "GenSigSencmypex" "NoSigSencmype";
BA_ "GenMsgCycleTime" BO_ 2558533943 100;
BA_ "GenMsgSendType" BO_ 2558533943 0;
BA_ "GenMsgSendTypex" BO_ 2559260449 0;
BA_ "GenMsgCycleTime" BO_ 2559260449 100;
BA_ "GenMsgSendType" BO_ 2559260449 0;
BA_ "GenMsgSendTypex" BO_ 2559325985 0;
BA_ "GenMsgCycleTime" BO_ 2559325985 100;
BA_ "GenMsgSendType" BO_ 2559325985 0;
BA_ "VFrameFormat" BO_ 2558590913 1;
BA_ "GenMsgCycleTime" BO_ 2558590913 1000;
BA_ "GenMsgSendType" BO_ 2558590913 0;
BA_ "VFrameFormat" BO_ 2558721985 1;
BA_ "GenMsgCycleTime" BO_ 2558721985 20000;
BA_ "GenMsgSendType" BO_ 2558721985 0;
BA_ "GenMsgCycleTime" BO_ 2566841884 100;
BA_ "GenSigStartValue" SG_ 2566841884 SDB_Local_hour_offset 125;
BA_ "GenSigStartValue" SG_ 2566841884 SDB_Local_minute_offset 125;
BA_ "GenSigStartValue" SG_ 2566841884 SDB_Month 1;
BA_ "GenSigStartValue" SG_ 2566853281 BMS1_SDB_M1_Reserved_Cap 255;
BA_ "GenSigStartValue" SG_ 2566853025 BMS1_SDB_M2_Reserved_Cap 255;
BA_ "GenSigStartValue" SG_ 2566852769 BMS1_SDB_M3_Reserved_Cap 255;
BA_ "GenSigStartValue" SG_ 2566860961 BMS1_SDB_Maximum_Life_temp 1000;
BA_ "GenSigStartValue" SG_ 2566860961 BMS1_SDB_Minimum_Life_temp 1000;
BA_ "GenSigStartValue" SG_ 2566860961 BMS1_SDB_MAX_Charging_Temp 1000;
BA_ "GenSigStartValue" SG_ 2566860961 BMS1_SDB_MIN_Charging_Temp 1000;
BA_ "GenSigStartValue" SG_ 2566857377 BMS1_SDB_M3_Temperature_1 60;
BA_ "GenSigStartValue" SG_ 2566857377 BMS1_SDB_M3_Temperature_2 60;
BA_ "GenSigStartValue" SG_ 2566857377 BMS1_SDB_M3_Temperature_3 60;
BA_ "GenSigStartValue" SG_ 2566857377 BMS1_SDB_M3_Reserved_Dis1 255;
BA_ "GenSigStartValue" SG_ 2566857377 BMS1_SDB_M3_Reserved_Dis2 255;
BA_ "GenSigStartValue" SG_ 2566857121 BMS1_SDB_M2_Temperature_1 60;
BA_ "GenSigStartValue" SG_ 2566857121 BMS1_SDB_M2_Temperature_2 60;
BA_ "GenSigStartValue" SG_ 2566857121 BMS1_SDB_M2_Temperature_3 60;
BA_ "GenSigStartValue" SG_ 2566857121 BMS1_SDB_M2_Reserved_Dis1 255;
BA_ "GenSigStartValue" SG_ 2566857121 BMS1_SDB_M2_Reserved_Dis2 255;
BA_ "GenSigStartValue" SG_ 2566856865 BMS1_SDB_M1_Temperature_1 60;
BA_ "GenSigStartValue" SG_ 2566856865 BMS1_SDB_M1_Temperature_2 60;
BA_ "GenSigStartValue" SG_ 2566856865 BMS1_SDB_M1_Temperature_3 60;
BA_ "GenSigStartValue" SG_ 2566856865 BMS1_SDB_M1_Reserved_Dis1 255;
BA_ "GenSigStartValue" SG_ 2566856865 BMS1_SDB_M1_Reserved_Dis2 255;
BA_ "GenSigStartValue" SG_ 2566855329 BMS1_SDB_M3_FuelGauge1_Temp 1000;
BA_ "GenSigStartValue" SG_ 2566855329 BMS1_SDB_M3_Thermistor1_temp 1000;
BA_ "GenSigStartValue" SG_ 2566855329 BMS1_SDB_M3_Thermistor2_temp 1000;
BA_ "GenSigStartValue" SG_ 2566855329 BMS1_SDB_M3_FuelGauge2_Temp 1000;
BA_ "GenSigStartValue" SG_ 2566855073 BMS1_SDB_M2_FuelGauge1_Temp 1000;
BA_ "GenSigStartValue" SG_ 2566855073 BMS1_SDB_M2_Thermistor1_temp 1000;
BA_ "GenSigStartValue" SG_ 2566855073 BMS1_SDB_M2_Thermistor2_temp 1000;
BA_ "GenSigStartValue" SG_ 2566855073 BMS1_SDB_M2_FuelGauge2_Temp 1000;
BA_ "GenSigStartValue" SG_ 2566854817 BMS1_SDB_M1_FuelGauge1_Temp 1000;
BA_ "GenSigStartValue" SG_ 2566854817 BMS1_SDB_M1_Thermistor1_temp 1000;
BA_ "GenSigStartValue" SG_ 2566854817 BMS1_SDB_M1_Thermistor2_temp 1000;
BA_ "GenSigStartValue" SG_ 2566854817 BMS1_SDB_M1_FuelGauge2_Temp 1000;
BA_ "GenSigStartValue" SG_ 2566849185 BMS1_SDB_Maximum_Temperature 1000;
BA_ "GenSigStartValue" SG_ 2566849185 BMS1_SDB_Minimum_Temperature 1000;
BA_ "GenSigStartValue" SG_ 2566849185 BMS1_SDB_Average_Temperature 1000;
BA_ "GenSigStartValue" SG_ 2566848673 BMS1_SDB_Batt_Average_Current 55;
BA_ "GenSigStartValue" SG_ 2566803617 BMS1_SDB_Battery1_Temperature 40;
BA_ "GenSigStartValue" SG_ 2566803617 _nu_BMS1_SDB_Battery2_Temp 40;
BA_ "GenSigStartValue" SG_ 2566853282 BMS2_SDB_M1_Reserved_Cap 255;
BA_ "GenSigStartValue" SG_ 2566853026 BMS2_SDB_M2_Reserved_Cap 255;
BA_ "GenSigStartValue" SG_ 2566852770 BMS2_SDB_M3_Reserved_Cap 255;
BA_ "GenSigStartValue" SG_ 2566860962 BMS2_SDB_Maximum_Life_temp 1000;
BA_ "GenSigStartValue" SG_ 2566860962 BMS2_SDB_Minimum_Life_temp 1000;
BA_ "GenSigStartValue" SG_ 2566860962 BMS2_SDB_MAX_Charging_Temp 1000;
BA_ "GenSigStartValue" SG_ 2566860962 BMS2_SDB_MIN_Charging_Temp 1000;
BA_ "GenSigStartValue" SG_ 2566857378 BMS2_SDB_M3_Temperature_1 60;
BA_ "GenSigStartValue" SG_ 2566857378 BMS2_SDB_M3_Temperature_2 60;
BA_ "GenSigStartValue" SG_ 2566857378 BMS2_SDB_M3_Temperature_3 60;
BA_ "GenSigStartValue" SG_ 2566857378 BMS2_SDB_M3_Reserved_Dis1 255;
BA_ "GenSigStartValue" SG_ 2566857378 BMS2_SDB_M3_Reserved_Dis2 255;
BA_ "GenSigStartValue" SG_ 2566857122 BMS2_SDB_M2_Temperature_1 60;
BA_ "GenSigStartValue" SG_ 2566857122 BMS2_SDB_M2_Temperature_2 60;
BA_ "GenSigStartValue" SG_ 2566857122 BMS2_SDB_M2_Temperature_3 60;
BA_ "GenSigStartValue" SG_ 2566857122 BMS2_SDB_M2_Reserved_Dis1 255;
BA_ "GenSigStartValue" SG_ 2566857122 BMS2_SDB_M2_Reserved_Dis2 255;
BA_ "GenSigStartValue" SG_ 2566856866 BMS2_SDB_M1_Temperature_1 60;
BA_ "GenSigStartValue" SG_ 2566856866 BMS2_SDB_M1_Temperature_2 60;
BA_ "GenSigStartValue" SG_ 2566856866 BMS2_SDB_M1_Temperature_3 60;
BA_ "GenSigStartValue" SG_ 2566856866 BMS2_SDB_M1_Reserved_Dis1 255;
BA_ "GenSigStartValue" SG_ 2566856866 BMS2_SDB_M1_Reserved_Dis2 255;
BA_ "GenSigStartValue" SG_ 2566855330 BMS2_SDB_M3_FuelGauge1_Temp 1000;
BA_ "GenSigStartValue" SG_ 2566855330 BMS2_SDB_M3_Thermistor1_temp 1000;
BA_ "GenSigStartValue" SG_ 2566855330 BMS2_SDB_M3_Thermistor2_temp 1000;
BA_ "GenSigStartValue" SG_ 2566855330 BMS2_SDB_M3_FuelGauge2_Temp 1000;
BA_ "GenSigStartValue" SG_ 2566855074 BMS2_SDB_M2_FuelGauge1_Temp 1000;
BA_ "GenSigStartValue" SG_ 2566855074 BMS2_SDB_M2_Thermistor1_temp 1000;
BA_ "GenSigStartValue" SG_ 2566855074 BMS2_SDB_M2_Thermistor2_temp 1000;
BA_ "GenSigStartValue" SG_ 2566855074 BMS2_SDB_M2_FuelGauge2_Temp 1000;
BA_ "GenSigStartValue" SG_ 2566854818 BMS2_SDB_M1_FuelGauge1_Temp 1000;
BA_ "GenSigStartValue" SG_ 2566854818 BMS2_SDB_M1_Thermistor1_temp 1000;
BA_ "GenSigStartValue" SG_ 2566854818 BMS2_SDB_M1_Thermistor2_temp 1000;
BA_ "GenSigStartValue" SG_ 2566854818 BMS2_SDB_M1_FuelGauge2_Temp 1000;
BA_ "GenSigStartValue" SG_ 2566849186 BMS2_SDB_Maximum_Temperature 1000;
BA_ "GenSigStartValue" SG_ 2566849186 BMS2_SDB_Minimum_Temperature 1000;
BA_ "GenSigStartValue" SG_ 2566849186 BMS2_SDB_Average_Temperature 1000;
BA_ "GenSigStartValue" SG_ 2566848674 BMS2_SDB_Batt_Average_Current 55;
BA_ "GenSigStartValue" SG_ 2566803618 BMS2_SDB_Battery1_Temperature 40;
BA_ "GenSigStartValue" SG_ 2566803618 _nu_BMS2_SDB_Battery2_Temp 40;
BA_ "GenSigStartValue" SG_ 2566853374 BMS0_SDB_M1_Reserved_Cap 255;
BA_ "GenSigStartValue" SG_ 2566853118 BMS0_SDB_M2_Reserved_Cap 255;
BA_ "GenSigStartValue" SG_ 2566852862 BMS0_SDB_M3_Reserved_Cap 255;
BA_ "GenSigStartValue" SG_ 2566861054 BMS0_SDB_Maximum_Life_temp 1000;
BA_ "GenSigStartValue" SG_ 2566861054 BMS0_SDB_Minimum_Life_temp 1000;
BA_ "GenSigStartValue" SG_ 2566861054 BMS0_SDB_MAX_Charging_Temp 1000;
BA_ "GenSigStartValue" SG_ 2566861054 BMS0_SDB_MIN_Charging_Temp 1000;
BA_ "GenSigStartValue" SG_ 2566857470 BMS0_SDB_M3_Temperature_1 60;
BA_ "GenSigStartValue" SG_ 2566857470 BMS0_SDB_M3_Temperature_2 60;
BA_ "GenSigStartValue" SG_ 2566857470 BMS0_SDB_M3_Temperature_3 60;
BA_ "GenSigStartValue" SG_ 2566857470 BMS0_SDB_M3_Reserved_Dis1 255;
BA_ "GenSigStartValue" SG_ 2566857470 BMS0_SDB_M3_Reserved_Dis2 255;
VAL_ 2558533943 Btn_FuelPumpCP10 1 "PRESSED" 0 "RELEASED" ;
VAL_ 2558533943 Btn_EngineHeater_CP10 1 "PRESSED" 0 "RELEASED" ;
VAL_ 2558533943 Btn_ParkingBrake_CP10 1 "PRESSED" 0 "RELEASED" ;
VAL_ 2558533943 Btn_Dust_Fan_CP10 1 "PRESSED" 0 "RELEASED" ;
VAL_ 2558533943 Btn_Warlight_B2_CP10 1 "PRESSED" 0 "RELEASED" ;
VAL_ 2558533943 Btn_Warlight_B1_CP10 1 "PRESSED" 0 "RELEASED" ;
VAL_ 2558533943 Btn_TripReset_CP10 1 "PRESSED" 0 "RELEASED" ;
VAL_ 2558533943 Btn_Retarder_Up_CP10 1 "PRESSED" 0 "RELEASED" ;
VAL_ 2558533943 Btn_Retarder_Off_CP10 1 "PRESSED" 0 "RELEASED" ;
VAL_ 2558533943 Btn_Retarder_Down_CP10 1 "PRESSED" 0 "RELEASED" ;
VAL_ 2558533943 Btn_Marker_Light_CP10 1 "PRESSED" 0 "RELEASED" ;
VAL_ 2558533943 Btn_Low_Beam_Light_CP10 1 "PRESSED" 0 "RELEASED" ;
VAL_ 2558533943 Btn_Lock_Front_Diff_CP10 1 "PRESSED" 0 "RELEASED" ;
VAL_ 2558533943 Btn_Ford_Mode_CP10 1 "PRESSED" 0 "RELEASED" ;
VAL_ 2558533943 Btn_Emergency_Blinker_CP10 1 "PRESSED" 0 "RELEASED" ;
VAL_ 2558533943 Btn_CTIS_Track_CP10 1 "PRESSED" 0 "RELEASED" ;
VAL_ 2558533943 Btn_CTIS_Sand_CP10 1 "PRESSED" 0 "RELEASED" ;
VAL_ 2558533943 Btn_CTIS_Road_CP10 1 "PRESSED" 0 "RELEASED" ;
VAL_ 2558533943 Btn_CTIS_ON_CP10 1 "PRESSED" 0 "RELEASED" ;
VAL_ 2558533943 Btn_CTIS_Load_CP10 1 "PRESSED" 0 "RELEASED" ;
VAL_ 2558533943 Btn_CTIS_Emergency_CP10 1 "PRESSED" 0 "RELEASED" ;
VAL_ 2558533943 Btn_CTIS_Check_CP10 1 "PRESSED" 0 "RELEASED" ;
VAL_ 2558533943 Btn_Bilge_Pump_EngineBay_CP10 1 "PRESSED" 0 "RELEASED" ;
VAL_ 2558533943 Btn_All_Wheel_Drive_CP10 1 "PRESSED" 0 "RELEASED" ;
VAL_ 2558533943 Btn_4th_Steering_Axle_CP10 1 "PRESSED" 0 "RELEASED" ;
VAL_ 2558533943 _nu_Btn_2_01_CP10 1 "PRESSED" 0 "RELEASED" ;
VAL_ 2558533943 _nu_Btn_2_04_CP10 1 "PRESSED" 0 "RELEASED" ;
VAL_ 2558533943 _nu_Btn_2_07_CP10 1 "PRESSED" 0 "RELEASED" ;
VAL_ 2558533943 Btn_Change_h_km_CP10 1 "PRESSED" 0 "RELEASED" ;
VAL_ 2558533943 _nu_Btn_2_15_CP10 1 "PRESSED" 0 "RELEASED" ;
VAL_ 2558533943 _nu_Btn_2_16_CP10 1 "PRESSED" 0 "RELEASED" ;
VAL_ 2558533943 _nu_Btn_2_17_CP10 1 "PRESSED" 0 "RELEASED" ;
VAL_ 2558533943 _nu_Btn_2_18_CP10 1 "PRESSED" 0 "RELEASED" ;
VAL_ 2558533943 _nu_Btn_2_19_CP10 1 "PRESSED" 0 "RELEASED" ;
VAL_ 2558533943 _nu_Btn_2_20_CP10 1 "PRESSED" 0 "RELEASED" ;
VAL_ 2558533943 _nu_Btn_2_21_CP10 1 "PRESSED" 0 "RELEASED" ;
VAL_ 2558533943 _nu_Btn_2_22_CP10 1 "PRESSED" 0 "RELEASED" ;
VAL_ 2558533943 _nu_Btn_2_23_CP10 1 "PRESSED" 0 "RELEASED" ;
VAL_ 2558533943 _nu_Btn_2_27_CP10 1 "PRESSED" 0 "RELEASED" ;
VAL_ 2558533943 _nu_Btn_2_28_CP10 1 "PRESSED" 0 "RELEASED" ;
VAL_ 2558533943 _nu_Btn_2_29_CP10 1 "PRESSED" 0 "RELEASED" ;
VAL_ 2558533943 _nu_Btn_2_30_CP10 1 "PRESSED" 0 "RELEASED" ;
VAL_ 2558533943 _nu_Btn_2_31_CP10 1 "PRESSED" 0 "RELEASED" ;
VAL_ 2558533943 _nu_Btn_2_35_CP10 1 "PRESSED" 0 "RELEASED" ;
VAL_ 2558533943 _nu_Btn_2_36_CP10 1 "PRESSED" 0 "RELEASED" ;
VAL_ 2558533943 _nu_Btn_2_37_CP10 1 "PRESSED" 0 "RELEASED" ;
VAL_ 2558533943 _nu_Btn_2_39_CP10 1 "PRESSED" 0 "RELEASED" ;
VAL_ 2558533943 _nu_Btn_2_47_CP10 1 "PRESSED" 0 "RELEASED" ;
VAL_ 2558533943 _nu_Btn_2_48_CP10 1 "PRESSED" 0 "RELEASED" ;
VAL_ 2558533943 _nu_Btn_2_49_CP10 1 "PRESSED" 0 "RELEASED" ;
VAL_ 2558533943 _nu_Btn_2_50_CP10 1 "PRESSED" 0 "RELEASED" ;
VAL_ 2558533943 _nu_Btn_2_51_CP10 1 "PRESSED" 0 "RELEASED" ;
VAL_ 2558533943 _nu_Btn_2_52_CP10 1 "PRESSED" 0 "RELEASED" ;
VAL_ 2558533943 _nu_Btn_2_53_CP10 1 "PRESSED" 0 "RELEASED" ;
VAL_ 2558533943 _nu_Btn_2_54_CP10 1 "PRESSED" 0 "RELEASED" ;
VAL_ 2558533943 _nu_Btn_2_55_CP10 1 "PRESSED" 0 "RELEASED" ;
VAL_ 2558533943 _nu_Btn_2_56_CP10 1 "PRESSED" 0 "RELEASED" ;
VAL_ 2558533943 _nu_Btn_2_57_CP10 1 "PRESSED" 0 "RELEASED" ;
VAL_ 2558533943 _nu_Btn_2_58_CP10 1 "PRESSED" 0 "RELEASED" ;
VAL_ 2558533943 _nu_Btn_2_59_CP10 1 "PRESSED" 0 "RELEASED" ;
VAL_ 2558533943 _nu_Btn_2_60_CP10 1 "PRESSED" 0 "RELEASED" ;
VAL_ 2558533943 _nu_Btn_2_61_CP10 1 "PRESSED" 0 "RELEASED" ;
VAL_ 2558533943 _nu_Btn_2_62_CP10 1 "PRESSED" 0 "RELEASED" ;
VAL_ 2558533943 _nu_Btn_2_63_CP10 1 "PRESSED" 0 "RELEASED" ;
VAL_ 2559260449 ALS_Configuration 3 "BOTH_NOT_PRESENT" 2 "SX_NOT_PRESENT" 1 "DX_NOT_PRESENT" 0 "BOTH_PRESENT" ;
VAL_ 2559260449 ALS_DX_Status 0 "ALS_OK" 1 "ALS_NOT_PRESENT" 2 "ALS_NOT_INSTALLED" 3 "INFO_NOT_AVAILABLE" ;
VAL_ 2559260449 ALS_SX_Status 0 "ALS_OK" 1 "ALS_NOT_PRESENT" 2 "ALS_NOT_INSTALLED" 3 "INFO_NOT_AVAILABLE" ;
VAL_ 2559325985 TLC_07_Status 3 "NOT_USED" 2 "NOT_USED" 1 "KO_RED" 0 "OK_GREEN" ;
VAL_ 2559325985 TLC_06_Status 3 "NOT_USED" 2 "NOT_USED" 1 "KO_RED" 0 "OK_GREEN" ;
VAL_ 2559325985 TLC_05_Status 3 "NOT_USED" 2 "NOT_USED" 1 "KO_RED" 0 "OK_GREEN" ;
VAL_ 2559325985 TLC_04_Status 3 "NOT_USED" 2 "NOT_USED" 1 "KO_RED" 0 "OK_GREEN" ;
VAL_ 2559325985 TLC_03_Status 3 "NOT_USED" 2 "NOT_USED" 1 "KO_RED" 0 "OK_GREEN" ;
VAL_ 2559325985 TLC_02_Status 3 "NOT_USED" 2 "NOT_USED" 1 "KO_RED" 0 "OK_GREEN" ;
VAL_ 2559325985 TLC_01_Status 3 "NOT_USED" 2 "NOT_USED" 1 "KO_RED" 0 "OK_GREEN" ;
VAL_ 2559325985 TLC_07_Monitor 3 "NO_MONITOR" 2 "RIGHT" 1 "CENTRAL" 0 "LEFT" ;
VAL_ 2559325985 TLC_06_Monitor 3 "NO_MONITOR" 2 "RIGHT" 1 "CENTRAL" 0 "LEFT" ;
VAL_ 2559325985 TLC_05_Monitor 3 "NO_MONITOR" 2 "RIGHT" 1 "CENTRAL" 0 "LEFT" ;
VAL_ 2559325985 TLC_04_Monitor 3 "NO_MONITOR" 2 "RIGHT" 1 "CENTRAL" 0 "LEFT" ;
VAL_ 2559325985 TLC_03_Monitor 3 "NO_MONITOR" 2 "RIGHT" 1 "CENTRAL" 0 "LEFT" ;
VAL_ 2559325985 TLC_02_Monitor 3 "NO_MONITOR" 2 "RIGHT" 1 "CENTRAL" 0 "LEFT" ;
VAL_ 2559325985 TLC_01_Monitor 3 "NO_MONITOR" 2 "RIGHT" 1 "CENTRAL" 0 "LEFT" ;
VAL_ 2559325985 TLC_00_Monitor 3 "NO_MONITOR" 2 "RIGHT" 1 "CENTRAL" 0 "LEFT" ;
VAL_ 2559325985 TLC_00_Status 3 "NOT_USED" 2 "NOT_USED" 1 "KO_RED" 0 "OK_GREEN" ;
VAL_ 2558590913 C_Sensor_Status 15 "NotAvailable" 14 "NotUsed" 13 "NotUsed" 12 "NotUsed" 11 "NotUsed" 10 "NotUsed" 9 "NotUsed" 8 "NotUsed" 7 "MeasuringSiglePolaritiyNegative" 6 "MeasuringSiglePolaritiyPositive" 5 "Device-Error" 4 "Analytic-Test" 3 "Self-Test" 2 "Warm-up" 1 "Working" 0 "StandBy" ;
VAL_ 2558590913 Class5_Type 15 "NotAvailable" 14 "NotUsed" 13 "NotUsed" 12 "NotUsed" 11 "NotUsed" 10 "NotUsed" 9 "NotUsed" 8 "NotUsed" 7 "NotUsed" 6 "NotUsed" 5 "NotUsed" 4 "ToxicIndustrialChemical" 3 "BloodAgent" 2 "BlisterAgent" 1 "NerveAgent" 0 "NoAgent" ;
VAL_ 2558590913 Class4_Type 15 "NotAvailable" 14 "NotUsed" 13 "NotUsed" 12 "NotUsed" 11 "NotUsed" 10 "NotUsed" 9 "NotUsed" 8 "NotUsed" 7 "NotUsed" 6 "NotUsed" 5 "NotUsed" 4 "ToxicIndustrialChemical" 3 "BloodAgent" 2 "BlisterAgent" 1 "NerveAgent" 0 "NoAgent" ;
VAL_ 2558590913 Class3_Type 15 "NotAvailable" 14 "NotUsed" 13 "NotUsed" 12 "NotUsed" 11 "NotUsed" 10 "NotUsed" 9 "NotUsed" 8 "NotUsed" 7 "NotUsed" 6 "NotUsed" 5 "NotUsed" 4 "ToxicIndustrialChemical" 3 "BloodAgent" 2 "BlisterAgent" 1 "NerveAgent" 0 "NoAgent" ;
VAL_ 2558590913 Class2_Type 15 "NotAvailable" 14 "NotUsed" 13 "NotUsed" 12 "NotUsed" 11 "NotUsed" 10 "NotUsed" 9 "NotUsed" 8 "NotUsed" 7 "NotUsed" 6 "NotUsed" 5 "NotUsed" 4 "ToxicIndustrialChemical" 3 "BloodAgent" 2 "BlisterAgent" 1 "NerveAgent" 0 "NoAgent" ;
VAL_ 2558590913 Class1_Type 15 "NotAvailable" 14 "NotUsed" 13 "NotUsed" 12 "NotUsed" 11 "NotUsed" 10 "NotUsed" 9 "NotUsed" 8 "NotUsed" 7 "NotUsed" 6 "NotUsed" 5 "NotUsed" 4 "ToxicIndustrialChemical" 3 "BloodAgent" 2 "BlisterAgent" 1 "NerveAgent" 0 "NoAgent" ;
VAL_ 2558590913 C_Alarm_Status 15 "NotAvailable" 14 "NotUsed" 13 "NotUsed" 12 "NotUsed" 11 "NotUsed" 10 "NotUsed" 9 "NotUsed" 8 "NotUsed" 7 "NotUsed" 6 "NotUsed" 5 "NotUsed" 4 "NotUsed" 3 "NotUsed" 2 "NotUsed" 1 "AllarmeAttivo" 0 "AllarmeDisattivo" ;
VAL_ 2558590913 N_Sensor_Alarm 1 "Alarm ON" 0 "Alarm OFF" ;
VAL_ 2558590913 N_DoseRateAlarm 1 "Alarm ON" 0 "Alarm OFF" ;
VAL_ 2558590913 N_DoseAlarm 1 "Alarm ON" 0 "Alarm OFF" ;
VAL_ 2558590913 N_Current_Unit 1 "Alarm ON" 0 "Alarm OFF" ;
VAL_ 2558590913 N_GPS_detected 1 "Alarm ON" 0 "Alarm OFF" ;
VAL_ 2558590913 Reserved_01 0 "Alarm OFF" ;
VAL_ 2558590913 Reserved_02 0 "Alarm OFF" ;
VAL_ 2558590913 Reserved_03 0 "Alarm OFF" ;
VAL_ 2558590913 N_Sensor_Error 1 "Alarm ON" 0 "Alarm OFF" ;
VAL_ 2558590913 N_GDR_Module_Error 1 "Alarm ON" 0 "Alarm OFF" ;
VAL_ 2558590913 N_Voltage_Module_Error 1 "Alarm ON" 0 "Alarm OFF" ;
VAL_ 2558590913 Reserved_04 0 "Alarm OFF" ;
VAL_ 2558590913 Reserved_05 0 "Alarm OFF" ;
VAL_ 2558590913 Reserved_06 0 "Alarm OFF" ;
VAL_ 2558590913 Reserved_07 0 "Alarm OFF" ;
VAL_ 2558590913 Reserved_08 0 "Alarm OFF" ;
VAL_ 2566849953 BMS1_SDB_BatSumS_State_of_Health 3 "Health_is_wrong" 2 "Health_is_good" 1 "Health_is_medium" 0 "Health_is_poor" ;
VAL_ 2566849953 BMS1_SDB_BatSumS_Temp_Alarm 3 "Wrong_Temperature_Alarm" 2 "High_Temperature_Alarm" 1 "Low_Temperature_Alarm" 0 "No_fault" ;
VAL_ 2566849953 BMS1_SDB_BatSumS_DischargeDis 1 "Discharge_Disable" 0 "Discharge_Enable" ;
VAL_ 2566849953 BMS1_SDB_BatSumS_ChargingDisable 1 "Charging_Disable" 0 "Charging_Enable" ;
VAL_ 2566849953 BMS1_SDB_BatSumS_HeaterEnabled 1 "Heater_Enabled" 0 "Heater_Disabled" ;
VAL_ 2566849953 BMS1_SDB_BatSumS_BypassEnabled 1 "Bypass_Enabled" 0 "Bypass_Disabled" ;
VAL_ 2566849953 BMS1_SDB_BatSumS_Voltage_Alarm 1 "Active" 0 "NotActive" ;
VAL_ 2566851233 BMS1_SDB_M3_Module_StateOfHealth 3 "Health_is_wrong" 2 "Health_is_good" 1 "Health_is_medium" 0 "Health_is_poor" ;
VAL_ 2566851233 BMS1_SDB_M3_DiscProtectTrigg 1 "Fault_Present" 0 "No_Fault" ;
VAL_ 2566851233 BMS1_SDB_M3_ChargeProtectTrigg 1 "Fault_Present" 0 "No_Fault" ;
VAL_ 2566851233 BMS1_SDB_M3_ModulesMissingFailed 1 "Fault_Present" 0 "No_Fault" ;
VAL_ 2566851233 BMS1_SDB_M3_OverTemp_detect 1 "Fault_Present" 0 "No_Fault" ;
VAL_ 2566851233 BMS1_SDB_M3_UnderVoltage_detect 1 "Fault_Present" 0 "No_Fault" ;
VAL_ 2566851233 BMS1_SDB_M3_OverVoltage_detected 1 "Fault_Present" 0 "No_Fault" ;
VAL_ 2566851233 BMS1_SDB_M3_Overload_detected 1 "Fault_Present" 0 "No_Fault" ;
VAL_ 2566851233 BMS1_SDB_M3_ShortCircuit_detect 1 "Fault_Present" 0 "No_Fault" ;
VAL_ 2566850977 BMS1_SDB_M2_Module_StateOfHealth 3 "Health_is_wrong" 2 "Health_is_good" 1 "Health_is_medium" 0 "Health_is_poor" ;
VAL_ 2566850977 BMS1_SDB_M2_DiscProtectTrigg 1 "Fault_Present" 0 "No_Fault" ;
VAL_ 2566850977 BMS1_SDB_M2_ChargeProtectTrigg 1 "Fault_Present" 0 "No_Fault" ;
VAL_ 2566850977 BMS1_SDB_M2_ModulesMissingFailed 1 "Fault_Present" 0 "No_Fault" ;
VAL_ 2566850977 BMS1_SDB_M2_OverTemp_detect 1 "Fault_Present" 0 "No_Fault" ;
VAL_ 2566850977 BMS1_SDB_M2_UnderVoltage_detect 1 "Fault_Present" 0 "No_Fault" ;
VAL_ 2566850977 BMS1_SDB_M2_OverVoltage_detected 1 "Fault_Present" 0 "No_Fault" ;
VAL_ 2566850977 BMS1_SDB_M2_Overload_detected 1 "Fault_Present" 0 "No_Fault" ;
VAL_ 2566850977 BMS1_SDB_M2_ShortCircuit_detect 1 "Fault_Present" 0 "No_Fault" ;
VAL_ 2566850721 BMS1_SDB_M1_Module_StateOfHealth 3 "Health_is_wrong" 2 "Health_is_good" 1 "Health_is_medium" 0 "Health_is_poor" ;
VAL_ 2566850721 BMS1_SDB_M1_DiscProtectTrigg 1 "Fault_Present" 0 "No_Fault" ;
VAL_ 2566850721 BMS1_SDB_M1_ChargeProtectTrigg 1 "Fault_Present" 0 "No_Fault" ;
VAL_ 2566850721 BMS1_SDB_M1_ModulesMissingFailed 1 "Fault_Present" 0 "No_Fault" ;
VAL_ 2566850721 BMS1_SDB_M1_OverTemp_detect 1 "Fault_Present" 0 "No_Fault" ;
VAL_ 2566850721 BMS1_SDB_M1_UnderVoltage_detect 1 "Fault_Present" 0 "No_Fault" ;
VAL_ 2566850721 BMS1_SDB_M1_OverVoltage_detected 1 "Fault_Present" 0 "No_Fault" ;
VAL_ 2566850721 BMS1_SDB_M1_Overload_detected 1 "Fault_Present" 0 "No_Fault" ;
VAL_ 2566850721 BMS1_SDB_M1_ShortCircuit_detect 1 "Fault_Present" 0 "No_Fault" ;
VAL_ 2566848929 BMS1_SDB_Overall_10_alarm 1 "Alarm_ON" 0 "Alarm_OFF" ;
VAL_ 2566848929 BMS1_SDB_Silent_Watch_20_alarm 1 "Alarm_ON" 0 "Alarm_OFF" ;
VAL_ 2566848929 BMS1_SDB_EngStartCapacity_alarm 1 "Alarm_ON" 0 "Alarm_OFF" ;
VAL_ 2566848673 BMS1_SDB_Batt_StsOfHealth 3 "Health_is_wrong" 2 "Health_is_good" 1 "Health_is_medium" 0 "Health_is_poor" ;
VAL_ 2566848673 BMS1_SDB_Batt_PS8_discharge_prot 1 "Fault_Present" 0 "No_Fault" ;
VAL_ 2566848673 BMS1_SDB_Batt_PS7_charge_prot 1 "Fault_Present" 0 "No_Fault" ;
VAL_ 2566848673 BMS1_SDB_Batt_PS6_mod_failed 1 "Fault_Present" 0 "No_Fault" ;
VAL_ 2566848673 BMS1_SDB_Batt_PS5_over_temp 1 "Fault_Present" 0 "No_Fault" ;
VAL_ 2566848673 BMS1_SDB_Batt_PS4_under_voltage 1 "Fault_Present" 0 "No_Fault" ;
VAL_ 2566848673 BMS1_SDB_Batt_PS3_over_voltage 1 "Fault_Present" 0 "No_Fault" ;
VAL_ 2566848673 BMS1_SDB_Batt_PS2_overload 1 "Fault_Present" 0 "No_Fault" ;
VAL_ 2566848673 BMS1_SDB_Batt_PS1_short_circuit 1 "Fault_Present" 0 "No_Fault" ;
VAL_ 2566848673 BMS1_SDB_Batt_OS_8_sleep_mode 1 "Sleep_pending" 0 "Awake" ;
VAL_ 2566848673 BMS1_SDB_Batt_OS_7_emerg_used 1 "used" 0 "never_used" ;
VAL_ 2566848673 BMS1_SDB_Batt_OS_6_emergency 1 "Active" 0 "NotActive" ;
VAL_ 2566848673 BMS1_SDB_Batt_OS_45_charge_level 3 "100%" 2 "50%" 1 "25%" 0 "OFF" ;
VAL_ 2566848673 BMS1_SDB_Batt_OS_3_charge_cont 1 "ON" 0 "OFF" ;
VAL_ 2566848673 BMS1_SDB_Batt_OS_2_heater_cont 1 "ON" 0 "OFF" ;
VAL_ 2566848673 BMS1_SDB_Batt_OS_1_master_prot 1 "Protect" 0 "OFF" ;
VAL_ 2566849954 BMS2_SDB_BatSumS_State_of_Health 3 "Health_is_wrong" 2 "Health_is_good" 1 "Health_is_medium" 0 "Health_is_poor" ;
VAL_ 2566849954 BMS2_SDB_BatSumS_Temp_Alarm 3 "Wrong_Temperature_Alarm" 2 "High_Temperature_Alarm" 1 "Low_Temperature_Alarm" 0 "No_fault" ;
VAL_ 2566849954 BMS2_SDB_BatSumS_DischargeDis 1 "Discharge_Disable" 0 "Discharge_Enable" ;
VAL_ 2566849954 BMS2_SDB_BatSumS_ChargingDisable 1 "Charging_Disable" 0 "Charging_Enable" ;
VAL_ 2566849954 BMS2_SDB_BatSumS_HeaterEnabled 1 "Heater_Enabled" 0 "Heater_Disabled" ;
VAL_ 2566849954 BMS2_SDB_BatSumS_BypassEnabled 1 "Bypass_Enabled" 0 "Bypass_Disabled" ;
VAL_ 2566849954 BMS2_SDB_BatSumS_Voltage_Alarm 1 "Active" 0 "NotActive" ;
VAL_ 2566851234 BMS2_SDB_M3_Module_StateOfHealth 3 "Health_is_wrong" 2 "Health_is_good" 1 "Health_is_medium" 0 "Health_is_poor" ;
VAL_ 2566851234 BMS2_SDB_M3_DiscProtectTrigg 1 "Fault_Present" 0 "No_Fault" ;
VAL_ 2566851234 BMS2_SDB_M3_ChargeProtectTrigg 1 "Fault_Present" 0 "No_Fault" ;
VAL_ 2566851234 BMS2_SDB_M3_ModulesMissingFailed 1 "Fault_Present" 0 "No_Fault" ;
VAL_ 2566851234 BMS2_SDB_M3_OverTemp_detect 1 "Fault_Present" 0 "No_Fault" ;
VAL_ 2566851234 BMS2_SDB_M3_UnderVoltage_detect 1 "Fault_Present" 0 "No_Fault" ;
VAL_ 2566851234 BMS2_SDB_M3_OverVoltage_detected 1 "Fault_Present" 0 "No_Fault" ;
VAL_ 2566851234 BMS2_SDB_M3_Overload_detected 1 "Fault_Present" 0 "No_Fault" ;
VAL_ 2566851234 BMS2_SDB_M3_ShortCircuit_detect 1 "Fault_Present" 0 "No_Fault" ;
VAL_ 2566850978 BMS2_SDB_M2_Module_StateOfHealth 3 "Health_is_wrong" 2 "Health_is_good" 1 "Health_is_medium" 0 "Health_is_poor" ;
VAL_ 2566850978 BMS2_SDB_M2_DiscProtectTrigg 1 "Fault_Present" 0 "No_Fault" ;
VAL_ 2566850978 BMS2_SDB_M2_ChargeProtectTrigg 1 "Fault_Present" 0 "No_Fault" ;
VAL_ 2566850978 BMS2_SDB_M2_ModulesMissingFailed 1 "Fault_Present" 0 "No_Fault" ;
VAL_ 2566850978 BMS2_SDB_M2_OverTemp_detect 1 "Fault_Present" 0 "No_Fault" ;
VAL_ 2566850978 BMS2_SDB_M2_UnderVoltage_detect 1 "Fault_Present" 0 "No_Fault" ;
VAL_ 2566850978 BMS2_SDB_M2_OverVoltage_detected 1 "Fault_Present" 0 "No_Fault" ;
VAL_ 2566850978 BMS2_SDB_M2_Overload_detected 1 "Fault_Present" 0 "No_Fault" ;
VAL_ 2566850978 BMS2_SDB_M2_ShortCircuit_detect 1 "Fault_Present" 0 "No_Fault" ;
VAL_ 2566850722 BMS2_SDB_M1_Module_StateOfHealth 3 "Health_is_wrong" 2 "Health_is_good" 1 "Health_is_medium" 0 "Health_is_poor" ;
VAL_ 2566850722 BMS2_SDB_M1_DiscProtectTrigg 1 "Fault_Present" 0 "No_Fault" ;
VAL_ 2566850722 BMS2_SDB_M1_ChargeProtectTrigg 1 "Fault_Present" 0 "No_Fault" ;
VAL_ 2566850722 BMS2_SDB_M1_ModulesMissingFailed 1 "Fault_Present" 0 "No_Fault" ;
VAL_ 2566850722 BMS2_SDB_M1_OverTemp_detect 1 "Fault_Present" 0 "No_Fault" ;
VAL_ 2566850722 BMS2_SDB_M1_UnderVoltage_detect 1 "Fault_Present" 0 "No_Fault" ;
VAL_ 2566850722 BMS2_SDB_M1_OverVoltage_detected 1 "Fault_Present" 0 "No_Fault" ;
VAL_ 2566850722 BMS2_SDB_M1_Overload_detected 1 "Fault_Present" 0 "No_Fault" ;
VAL_ 2566850722 BMS2_SDB_M1_ShortCircuit_detect 1 "Fault_Present" 0 "No_Fault" ;
VAL_ 2566848930 BMS2_SDB_Overall_10_alarm 1 "Alarm_ON" 0 "Alarm_OFF" ;
VAL_ 2566848930 BMS2_SDB_Silent_Watch_20_alarm 1 "Alarm_ON" 0 "Alarm_OFF" ;
VAL_ 2566848930 BMS2_SDB_EngStartCapacity_alarm 1 "Alarm_ON" 0 "Alarm_OFF" ;
VAL_ 2566848674 BMS2_SDB_Batt_StsOfHealth 3 "Health_is_wrong" 2 "Health_is_good" 1 "Health_is_medium" 0 "Health_is_poor" ;
VAL_ 2566848674 BMS2_SDB_Batt_PS8_discharge_prot 1 "Fault_Present" 0 "No_Fault" ;
VAL_ 2566848674 BMS2_SDB_Batt_PS7_charge_prot 1 "Fault_Present" 0 "No_Fault" ;
VAL_ 2566848674 BMS2_SDB_Batt_PS6_mod_failed 1 "Fault_Present" 0 "No_Fault" ;
VAL_ 2566848674 BMS2_SDB_Batt_PS5_over_temp 1 "Fault_Present" 0 "No_Fault" ;
VAL_ 2566848674 BMS2_SDB_Batt_PS4_under_voltage 1 "Fault_Present" 0 "No_Fault" ;
VAL_ 2566848674 BMS2_SDB_Batt_PS3_over_voltage 1 "Fault_Present" 0 "No_Fault" ;
VAL_ 2566848674 BMS2_SDB_Batt_PS2_overload 1 "Fault_Present" 0 "No_Fault" ;
VAL_ 2566848674 BMS2_SDB_Batt_PS1_short_circuit 1 "Fault_Present" 0 "No_Fault" ;
VAL_ 2566848674 BMS2_SDB_Batt_OS_8_sleep_mode 1 "Sleep_pending" 0 "Awake" ;
VAL_ 2566848674 BMS2_SDB_Batt_OS_7_emerg_used 1 "used" 0 "never_used" ;
VAL_ 2566848674 BMS2_SDB_Batt_OS_6_emergency 1 "Active" 0 "NotActive" ;
VAL_ 2566848674 BMS2_SDB_Batt_OS_45_charge_level 3 "100%" 2 "50%" 1 "25%" 0 "OFF" ;
VAL_ 2566848674 BMS2_SDB_Batt_OS_3_charge_cont 1 "ON" 0 "OFF" ;
VAL_ 2566848674 BMS2_SDB_Batt_OS_2_heater_cont 1 "ON" 0 "OFF" ;
VAL_ 2566848674 BMS2_SDB_Batt_OS_1_master_prot 1 "Protect" 0 "OFF" ;
VAL_ 2566850046 BMS0_SDB_BatSumS_State_of_Health 3 "Health_is_wrong" 2 "Health_is_good" 1 "Health_is_medium" 0 "Health_is_poor" ;
VAL_ 2566850046 BMS0_SDB_BatSumS_Temp_Alarm 3 "Wrong_Temperature_Alarm" 2 "High_Temperature_Alarm" 1 "Low_Temperature_Alarm" 0 "No_fault" ;
VAL_ 2566850046 BMS0_SDB_BatSumS_DischargeDis 1 "Discharge_Disable" 0 "Discharge_Enable" ;
VAL_ 2566850046 BMS0_SDB_BatSumS_ChargingDisable 1 "Charging_Disable" 0 "Charging_Enable" ;
VAL_ 2566850046 BMS0_SDB_BatSumS_HeaterEnabled 1 "Heater_Enabled" 0 "Heater_Disabled" ;
VAL_ 2566850046 BMS0_SDB_BatSumS_BypassEnabled 1 "Bypass_Enabled" 0 "Bypass_Disabled" ;
VAL_ 2566850046 BMS0_SDB_BatSumS_Voltage_Alarm 1 "Active" 0 "NotActive" ;
SIG_VALTYPE_ 2558721985 Radiation : 1;
SIG_VALTYPE_ 2558721985 Radiation_Rate : 1;
